VERSION "HNNBNNNYNNNNNNNNNNNNNNNNNNNNNNNNNNNNNNNNNN/4/%%%/4/'%**4NNN///"

NS_ :

BS_:

BU_: AWC BAP_Tester BMC_MLBevo BMS_MV BMS_NV DCDC_800V_PAG DCDC_HV DCDC_HV_02 DCDC_IHEV FCU_MLBevo_FCEV Gateway Gateway_PAG Ladegeraet_2 Ladegeraet_Konzern LE1 LE2 LE2_3_MLBevo_LB LE_MLBevo LE_MLBevo_LB Sub_Gateway TME

BO_ 3221225472 VECTOR__INDEPENDENT_SIG_MSG: 0 Vector__XXX
 SG_ DGN_Verlernzaehler : 0|8@1+ (1,0) [0|254] "" Vector__XXX
 SG_ KBI_Kilometerstand : 0|20@1+ (1,0) [0|1048573] "Unit_KiloMeter" Vector__XXX
 SG_ UH_Jahr : 0|7@1+ (1,2000) [2000|2127] "Unit_Year" Vector__XXX
 SG_ UH_Monat : 0|4@1+ (1,0) [1|12] "Unit_Month" Vector__XXX
 SG_ UH_Tag : 0|5@1+ (1,0) [1|31] "Unit_Day" Vector__XXX
 SG_ UH_Stunde : 0|5@1+ (1,0) [0|23] "Unit_Hours" Vector__XXX
 SG_ UH_Minute : 0|6@1+ (1,0) [0|59] "Unit_Minut" Vector__XXX
 SG_ UH_Sekunde : 0|6@1+ (1,0) [0|59] "Unit_Secon" Vector__XXX
 SG_ Kombi_02_alt : 0|1@1+ (1,0) [0|1] "" Vector__XXX
 SG_ Uhrzeit_01_alt : 0|1@1+ (1,0) [0|1] "" Vector__XXX
 SG_ EMG_CALID_CVN_MUX : 0|2@1+ (1,0) [0|3] "Unit_None" Vector__XXX
 SG_ EMG_CVN_VLD : 0|1@1+ (1,0) [0|1] "" Vector__XXX
 SG_ EMG_CALID_Index_01 : 0|8@1+ (1,0) [0|255] "" Vector__XXX
 SG_ EMG_CALID_Index_05 : 0|8@1+ (1,0) [0|255] "" Vector__XXX
 SG_ EMG_CALID_Index_09 : 0|8@1+ (1,0) [0|255] "" Vector__XXX
 SG_ EMG_CALID_Index_13 : 0|8@1+ (1,0) [0|255] "" Vector__XXX
 SG_ EMG_CALID_Index_02 : 0|8@1+ (1,0) [0|255] "" Vector__XXX
 SG_ EMG_CALID_Index_06 : 0|8@1+ (1,0) [0|255] "" Vector__XXX
 SG_ EMG_CALID_Index_10 : 0|8@1+ (1,0) [0|255] "" Vector__XXX
 SG_ EMG_CALID_Index_14 : 0|8@1+ (1,0) [0|255] "" Vector__XXX
 SG_ EMG_CALID_Index_03 : 0|8@1+ (1,0) [0|255] "" Vector__XXX
 SG_ EMG_CALID_Index_07 : 0|8@1+ (1,0) [0|255] "" Vector__XXX
 SG_ EMG_CALID_Index_11 : 0|8@1+ (1,0) [0|255] "" Vector__XXX
 SG_ EMG_CALID_Index_15 : 0|8@1+ (1,0) [0|255] "" Vector__XXX
 SG_ EMG_CALID_Index_04 : 0|8@1+ (1,0) [0|255] "" Vector__XXX
 SG_ EMG_CALID_Index_08 : 0|8@1+ (1,0) [0|255] "" Vector__XXX
 SG_ EMG_CALID_Index_12 : 0|8@1+ (1,0) [0|255] "" Vector__XXX
 SG_ EMG_CALID_Index_16 : 0|8@1+ (1,0) [0|255] "" Vector__XXX
 SG_ EMG_CVN_Byte_1 : 0|8@1+ (1,0) [0|255] "" Vector__XXX
 SG_ EMG_CVN_Byte_2 : 0|8@1+ (1,0) [0|255] "" Vector__XXX
 SG_ EMG_CVN_Byte_3 : 0|8@1+ (1,0) [0|255] "" Vector__XXX
 SG_ EMG_CVN_Byte_4 : 0|8@1+ (1,0) [0|255] "" Vector__XXX
 SG_ EMG_Komponentenfehler_01 : 0|2@1+ (1,0) [0|3] "" Vector__XXX
 SG_ EMG_Komponentenfehler_02 : 0|2@1+ (1,0) [0|3] "" Vector__XXX
 SG_ EMG_Komponentenfehler_03 : 0|2@1+ (1,0) [0|3] "" Vector__XXX
 SG_ EMG_Komponentenfehler_04 : 0|2@1+ (1,0) [0|3] "" Vector__XXX
 SG_ EMG_Komponentenfehler_05 : 0|2@1+ (1,0) [0|3] "" Vector__XXX
 SG_ EMG_Komponentenfehler_06 : 0|2@1+ (1,0) [0|3] "" Vector__XXX
 SG_ EMG_Komponentenfehler_07 : 0|2@1+ (1,0) [0|3] "" Vector__XXX
 SG_ EMG_Komponentenfehler_08 : 0|2@1+ (1,0) [0|3] "" Vector__XXX
 SG_ EMG_Komponentenfehler_09 : 0|2@1+ (1,0) [0|3] "" Vector__XXX
 SG_ EMG_Komponentenfehler_VLD : 0|1@1+ (1,0) [0|1] "" Vector__XXX
 SG_ ESP_21_CRC : 0|8@1+ (1,0) [0|255] "" Vector__XXX
 SG_ ESP_21_BZ : 0|4@1+ (1,0) [0|15] "" Vector__XXX
 SG_ BR_Eingriffsmoment : 0|10@1+ (1,-509) [-509|509] "" Vector__XXX
 SG_ ESP_Diagnose : 0|1@1+ (1,0) [0|1] "" Vector__XXX
 SG_ ESC_v_Signal_Qualifier_High_Low : 0|3@1+ (1,0) [0|7] "" Vector__XXX
 SG_ ESP_Vorsteuerung : 0|1@1+ (1,0) [0|1] "" Vector__XXX
 SG_ OBD_Schlechtweg : 0|1@1+ (1,0) [0|1] "" Vector__XXX
 SG_ OBD_QBit_Schlechtweg : 0|1@1+ (1,0) [0|1] "" Vector__XXX
 SG_ ESP_v_Signal : 0|16@1+ (0.01,0) [0|655.32] "Unit_KiloMeterPerHour" Vector__XXX
 SG_ ASR_Tastung_passiv : 0|1@1+ (1,0) [0|1] "" Vector__XXX
 SG_ ESP_Tastung_passiv : 0|1@1+ (1,0) [0|1] "" Vector__XXX
 SG_ ESP_Systemstatus : 0|1@1+ (1,0) [0|1] "" Vector__XXX
 SG_ ASR_Schalteingriff : 0|2@1+ (1,0) [0|3] "" Vector__XXX
 SG_ ESP_QBit_v_Signal : 0|1@1+ (1,0) [0|1] "" Vector__XXX
 SG_ ABS_Bremsung : 0|1@1+ (1,0) [0|1] "" Vector__XXX
 SG_ ASR_Anf : 0|1@1+ (1,0) [0|1] "" Vector__XXX
 SG_ MSR_Anf : 0|1@1+ (1,0) [0|1] "" Vector__XXX
 SG_ EBV_Eingriff : 0|1@1+ (1,0) [0|1] "" Vector__XXX
 SG_ EDS_Eingriff : 0|1@1+ (1,0) [0|1] "" Vector__XXX
 SG_ ESP_Eingriff : 0|1@1+ (1,0) [0|1] "" Vector__XXX
 SG_ ESP_ASP : 0|1@1+ (1,0) [0|1] "" Vector__XXX
 SG_ ESC_Neutralschaltung : 0|1@1+ (1,0) [0|1] "" Vector__XXX
 SG_ SI_Sammel_SG_Fehler : 0|6@1+ (1,0) [0|60] "" Vector__XXX
 SG_ SI_Diagnose_Aktiv : 0|1@1+ (1,0) [0|1] "" Vector__XXX
 SG_ SI_QRS_Mode : 0|1@1+ (1,0) [0|1] "" Vector__XXX
 SG_ SI_T_Mode : 0|1@1+ (1,0) [0|1] "" Vector__XXX
 SG_ SI_NWDF : 0|1@1+ (1,0) [0|1] "" Vector__XXX
 SG_ SI_NWDF_gueltig : 0|1@1+ (1,0) [0|1] "" Vector__XXX
 SG_ SI_Sammelfehler : 0|1@1+ (1,0) [0|1] "" Vector__XXX
 SG_ GW_KD_Fehler : 0|1@1+ (1,0) [0|1] "" Vector__XXX
 SG_ SI_T_Schutz : 0|1@1+ (1,0) [0|1] "" Vector__XXX
 SG_ SI_BUS_01 : 0|1@1+ (1,0) [0|1] "" Vector__XXX
 SG_ SI_BUS_02 : 0|1@1+ (1,0) [0|1] "" Vector__XXX
 SG_ SI_BUS_03 : 0|1@1+ (1,0) [0|1] "" Vector__XXX
 SG_ SI_BUS_04 : 0|1@1+ (1,0) [0|1] "" Vector__XXX
 SG_ SI_BUS_05 : 0|1@1+ (1,0) [0|1] "" Vector__XXX
 SG_ SI_BUS_06 : 0|1@1+ (1,0) [0|1] "" Vector__XXX
 SG_ SI_BUS_07 : 0|1@1+ (1,0) [0|1] "" Vector__XXX
 SG_ SI_BUS_08 : 0|1@1+ (1,0) [0|1] "" Vector__XXX
 SG_ SI_BUS_09 : 0|1@1+ (1,0) [0|1] "" Vector__XXX
 SG_ SI_BUS_10 : 0|1@1+ (1,0) [0|1] "" Vector__XXX
 SG_ SI_BUS_11 : 0|1@1+ (1,0) [0|1] "" Vector__XXX
 SG_ SI_BUS_12 : 0|1@1+ (1,0) [0|1] "" Vector__XXX
 SG_ SI_BUS_13 : 0|1@1+ (1,0) [0|1] "" Vector__XXX
 SG_ SI_BUS_14 : 0|1@1+ (1,0) [0|1] "" Vector__XXX
 SG_ SI_BUS_15 : 0|1@1+ (1,0) [0|1] "" Vector__XXX
 SG_ SI_Bus_Identifikation : 0|8@1+ (1,0) [0|255] "" Vector__XXX
 SG_ SI_CAB : 0|24@1+ (1,0) [0|16777215] "" Vector__XXX
 SG_ XCP_BMS_MV_CRO_01_Data : 0|64@1+ (1,0) [0|1] "" Vector__XXX

BO_ 64 Airbag_01: 8 Gateway
 SG_ Airbag_01_CRC : 0|8@1+ (1,0) [0|255] ""  AWC,BMC_MLBevo,BMS_NV,DCDC_800V_PAG,DCDC_HV,DCDC_HV_02,DCDC_IHEV,FCU_MLBevo_FCEV,Ladegeraet_2,Ladegeraet_Konzern,Sub_Gateway
 SG_ Airbag_01_BZ : 8|4@1+ (1,0) [0|15] ""  AWC,BMC_MLBevo,BMS_NV,DCDC_800V_PAG,DCDC_HV,DCDC_HV_02,DCDC_IHEV,FCU_MLBevo_FCEV,Ladegeraet_2,Ladegeraet_Konzern,Sub_Gateway
 SG_ AB_RGS_Anst : 12|4@1+ (1,0) [0|15] ""  FCU_MLBevo_FCEV,Sub_Gateway
 SG_ AB_Front_Crash : 16|1@1+ (1,0) [0|1] ""  FCU_MLBevo_FCEV,Sub_Gateway
 SG_ AB_Heck_Crash : 17|1@1+ (1,0) [0|1] ""  FCU_MLBevo_FCEV,Sub_Gateway
 SG_ AB_SF_Crash : 18|1@1+ (1,0) [0|1] ""  FCU_MLBevo_FCEV,Sub_Gateway
 SG_ AB_SB_Crash : 19|1@1+ (1,0) [0|1] ""  FCU_MLBevo_FCEV,Sub_Gateway
 SG_ AB_Rollover_Crash : 20|1@1+ (1,0) [0|1] ""  FCU_MLBevo_FCEV,Sub_Gateway
 SG_ AB_Crash_Int : 21|3@1+ (1,0) [0|7] ""  FCU_MLBevo_FCEV,Sub_Gateway,TME
 SG_ AB_Lampe : 24|1@1+ (1,0) [0|1] ""  FCU_MLBevo_FCEV,Sub_Gateway
 SG_ AB_Deaktiviert : 25|1@1+ (1,0) [0|1] ""  FCU_MLBevo_FCEV,Sub_Gateway
 SG_ AB_VB_deaktiviert : 26|1@1+ (1,0) [0|1] ""  FCU_MLBevo_FCEV,Sub_Gateway
 SG_ AB_Systemfehler : 27|1@1+ (1,0) [0|1] ""  FCU_MLBevo_FCEV,Sub_Gateway
 SG_ AB_Diagnose : 28|1@1+ (1,0) [0|1] ""  FCU_MLBevo_FCEV,Sub_Gateway
 SG_ AB_Stellgliedtest : 29|1@1+ (1,0) [0|1] ""  FCU_MLBevo_FCEV,Sub_Gateway,TME
 SG_ AB_Erh_Auf_VB : 30|2@1+ (1,0) [0|3] ""  FCU_MLBevo_FCEV,Sub_Gateway
 SG_ AB_Gurtwarn_VF : 32|1@1+ (1,0) [0|1] ""  FCU_MLBevo_FCEV,Sub_Gateway
 SG_ AB_Gurtwarn_VB : 33|1@1+ (1,0) [0|1] ""  FCU_MLBevo_FCEV,Sub_Gateway
 SG_ AB_Anzeige_Fussg : 34|2@1+ (1,0) [0|3] ""  FCU_MLBevo_FCEV,Sub_Gateway
 SG_ AB_Texte_AKS : 36|2@1+ (1,0) [0|3] ""  FCU_MLBevo_FCEV,Sub_Gateway
 SG_ AB_MKB_gueltig : 39|1@1+ (1,0) [0|1] ""  FCU_MLBevo_FCEV,Sub_Gateway
 SG_ AB_MKB_Anforderung : 40|1@1+ (1,0) [0|1] ""  FCU_MLBevo_FCEV,Sub_Gateway
 SG_ AB_Versorgungsspannung : 41|1@1+ (1,0) [0|1] ""  FCU_MLBevo_FCEV,Sub_Gateway
 SG_ AB_Deaktivierung_HV : 42|3@1+ (1,0) [0|7] ""  AWC,BMC_MLBevo,BMS_NV,DCDC_800V_PAG,DCDC_HV,DCDC_HV_02,DCDC_IHEV,FCU_MLBevo_FCEV,Ladegeraet_2,Ladegeraet_Konzern,Sub_Gateway,TME
 SG_ AB_EDR_Trigger : 45|2@1+ (1,0) [0|3] ""  FCU_MLBevo_FCEV,Sub_Gateway
 SG_ AB_Belegung_VF : 47|2@1+ (1,0) [0|3] ""  FCU_MLBevo_FCEV,Sub_Gateway
 SG_ SC_Masterzeit_Offset : 53|2@1+ (5.08,0) [0|15.24] "Unit_Secon"  FCU_MLBevo_FCEV,Sub_Gateway
 SG_ SC_LowSpeedCrashErkannt : 55|2@1+ (1,0) [0|3] ""  FCU_MLBevo_FCEV,Sub_Gateway
 SG_ SC_Masterzeit : 57|7@1+ (0.04,0) [0|5.04] "Unit_Secon"  FCU_MLBevo_FCEV,Sub_Gateway

BO_ 2589283757 Authentic_Time_01: 8 Gateway
 SG_ AT_VALID_TIME : 32|32@1+ (1,0) [1|4294967295] ""  Ladegeraet_Konzern

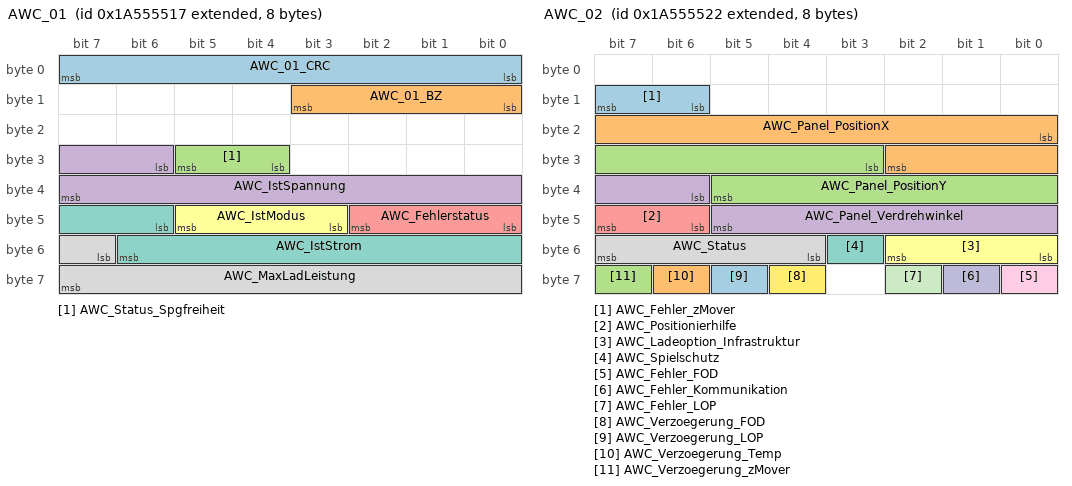
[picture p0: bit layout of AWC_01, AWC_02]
BO_ 2589283607 AWC_01: 8 AWC
 SG_ AWC_01_CRC : 0|8@1+ (1,0) [0|255] ""  Gateway,Gateway_PAG
 SG_ AWC_01_BZ : 8|4@1+ (1,0) [0|15] ""  Gateway,Gateway_PAG
 SG_ AWC_Status_Spgfreiheit : 28|2@1+ (1,0) [0|3] ""  Gateway,Gateway_PAG
 SG_ AWC_IstSpannung : 30|10@1+ (1,0) [0|1021] "Unit_Volt"  Gateway,Gateway_PAG,Ladegeraet_Konzern
 SG_ AWC_Fehlerstatus : 40|3@1+ (1,0) [0|7] ""  Gateway,Gateway_PAG
 SG_ AWC_IstModus : 43|3@1+ (1,0) [0|7] ""  Gateway,Gateway_PAG,Ladegeraet_Konzern,TME
 SG_ AWC_IstStrom : 46|9@1+ (0.1,0) [0|50.9] "Unit_Amper"  Ladegeraet_Konzern
 SG_ AWC_MaxLadLeistung : 55|9@1+ (25,0) [0|12725] "Unit_Watt"  Ladegeraet_Konzern

BO_ 2589283618 AWC_02: 8 AWC
 SG_ AWC_Fehler_zMover : 14|2@1+ (1,0) [0|3] ""  Gateway,Gateway_PAG,Ladegeraet_Konzern
 SG_ AWC_Panel_PositionX : 16|11@1+ (1,-1000) [-1000|1000] "Unit_Centimeter"  Gateway,Gateway_PAG
 SG_ AWC_Panel_PositionY : 27|11@1+ (1,-1000) [-1000|1000] "Unit_Centimeter"  Gateway,Gateway_PAG
 SG_ AWC_Panel_Verdrehwinkel : 38|8@1+ (1.5,0) [0|360] "Unit_DegreOfArc"  Gateway,Gateway_PAG
 SG_ AWC_Positionierhilfe : 46|2@1+ (1,0) [0|3] ""  Gateway,Gateway_PAG
 SG_ AWC_Ladeoption_Infrastruktur : 48|3@1+ (1,0) [0|7] ""  Gateway,Gateway_PAG,Ladegeraet_Konzern
 SG_ AWC_Spielschutz : 51|1@1+ (1,0) [0|1] ""  Gateway,Gateway_PAG,Ladegeraet_Konzern
 SG_ AWC_Status : 52|4@1+ (1,0) [0|15] ""  Gateway,Gateway_PAG,Ladegeraet_Konzern
 SG_ AWC_Fehler_FOD : 56|1@1+ (1,0) [0|1] ""  Gateway,Gateway_PAG,Ladegeraet_Konzern
 SG_ AWC_Fehler_Kommunikation : 57|1@1+ (1,0) [0|1] ""  Gateway,Gateway_PAG,Ladegeraet_Konzern
 SG_ AWC_Fehler_LOP : 58|1@1+ (1,0) [0|1] ""  Gateway,Gateway_PAG,Ladegeraet_Konzern
 SG_ AWC_Verzoegerung_FOD : 60|1@1+ (1,0) [0|1] ""  Gateway,Gateway_PAG,Ladegeraet_Konzern
 SG_ AWC_Verzoegerung_LOP : 61|1@1+ (1,0) [0|1] ""  Gateway,Gateway_PAG,Ladegeraet_Konzern
 SG_ AWC_Verzoegerung_Temp : 62|1@1+ (1,0) [0|1] ""  Gateway,Gateway_PAG,Ladegeraet_Konzern
 SG_ AWC_Verzoegerung_zMover : 63|1@1+ (1,0) [0|1] ""  Gateway,Gateway_PAG,Ladegeraet_Konzern

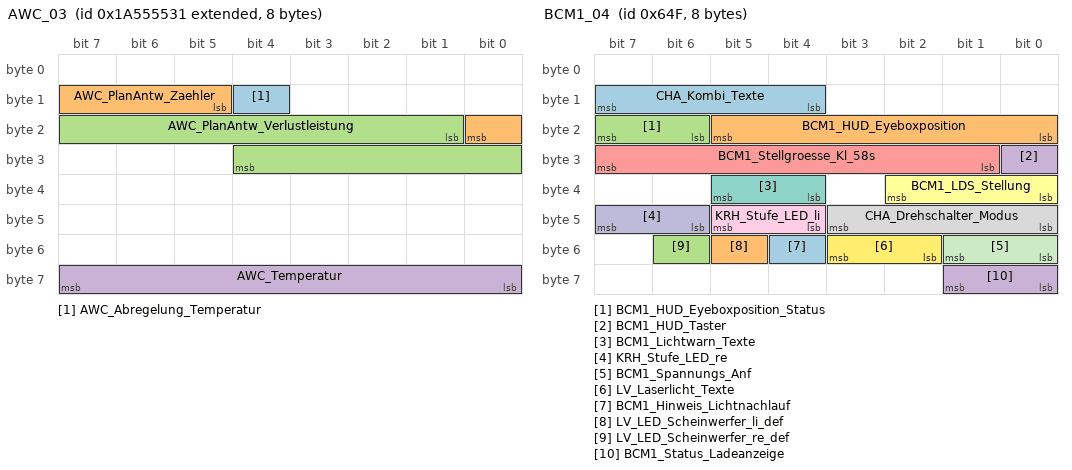
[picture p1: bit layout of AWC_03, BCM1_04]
BO_ 2589283633 AWC_03: 8 AWC
 SG_ AWC_Abregelung_Temperatur : 12|1@1+ (1,0) [0|1] ""  TME
 SG_ AWC_PlanAntw_Zaehler : 13|4@1+ (1,0) [0|13] "Unit_None"  Ladegeraet_Konzern,TME
 SG_ AWC_PlanAntw_Verlustleistung : 17|12@1+ (50,0) [0|204650] "Unit_Watt"  Ladegeraet_Konzern,TME
 SG_ AWC_Temperatur : 56|8@1+ (1,-40) [-40|213] "Unit_DegreCelsi"  TME

BO_ 2589283685 AWC_CALID_CVN: 8 AWC
 SG_ AWC_CALID_CVN_MUX M : 0|2@1+ (1,0) [0|3] "Unit_None"  BMC_MLBevo
 SG_ AWC_CVN_VLD : 7|1@1+ (1,0) [0|1] ""  BMC_MLBevo
 SG_ AWC_CALID_Index_01 m0 : 8|8@1+ (1,0) [0|255] ""  BMC_MLBevo
 SG_ AWC_CALID_Index_05 m1 : 8|8@1+ (1,0) [0|255] ""  BMC_MLBevo
 SG_ AWC_CALID_Index_09 m2 : 8|8@1+ (1,0) [0|255] ""  BMC_MLBevo
 SG_ AWC_CALID_Index_13 m3 : 8|8@1+ (1,0) [0|255] ""  BMC_MLBevo
 SG_ AWC_CALID_Index_02 m0 : 16|8@1+ (1,0) [0|255] ""  BMC_MLBevo
 SG_ AWC_CALID_Index_06 m1 : 16|8@1+ (1,0) [0|255] ""  BMC_MLBevo
 SG_ AWC_CALID_Index_10 m2 : 16|8@1+ (1,0) [0|255] ""  BMC_MLBevo
 SG_ AWC_CALID_Index_14 m3 : 16|8@1+ (1,0) [0|255] ""  BMC_MLBevo
 SG_ AWC_CALID_Index_03 m0 : 24|8@1+ (1,0) [0|255] ""  BMC_MLBevo
 SG_ AWC_CALID_Index_07 m1 : 24|8@1+ (1,0) [0|255] ""  BMC_MLBevo
 SG_ AWC_CALID_Index_11 m2 : 24|8@1+ (1,0) [0|255] ""  BMC_MLBevo
 SG_ AWC_CALID_Index_15 m3 : 24|8@1+ (1,0) [0|255] ""  BMC_MLBevo
 SG_ AWC_CALID_Index_04 m0 : 32|8@1+ (1,0) [0|255] ""  BMC_MLBevo
 SG_ AWC_CALID_Index_08 m1 : 32|8@1+ (1,0) [0|255] ""  BMC_MLBevo
 SG_ AWC_CALID_Index_12 m2 : 32|8@1+ (1,0) [0|255] ""  BMC_MLBevo
 SG_ AWC_CALID_Index_16 m3 : 32|8@1+ (1,0) [0|255] ""  BMC_MLBevo
 SG_ AWC_CVN_Byte_1 m0 : 40|8@1+ (1,0) [0|255] ""  BMC_MLBevo
 SG_ AWC_CVN_Byte_2 m1 : 40|8@1+ (1,0) [0|255] ""  BMC_MLBevo
 SG_ AWC_CVN_Byte_3 m2 : 40|8@1+ (1,0) [0|255] ""  BMC_MLBevo
 SG_ AWC_CVN_Byte_4 m3 : 40|8@1+ (1,0) [0|255] ""  BMC_MLBevo

BO_ 2589283394 AWC_Komponentenfehler: 8 AWC
 SG_ AWC_Komponentenfehler_01 : 0|2@1+ (1,0) [0|3] ""  BMC_MLBevo
 SG_ AWC_Komponentenfehler_02 : 2|2@1+ (1,0) [0|3] ""  BMC_MLBevo
 SG_ AWC_Komponentenfehler_03 : 4|2@1+ (1,0) [0|3] ""  BMC_MLBevo
 SG_ AWC_Komponentenfehler_04 : 6|2@1+ (1,0) [0|3] ""  BMC_MLBevo
 SG_ AWC_Komponentenfehler_05 : 8|2@1+ (1,0) [0|3] ""  BMC_MLBevo
 SG_ AWC_Komponentenfehler_06 : 10|2@1+ (1,0) [0|3] ""  BMC_MLBevo
 SG_ AWC_Komponentenfehler_07 : 12|2@1+ (1,0) [0|3] ""  BMC_MLBevo
 SG_ AWC_Komponentenfehler_08 : 14|2@1+ (1,0) [0|3] ""  BMC_MLBevo
 SG_ AWC_Komponentenfehler_09 : 16|2@1+ (1,0) [0|3] ""  BMC_MLBevo
 SG_ AWC_Komponentenfehler_10 : 18|2@1+ (1,0) [0|3] ""  BMC_MLBevo
 SG_ AWC_Komponentenfehler_11 : 20|2@1+ (1,0) [0|3] ""  BMC_MLBevo
 SG_ AWC_Komponentenfehler_12 : 22|2@1+ (1,0) [0|3] ""  BMC_MLBevo
 SG_ AWC_Komponentenfehler_13 : 24|2@1+ (1,0) [0|3] ""  BMC_MLBevo
 SG_ AWC_Komponentenfehler_14 : 26|2@1+ (1,0) [0|3] ""  BMC_MLBevo
 SG_ AWC_Komponentenfehler_15 : 28|2@1+ (1,0) [0|3] ""  BMC_MLBevo
 SG_ AWC_Komponentenfehler_16 : 30|2@1+ (1,0) [0|3] ""  BMC_MLBevo
 SG_ AWC_Komponentenfehler_17 : 32|2@1+ (1,0) [0|3] ""  BMC_MLBevo
 SG_ AWC_Komponentenfehler_18 : 34|2@1+ (1,0) [0|3] ""  BMC_MLBevo
 SG_ AWC_Komponentenfehler_19 : 36|2@1+ (1,0) [0|3] ""  BMC_MLBevo
 SG_ AWC_Komponentenfehler_20 : 38|2@1+ (1,0) [0|3] ""  BMC_MLBevo
 SG_ AWC_Komponentenfehler_21 : 40|2@1+ (1,0) [0|3] ""  BMC_MLBevo
 SG_ AWC_Komponentenfehler_22 : 42|2@1+ (1,0) [0|3] ""  BMC_MLBevo
 SG_ AWC_Komponentenfehler_23 : 44|2@1+ (1,0) [0|3] ""  BMC_MLBevo
 SG_ AWC_Komponentenfehler_24 : 46|2@1+ (1,0) [0|3] ""  BMC_MLBevo
 SG_ AWC_Komponentenfehler_25 : 48|2@1+ (1,0) [0|3] ""  BMC_MLBevo
 SG_ AWC_Komponentenfehler_26 : 50|2@1+ (1,0) [0|3] ""  BMC_MLBevo
 SG_ AWC_Komponentenfehler_27 : 52|2@1+ (1,0) [0|3] ""  BMC_MLBevo
 SG_ AWC_Komponentenfehler_28 : 54|2@1+ (1,0) [0|3] ""  BMC_MLBevo
 SG_ AWC_Komponentenfehler_29 : 56|2@1+ (1,0) [0|3] ""  BMC_MLBevo
 SG_ AWC_Komponentenfehler_30 : 58|2@1+ (1,0) [0|3] ""  BMC_MLBevo
 SG_ AWC_Komponentenfehler_31 : 60|2@1+ (1,0) [0|3] ""  BMC_MLBevo
 SG_ AWC_Komponentenfehler_VLD : 63|1@1+ (1,0) [0|1] ""  BMC_MLBevo

BO_ 2536720384 BAP_AWC_ASG_01: 8 Gateway
 SG_ BAP_AWC_ASG_01_Header : 0|8@1+ (1,0) [0|255] "Unit_None"  AWC

BO_ 2536720385 BAP_AWC_ASG_02: 8 Gateway
 SG_ BAP_AWC_ASG_02_Header : 0|64@1+ (1,0) [0|1.84467440737096E+019] ""  AWC

BO_ 2536720400 BAP_AWC_FSG_01: 8 AWC
 SG_ BAP_AWC_FSG_01_Header : 0|8@1+ (1,0) [0|255] "Unit_None"  Gateway,Gateway_PAG

BO_ 2536711424 BAP_BatteryControl_ASG_01: 8 Gateway
 SG_ BAP_BatteryControl_ASG_01_Header : 0|8@1+ (1,0) [0|255] ""  Ladegeraet_Konzern

BO_ 2536711425 BAP_BatteryControl_ASG_02: 8 Gateway
 SG_ BAP_BatteryControl_ASG_02_Header : 0|8@1+ (1,0) [0|255] ""  Ladegeraet_Konzern

BO_ 2536711426 BAP_BatteryControl_ASG_03: 8 Gateway
 SG_ BAP_BatteryControl_ASG_03_Header : 0|8@1+ (1,0) [0|255] ""  Ladegeraet_Konzern

BO_ 2536711427 BAP_BatteryControl_ASG_04: 8 Gateway
 SG_ BAP_BatteryControl_ASG_04_Header : 0|8@1+ (1,0) [0|255] ""  Ladegeraet_Konzern

BO_ 2536711428 BAP_BatteryControl_ASG_05: 8 AWC
 SG_ BAP_BatteryControl_ASG_05_Header : 0|8@1+ (1,0) [0|255] "Unit_None"  Ladegeraet_Konzern

BO_ 2536711429 BAP_BatteryControl_ASG_06: 8 Gateway
 SG_ BAP_BatteryControl_ASG_06_Header : 0|8@1+ (1,0) [0|255] ""  Ladegeraet_Konzern

BO_ 2536711440 BAP_BatteryControl_FSG_01: 8 Ladegeraet_Konzern
 SG_ BAP_BatteryControl_FSG_01_Header : 0|8@1+ (1,0) [0|255] ""  AWC,Gateway,Gateway_PAG

BO_ 2536767264 BAP_Debug_Cmd: 8 BAP_Tester
 SG_ BAP_Debug_Cmd : 0|16@1+ (1,0) [0|65535] ""  AWC,Gateway,Gateway_PAG,Ladegeraet_Konzern

BO_ 2536767280 BAP_Debug_Data: 8 AWC
 SG_ BAP_Debug_Data : 0|64@1+ (1,0) [0|1.84467440737096E+019] ""  BAP_Tester

BO_ 2536706306 BAP_Uhrzeit_ASG_03: 8 Ladegeraet_Konzern
 SG_ BAP_Uhrzeit_ASG_03_Header : 0|8@1+ (1,0) [0|255] ""  Gateway,Gateway_PAG

BO_ 2536706310 BAP_Uhrzeit_ASG_07: 8 AWC
 SG_ BAP_Uhrzeit_ASG_07_Header : 0|64@1+ (1,0) [0|1.84467440737096E+019] ""  Gateway,Gateway_PAG

BO_ 2536706320 BAP_Uhrzeit_FSG_01: 8 Gateway
 SG_ BAP_Uhrzeit_FSG_01_Header : 0|8@1+ (1,0) [0|255] ""  AWC,Ladegeraet_Konzern

BO_ 1615 BCM1_04: 8 Gateway
 SG_ CHA_Kombi_Texte : 12|4@1+ (1,0) [0|15] "" Vector__XXX
 SG_ BCM1_HUD_Eyeboxposition : 16|6@1+ (1,0) [0|63] "" Vector__XXX
 SG_ BCM1_HUD_Eyeboxposition_Status : 22|2@1+ (1,0) [0|3] "" Vector__XXX
 SG_ BCM1_HUD_Taster : 24|1@1+ (1,0) [0|1] "" Vector__XXX
 SG_ BCM1_Stellgroesse_Kl_58s : 25|7@1+ (1,0) [0|100] "" Vector__XXX
 SG_ BCM1_LDS_Stellung : 32|3@1+ (1,0) [0|7] "" Vector__XXX
 SG_ BCM1_Lichtwarn_Texte : 36|2@1+ (1,0) [0|3] "" Vector__XXX
 SG_ CHA_Drehschalter_Modus : 40|4@1+ (1,0) [0|15] "" Vector__XXX
 SG_ KRH_Stufe_LED_li : 44|2@1+ (1,0) [0|3] "" Vector__XXX
 SG_ KRH_Stufe_LED_re : 46|2@1+ (1,0) [0|3] "" Vector__XXX
 SG_ BCM1_Spannungs_Anf : 48|2@1+ (1,0) [0|3] "" Vector__XXX
 SG_ LV_Laserlicht_Texte : 50|2@1+ (1,0) [0|3] "" Vector__XXX
 SG_ BCM1_Hinweis_Lichtnachlauf : 52|1@1+ (1,0) [0|1] "" Vector__XXX
 SG_ LV_LED_Scheinwerfer_li_def : 53|1@1+ (1,0) [0|1] "" Vector__XXX
 SG_ LV_LED_Scheinwerfer_re_def : 54|1@1+ (1,0) [0|1] "" Vector__XXX
 SG_ BCM1_Status_Ladeanzeige : 56|2@1+ (1,0) [0|3] ""  Ladegeraet_Konzern

BO_ 1626 BCM_01: 8 Gateway
 SG_ BCM_Bremsbelag_Sensor : 12|1@1+ (1,0) [0|1] "" Vector__XXX
 SG_ BCM_Bremsfluessigkeit_Sensor : 13|1@1+ (1,0) [0|1] "" Vector__XXX
 SG_ BCM1_Licht_Warn : 14|1@1+ (1,0) [0|1] "" Vector__XXX
 SG_ BCM_Waschwasser_Sensor : 15|1@1+ (1,0) [0|1] "" Vector__XXX
 SG_ BCM_Kuehlmittel_Sensor : 16|1@1+ (1,0) [0|1] ""  TME
 SG_ BCM1_Kl_15_HW_erkannt : 17|1@1+ (1,0) [0|1] "" Vector__XXX
 SG_ BCM1_Kl_15_Sig_HW_erkannt : 18|1@1+ (1,0) [0|1] "" Vector__XXX
 SG_ BCM_Kuehlmittel_Sensor_02 : 19|1@1+ (1,0) [0|1] ""  TME
 SG_ BCM1_Hinweis_Lichtnachlauf : 20|1@1+ (1,0) [0|1] "" Vector__XXX
 SG_ BCM_Offroad_Taste : 21|1@1+ (1,0) [0|1] "" Vector__XXX
 SG_ BCM_Hybrid_StSt_Taste_Fehler : 23|1@1+ (1,0) [0|1] "" Vector__XXX
 SG_ BCM_Hybrid_StartStopp_Taste : 24|1@1+ (1,0) [0|1] "" Vector__XXX
 SG_ BCM1_Warnblink_Taster : 25|1@1+ (1,0) [0|1] "" Vector__XXX
 SG_ BCM1_Valet_Parking_Taster : 26|1@1+ (1,0) [0|1] "" Vector__XXX
 SG_ BCM1_LDS_Stellung : 27|3@1+ (1,0) [0|7] "" Vector__XXX
 SG_ BCM1_Rueckfahrlicht_Schalter : 30|1@1+ (1,0) [0|1] "" Vector__XXX
 SG_ BCM1_MH_Schalter : 31|1@1+ (1,0) [0|1] "" Vector__XXX
 SG_ BCM1_MH_WIV_Schalter : 32|1@1+ (1,0) [0|1] "" Vector__XXX
 SG_ BCM_Eco_Charisma_Taste : 33|1@1+ (1,0) [0|1] "" Vector__XXX
 SG_ BCM1_NV_Taster : 34|1@1+ (1,0) [0|1] "" Vector__XXX
 SG_ BCM1_AFS_Lampe : 35|1@1+ (1,0) [0|1] "" Vector__XXX
 SG_ BCM1_Reisemodus_Texte : 36|2@1+ (1,0) [0|3] "" Vector__XXX
 SG_ BCM1_Lichtwarn_Texte : 38|2@1+ (1,0) [0|3] "" Vector__XXX
 SG_ Gong_TFL_Umschaltung : 40|1@1+ (1,0) [0|1] "" Vector__XXX
 SG_ UGDO_Function_01 : 41|3@1+ (1,0) [0|7] "" Vector__XXX
 SG_ APS_Tongeber_defekt : 44|1@1+ (1,0) [0|1] "" Vector__XXX
 SG_ BCM1_EasyEntry_Status : 45|1@1+ (1,0) [0|1] "" Vector__XXX
 SG_ BCM1_Lenksaeule_aktiv : 46|1@1+ (1,0) [0|1] "" Vector__XXX
 SG_ BCM1_St_SW_Diebstahl_links : 47|1@1+ (1,0) [0|1] "" Vector__XXX
 SG_ BCM1_St_SW_Diebstahl_rechts : 48|1@1+ (1,0) [0|1] "" Vector__XXX
 SG_ ISP_Dimmung_ASP_02 : 49|6@1+ (0.0226,0) [0|1.4012] "Unit_Volt" Vector__XXX
 SG_ BCM1_Schluesselsuche_Anf : 55|1@1+ (1,0) [0|1] "" Vector__XXX
 SG_ BCM1_Fahrlicht_Hinweis : 62|1@1+ (1,0) [0|1] "" Vector__XXX
 SG_ BCM_HDF_betaetigt : 63|1@1+ (1,0) [0|1] "" Vector__XXX

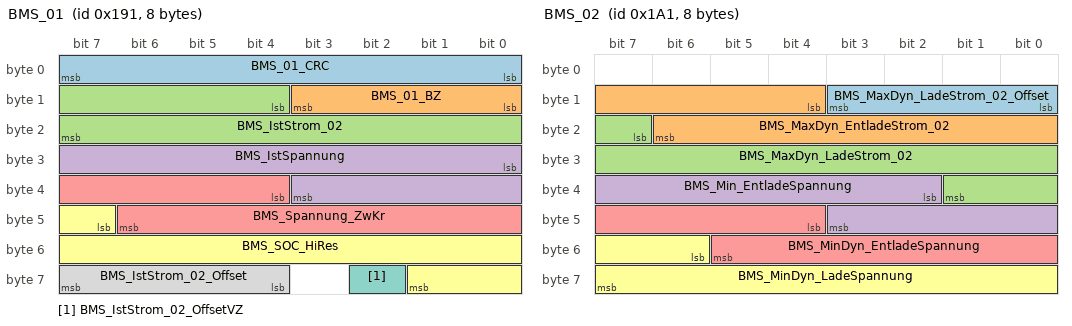
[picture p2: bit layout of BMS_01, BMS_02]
BO_ 401 BMS_01: 8 BMC_MLBevo
 SG_ BMS_01_CRC : 0|8@1+ (1,0) [0|255] ""  Gateway,Gateway_PAG,Sub_Gateway
 SG_ BMS_01_BZ : 8|4@1+ (1,0) [0|15] ""  Gateway,Gateway_PAG,Sub_Gateway
 SG_ BMS_IstStrom_02 : 12|12@1+ (1,-2047) [-2047|2046] "Unit_Amper"  Gateway,Gateway_PAG,Ladegeraet_Konzern,LE1,LE2,LE2_3_MLBevo_LB,Sub_Gateway,TME
 SG_ BMS_IstSpannung : 24|12@1+ (0.25,0) [0|1023.25] "Unit_Volt"  AWC,Gateway,Gateway_PAG,Ladegeraet_2,Ladegeraet_Konzern,LE1,LE2,LE2_3_MLBevo_LB,Sub_Gateway,TME
 SG_ BMS_Spannung_ZwKr : 36|11@1+ (0.5,0) [0|1022.5] "Unit_Volt"  Gateway,Gateway_PAG,LE1,LE2,LE2_3_MLBevo_LB,Sub_Gateway,TME
 SG_ BMS_SOC_HiRes : 47|11@1+ (0.05,0) [0|100] "Unit_PerCent"  Gateway,Gateway_PAG,Ladegeraet_Konzern,Sub_Gateway,TME
 SG_ BMS_IstStrom_02_OffsetVZ : 58|1@1+ (1,0) [0|1] ""  Gateway,Gateway_PAG,Ladegeraet_Konzern,Sub_Gateway
 SG_ BMS_IstStrom_02_Offset : 60|4@1+ (0.0625,0) [0|0.9375] "Unit_Amper"  Gateway,Gateway_PAG,Ladegeraet_Konzern,Sub_Gateway

BO_ 417 BMS_02: 8 BMC_MLBevo
 SG_ BMS_MaxDyn_LadeStrom_02_Offset : 8|4@1+ (0.0625,0) [0|0.9375] "Unit_Amper"  FCU_MLBevo_FCEV,Gateway,Gateway_PAG,Ladegeraet_Konzern
 SG_ BMS_MaxDyn_EntladeStrom_02 : 12|11@1+ (1,0) [0|2045] "Unit_Amper"  FCU_MLBevo_FCEV,Gateway,Gateway_PAG,LE2_3_MLBevo_LB
 SG_ BMS_MaxDyn_LadeStrom_02 : 23|11@1+ (1,0) [0|2045] "Unit_Amper"  FCU_MLBevo_FCEV,Gateway,Gateway_PAG,Ladegeraet_Konzern,LE2_3_MLBevo_LB
 SG_ BMS_Min_EntladeSpannung : 34|10@1+ (1,0) [0|1021] "Unit_Volt"  FCU_MLBevo_FCEV,Gateway,Gateway_PAG,Ladegeraet_Konzern,LE2_3_MLBevo_LB
 SG_ BMS_MinDyn_EntladeSpannung : 44|10@1+ (1,0) [0|1022] "Unit_Volt"  FCU_MLBevo_FCEV,Gateway,Gateway_PAG,LE2_3_MLBevo_LB
 SG_ BMS_MinDyn_LadeSpannung : 54|10@1+ (1,0) [0|1022] "Unit_Volt"  FCU_MLBevo_FCEV,Gateway,Gateway_PAG,LE2_3_MLBevo_LB

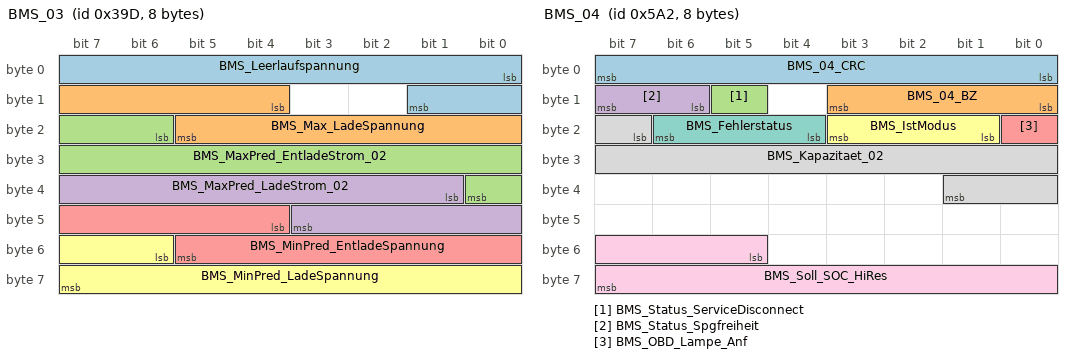
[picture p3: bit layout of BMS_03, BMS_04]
BO_ 925 BMS_03: 8 BMC_MLBevo
 SG_ BMS_Leerlaufspannung : 0|10@1+ (1,0) [0|1022] "Unit_Volt"  FCU_MLBevo_FCEV,Gateway,Gateway_PAG
 SG_ BMS_Max_LadeSpannung : 12|10@1+ (1,0) [0|1021] "Unit_Volt"  AWC,FCU_MLBevo_FCEV,Gateway,Gateway_PAG,Ladegeraet_2,Ladegeraet_Konzern,LE2_3_MLBevo_LB
 SG_ BMS_MaxPred_EntladeStrom_02 : 22|11@1+ (1,0) [0|2045] "Unit_Amper"  FCU_MLBevo_FCEV,Gateway,Gateway_PAG,LE2_3_MLBevo_LB
 SG_ BMS_MaxPred_LadeStrom_02 : 33|11@1+ (1,0) [0|2045] "Unit_Amper"  FCU_MLBevo_FCEV,Gateway,Gateway_PAG,Ladegeraet_Konzern,LE2_3_MLBevo_LB
 SG_ BMS_MinPred_EntladeSpannung : 44|10@1+ (1,0) [0|1022] "Unit_Volt"  FCU_MLBevo_FCEV,Gateway,Gateway_PAG,Ladegeraet_Konzern,LE2_3_MLBevo_LB
 SG_ BMS_MinPred_LadeSpannung : 54|10@1+ (1,0) [0|1022] "Unit_Volt"  FCU_MLBevo_FCEV,Gateway,Gateway_PAG,LE2_3_MLBevo_LB

BO_ 1442 BMS_04: 8 BMC_MLBevo
 SG_ BMS_04_CRC : 0|8@1+ (1,0) [0|255] ""  Gateway,Gateway_PAG,Sub_Gateway
 SG_ BMS_04_BZ : 8|4@1+ (1,0) [0|15] ""  Gateway,Gateway_PAG,Sub_Gateway
 SG_ BMS_Status_ServiceDisconnect : 13|1@1+ (1,0) [0|1] ""  DCDC_800V_PAG,DCDC_HV,Gateway,Gateway_PAG,Sub_Gateway
 SG_ BMS_Status_Spgfreiheit : 14|2@1+ (1,0) [0|3] ""  Gateway,Gateway_PAG,Sub_Gateway
 SG_ BMS_OBD_Lampe_Anf : 16|1@1+ (1,0) [0|1] ""  Gateway,Gateway_PAG,Sub_Gateway
 SG_ BMS_IstModus : 17|3@1+ (1,0) [0|7] ""  AWC,Gateway,Gateway_PAG,Ladegeraet_Konzern,LE1,LE2,LE2_3_MLBevo_LB,Sub_Gateway,TME
 SG_ BMS_Fehlerstatus : 20|3@1+ (1,0) [0|7] ""  AWC,DCDC_800V_PAG,DCDC_HV,Gateway,Gateway_PAG,Ladegeraet_Konzern,Sub_Gateway
 SG_ BMS_Kapazitaet_02 : 23|11@1+ (0.2,0) [0|409.2] "Unit_AmperHour"  Gateway,Gateway_PAG,Ladegeraet_Konzern,Sub_Gateway
 SG_ BMS_Soll_SOC_HiRes : 53|11@1+ (0.05,0) [0|100] "Unit_PerCent"  Gateway,Gateway_PAG,Sub_Gateway

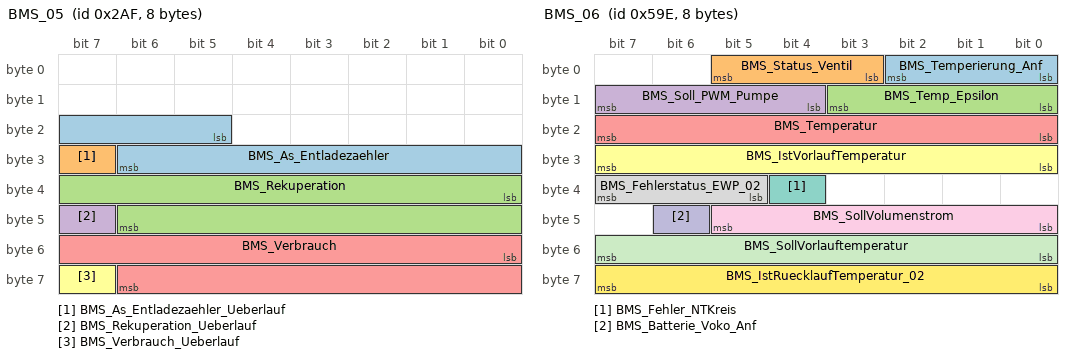
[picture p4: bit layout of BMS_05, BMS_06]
BO_ 687 BMS_05: 8 BMC_MLBevo
 SG_ BMS_As_Entladezaehler : 21|10@1+ (1,0) [0|1023] "Unit_AmperSecon"  Gateway,Gateway_PAG
 SG_ BMS_As_Entladezaehler_Ueberlauf : 31|1@1+ (1,0) [0|1] ""  Gateway,Gateway_PAG
 SG_ BMS_Rekuperation : 32|15@1+ (10,0) [0|327670] "Unit_WattSecond"  Gateway,Gateway_PAG
 SG_ BMS_Rekuperation_Ueberlauf : 47|1@1+ (1,0) [0|1] ""  Gateway,Gateway_PAG
 SG_ BMS_Verbrauch : 48|15@1+ (10,0) [0|327670] "Unit_WattSecond"  Gateway,Gateway_PAG
 SG_ BMS_Verbrauch_Ueberlauf : 63|1@1+ (1,0) [0|1] ""  Gateway,Gateway_PAG

BO_ 1438 BMS_06: 8 BMC_MLBevo
 SG_ BMS_Temperierung_Anf : 0|3@1+ (1,0) [0|7] ""  Gateway,Gateway_PAG,TME
 SG_ BMS_Status_Ventil : 3|3@1+ (1,0) [0|7] ""  Gateway,Gateway_PAG
 SG_ BMS_Temp_Epsilon : 8|4@1+ (1,-15) [-15|0] "Unit_DegreCelsi"  Gateway,Gateway_PAG,TME
 SG_ BMS_Soll_PWM_Pumpe : 12|4@1+ (10,0) [0|100] "Unit_PerCent"  Gateway,Gateway_PAG,TME
 SG_ BMS_Temperatur : 16|8@1+ (0.5,-40) [-40|86.5] "Unit_DegreCelsi"  Gateway,Gateway_PAG,Ladegeraet_Konzern,TME
 SG_ BMS_IstVorlaufTemperatur : 24|8@1+ (0.5,-40) [-40|86.5] "Unit_DegreCelsi"  Gateway,Gateway_PAG,TME
 SG_ BMS_Fehler_NTKreis : 36|1@1+ (1,0) [0|1] ""  Gateway,Gateway_PAG
 SG_ BMS_Fehlerstatus_EWP_02 : 37|3@1+ (1,0) [0|7] ""  Gateway,Gateway_PAG,TME
 SG_ BMS_SollVolumenstrom : 40|6@1+ (1,0) [0|61] "Unit_LiterPerMinut"  Gateway,Gateway_PAG,TME
 SG_ BMS_Batterie_Voko_Anf : 46|1@1+ (1,0) [0|1] ""  Gateway,Gateway_PAG,Ladegeraet_Konzern,TME
 SG_ BMS_SollVorlauftemperatur : 48|8@1+ (0.5,-40) [-40|86.5] "Unit_DegreCelsi"  Gateway,Gateway_PAG,TME
 SG_ BMS_IstRuecklaufTemperatur_02 : 56|8@1+ (0.5,-40) [-40|86.5] "Unit_DegreCelsi"  Gateway,Gateway_PAG,TME

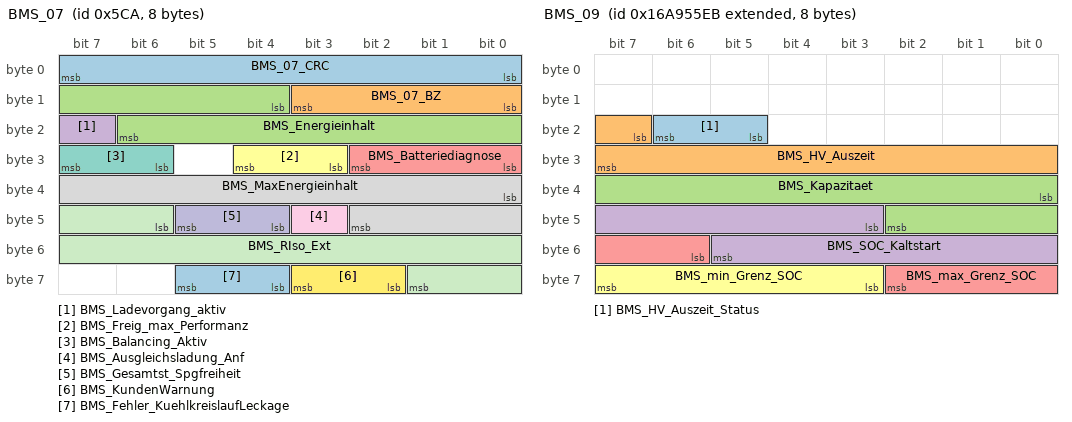
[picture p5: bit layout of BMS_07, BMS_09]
BO_ 1482 BMS_07: 8 BMC_MLBevo
 SG_ BMS_07_CRC : 0|8@1+ (1,0) [0|255] ""  Gateway,Gateway_PAG,Sub_Gateway
 SG_ BMS_07_BZ : 8|4@1+ (1,0) [0|15] ""  Gateway,Gateway_PAG,Sub_Gateway
 SG_ BMS_Energieinhalt : 12|11@1+ (50,0) [0|102250] "Unit_WattHour"  Gateway,Gateway_PAG,Ladegeraet_Konzern,Sub_Gateway,TME
 SG_ BMS_Ladevorgang_aktiv : 23|1@1+ (1,0) [0|1] ""  Gateway,Gateway_PAG,Sub_Gateway
 SG_ BMS_Batteriediagnose : 24|3@1+ (1,0) [0|7] ""  Gateway,Gateway_PAG,Sub_Gateway
 SG_ BMS_Freig_max_Performanz : 27|2@1+ (1,0) [0|3] ""  Gateway,Gateway_PAG,Sub_Gateway
 SG_ BMS_Balancing_Aktiv : 30|2@1+ (1,0) [0|3] ""  Gateway,Gateway_PAG,Sub_Gateway
 SG_ BMS_MaxEnergieinhalt : 32|11@1+ (50,0) [0|102250] "Unit_WattHour"  Gateway,Gateway_PAG,Ladegeraet_Konzern,Sub_Gateway,TME
 SG_ BMS_Ausgleichsladung_Anf : 43|1@1+ (1,0) [0|1] ""  Gateway,Gateway_PAG,Sub_Gateway
 SG_ BMS_Gesamtst_Spgfreiheit : 44|2@1+ (1,0) [0|3] ""  Gateway,Gateway_PAG,Sub_Gateway
 SG_ BMS_RIso_Ext : 46|12@1+ (5,0) [0|20465] "Unit_KiloOhm"  Gateway,Gateway_PAG,Sub_Gateway
 SG_ BMS_KundenWarnung : 58|2@1+ (1,0) [0|3] ""  Gateway,Gateway_PAG,Sub_Gateway
 SG_ BMS_Fehler_KuehlkreislaufLeckage : 60|2@1+ (1,0) [0|3] ""  Gateway,Gateway_PAG,Sub_Gateway,TME

BO_ 2527679979 BMS_09: 8 BMC_MLBevo
 SG_ BMS_HV_Auszeit_Status : 21|2@1+ (1,0) [0|3] ""  DCDC_800V_PAG,DCDC_HV,Gateway,Gateway_PAG,Ladegeraet_2,Ladegeraet_Konzern,LE2_3_MLBevo_LB,TME
 SG_ BMS_HV_Auszeit : 23|9@1+ (4,0) [0|2036] "Unit_Minut"  DCDC_800V_PAG,DCDC_HV,Gateway,Gateway_PAG,Ladegeraet_2,Ladegeraet_Konzern,LE2_3_MLBevo_LB,TME
 SG_ BMS_Kapazitaet : 32|11@1+ (0.1,0) [0|204.6] "Unit_AmperHour"  Gateway,Gateway_PAG,Ladegeraet_Konzern
 SG_ BMS_SOC_Kaltstart : 43|11@1+ (0.05,0) [0|100] "Unit_PerCent"  Gateway,Gateway_PAG
 SG_ BMS_max_Grenz_SOC : 54|5@1+ (1,70) [70|100] "Unit_PerCent"  Gateway,Gateway_PAG,Ladegeraet_Konzern
 SG_ BMS_min_Grenz_SOC : 59|5@1+ (1,0) [0|30] "Unit_PerCent"  Gateway,Gateway_PAG,Ladegeraet_Konzern

BO_TX_BU_ 64 : Gateway,Gateway_PAG;
BO_TX_BU_ 2589283757 : Gateway,Gateway_PAG;
BO_TX_BU_ 2536720384 : Gateway,Gateway_PAG;
BO_TX_BU_ 2536720385 : Gateway,Gateway_PAG;
BO_TX_BU_ 2536711424 : Gateway,Gateway_PAG;
BO_TX_BU_ 2536711425 : Gateway,Gateway_PAG;
BO_TX_BU_ 2536711426 : Gateway,Gateway_PAG;
BO_TX_BU_ 2536711427 : Gateway,Gateway_PAG;
BO_TX_BU_ 2536711429 : Gateway,Gateway_PAG;
BO_TX_BU_ 2536767280 : AWC,Gateway,Gateway_PAG,Ladegeraet_Konzern;
BO_TX_BU_ 2536706320 : Gateway,Gateway_PAG;
BO_TX_BU_ 1615 : Gateway,Gateway_PAG;
BO_TX_BU_ 1626 : Gateway,Gateway_PAG;

CM_ "MLBevo_HCAN_V8.18.01F Generated by BusNet_NG_Produktiv 9.13.1";
CM_ BU_ AWC "Automatic Wireless Charging";
CM_ BU_ BMC_MLBevo "Hybrid Batteriemanagement (Battery Energy Control Module) MLBevo Batterie Managment System";
CM_ BU_ BMS_NV "Speicher fuer Mild-Hybrid";
CM_ BU_ DCDC_800V_PAG "DCDC 800V im BEV PAG";
CM_ BU_ DCDC_HV "Standalone DCDC im BEV";
CM_ BU_ DCDC_HV_02 "HV-Booster
 DC/DC Wandler - Zielspannung HV (400V auf 800V)";
CM_ BU_ DCDC_IHEV "KD: Spannungswandler - DC/DC Converter Control Module
Standalone DCDC-Wandler im MLBevo iHEV ";
CM_ BU_ FCU_MLBevo_FCEV "Brennstoffzellenantrieb -Fuel Cell Control Module
DFL-Kürzel: FCU";
CM_ BU_ Gateway "MLBevo Diagnoseinterface für Datenbus

connected Gateway Version 2.0, Zulieferer Conti Markdorf
- e & e4

connected Gateway Version 3.1, Zulieferer ESR/Lear
- e, e2, e5, e6";
CM_ BU_ Gateway_PAG "Gateway-Variante für PAG - Absprungbasis Gateway 3.x";
CM_ BU_ Ladegeraet_2 "OBC2 - OnBoardCharger2";
CM_ BU_ Ladegeraet_Konzern "OnBoardCharger (Ladegeraet) MLBEvo
Ladegeraet_Konzern";
CM_ BU_ LE1 "Leistungselektronik1 BEV";
CM_ BU_ LE2 "Leistungselektronik2 BEV";
CM_ BU_ LE_MLBevo "Elektroantrieb (Drive Motor Control Module): Leistungselektronik Hybrid im PHEV
***EA**SNI:124**EA*** Dieser EA-Tag darf nicht verändert werden!
";
CM_ BU_ LE_MLBevo_LB "Elektroantrieb (Drive Motor Control Module): Leistungselektronik Hybrid im PHEV
***EA**SNI:124**EA*** Dieser EA-Tag darf nicht verändert werden!";
CM_ BU_ Sub_Gateway "C7 PHEV China
MLBevo PHEV China";
CM_ BU_ TME "Thermomanagment Elektrofahrzeuge
zur Koordination Klima & Batterie MLBevo";
CM_ BO_ 3221225472 "This is a message for not used signals, created by Vector CANdb++ DBC OLE DB Provider.";
CM_ SG_ 3221225472 DGN_Verlernzaehler "wrap around 254 --> 0";
CM_ SG_ 3221225472 KBI_Kilometerstand "Fehler wird ausgegeben, falls Kilometerstand nicht restaurierbar
";
CM_ SG_ 3221225472 UH_Monat "0x0D, 0xF =  Werte ungültig
0x0E = Relatives Datum (nur VW)";
CM_ SG_ 3221225472 UH_Tag "0x0: reserviert bei VW";
CM_ SG_ 3221225472 UH_Stunde "0x18 - 0x1F = Werte ungültig";
CM_ SG_ 3221225472 UH_Minute "0x3C- 0x3f = Werte ungültig";
CM_ SG_ 3221225472 UH_Sekunde "0x3C- 0x3f = Werte ungültig";
CM_ SG_ 3221225472 Uhrzeit_01_alt "
";
CM_ SG_ 3221225472 EMG_CALID_CVN_MUX "Alle CALID-Indizes bilden zusammen die CALID";
CM_ SG_ 3221225472 EMG_CVN_VLD "Valid-Bit der Calibration-Verification-Number (CVN bzw. Checksumme)";
CM_ SG_ 3221225472 EMG_CALID_Index_01 "Software-Calibration-Identification (CALID) im ASCII-Zeichenformat; 
für Ausgabe an das Generic Scan-Tool für OBD in NAR

0x30 entspricht ASCII '0'";
CM_ SG_ 3221225472 EMG_CALID_Index_05 "Software-Calibration-Identification (CALID) im ASCII-Zeichenformat; 
für Ausgabe an das Generic Scan-Tool für OBD in NAR

0x30 entspricht ASCII '0'";
CM_ SG_ 3221225472 EMG_CALID_Index_09 "Software-Calibration-Identification (CALID) im ASCII-Zeichenformat; 
für Ausgabe an das Generic Scan-Tool für OBD in NAR

0x30 entspricht ASCII '0'";
CM_ SG_ 3221225472 EMG_CALID_Index_13 "Software-Calibration-Identification (CALID) im ASCII-Zeichenformat; 
für Ausgabe an das Generic Scan-Tool für OBD in NAR

0x30 entspricht ASCII '0'";
CM_ SG_ 3221225472 EMG_CALID_Index_02 "Software-Calibration-Identification (CALID) im ASCII-Zeichenformat; 
für Ausgabe an das Generic Scan-Tool für OBD in NAR

0x30 entspricht ASCII '0'";
CM_ SG_ 3221225472 EMG_CALID_Index_06 "Software-Calibration-Identification (CALID) im ASCII-Zeichenformat; 
für Ausgabe an das Generic Scan-Tool für OBD in NAR

0x30 entspricht ASCII '0'";
CM_ SG_ 3221225472 EMG_CALID_Index_10 "Software-Calibration-Identification (CALID) im ASCII-Zeichenformat; 
für Ausgabe an das Generic Scan-Tool für OBD in NAR

0x30 entspricht ASCII '0'";
CM_ SG_ 3221225472 EMG_CALID_Index_14 "Software-Calibration-Identification (CALID) im ASCII-Zeichenformat; 
für Ausgabe an das Generic Scan-Tool für OBD in NAR

0x30 entspricht ASCII '0'";
CM_ SG_ 3221225472 EMG_CALID_Index_03 "Software-Calibration-Identification (CALID) im ASCII-Zeichenformat; 
für Ausgabe an das Generic Scan-Tool für OBD in NAR

0x30 entspricht ASCII '0'";
CM_ SG_ 3221225472 EMG_CALID_Index_07 "Software-Calibration-Identification (CALID) im ASCII-Zeichenformat; 
für Ausgabe an das Generic Scan-Tool für OBD in NAR

0x30 entspricht ASCII '0'";
CM_ SG_ 3221225472 EMG_CALID_Index_11 "Software-Calibration-Identification (CALID) im ASCII-Zeichenformat; 
für Ausgabe an das Generic Scan-Tool für OBD in NAR

0x30 entspricht ASCII '0'";
CM_ SG_ 3221225472 EMG_CALID_Index_15 "Software-Calibration-Identification (CALID) im ASCII-Zeichenformat; 
für Ausgabe an das Generic Scan-Tool für OBD in NAR

0x30 entspricht ASCII '0'";
CM_ SG_ 3221225472 EMG_CALID_Index_04 "Software-Calibration-Identification (CALID) im ASCII-Zeichenformat; 
für Ausgabe an das Generic Scan-Tool für OBD in NAR

0x30 entspricht ASCII '0'";
CM_ SG_ 3221225472 EMG_CALID_Index_08 "Software-Calibration-Identification (CALID) im ASCII-Zeichenformat; 
für Ausgabe an das Generic Scan-Tool für OBD in NAR

0x30 entspricht ASCII '0'";
CM_ SG_ 3221225472 EMG_CALID_Index_12 "Software-Calibration-Identification (CALID) im ASCII-Zeichenformat; 
für Ausgabe an das Generic Scan-Tool für OBD in NAR

0x30 entspricht ASCII '0'";
CM_ SG_ 3221225472 EMG_CALID_Index_16 "Software-Calibration-Identification (CALID) im ASCII-Zeichenformat; 
für Ausgabe an das Generic Scan-Tool für OBD in NAR

0x30 entspricht ASCII '0'";
CM_ SG_ 3221225472 EMG_CVN_Byte_1 "Calibration Verification Number (CVN bzw. Checksumme) des SW- und Datenstandes; 
für Ausgabe an das Generic Scan-Tool für OBD in NAR";
CM_ SG_ 3221225472 EMG_CVN_Byte_2 "Calibration Verification Number (CVN bzw. Checksumme) des SW- und Datenstandes; 
für Ausgabe an das Generic Scan-Tool für OBD in NAR";
CM_ SG_ 3221225472 EMG_CVN_Byte_3 "Calibration Verification Number (CVN bzw. Checksumme) des SW- und Datenstandes; 
für Ausgabe an das Generic Scan-Tool für OBD in NAR";
CM_ SG_ 3221225472 EMG_CVN_Byte_4 "Calibration Verification Number (CVN bzw. Checksumme) des SW- und Datenstandes; 
für Ausgabe an das Generic Scan-Tool für OBD in NAR";
CM_ SG_ 3221225472 EMG_Komponentenfehler_01 "Übertragung OBD relevanter Fehlerpfade vom Secondary zum Primary Steuergerät. 
Zuordnung der generischen Komponentenfehler muss zwischen Sender und Empfänger abgestimmt werden.";
CM_ SG_ 3221225472 EMG_Komponentenfehler_02 "Übertragung OBD relevanter Fehlerpfade vom Secondary zum Primary Steuergerät. 
Zuordnung der generischen Komponentenfehler muss zwischen Sender und Empfänger abgestimmt werden.";
CM_ SG_ 3221225472 EMG_Komponentenfehler_03 "Übertragung OBD relevanter Fehlerpfade vom Secondary zum Primary Steuergerät. 
Zuordnung der generischen Komponentenfehler muss zwischen Sender und Empfänger abgestimmt werden.";
CM_ SG_ 3221225472 EMG_Komponentenfehler_04 "Übertragung OBD relevanter Fehlerpfade vom Secondary zum Primary Steuergerät. 
Zuordnung der generischen Komponentenfehler muss zwischen Sender und Empfänger abgestimmt werden.";
CM_ SG_ 3221225472 EMG_Komponentenfehler_05 "Übertragung OBD relevanter Fehlerpfade vom Secondary zum Primary Steuergerät. 
Zuordnung der generischen Komponentenfehler muss zwischen Sender und Empfänger abgestimmt werden.";
CM_ SG_ 3221225472 EMG_Komponentenfehler_06 "Übertragung OBD relevanter Fehlerpfade vom Secondary zum Primary Steuergerät. 
Zuordnung der generischen Komponentenfehler muss zwischen Sender und Empfänger abgestimmt werden.";
CM_ SG_ 3221225472 EMG_Komponentenfehler_07 "Übertragung OBD relevanter Fehlerpfade vom Secondary zum Primary Steuergerät. 
Zuordnung der generischen Komponentenfehler muss zwischen Sender und Empfänger abgestimmt werden.";
CM_ SG_ 3221225472 EMG_Komponentenfehler_08 "Übertragung OBD relevanter Fehlerpfade vom Secondary zum Primary Steuergerät. 
Zuordnung der generischen Komponentenfehler muss zwischen Sender und Empfänger abgestimmt werden.";
CM_ SG_ 3221225472 EMG_Komponentenfehler_09 "Übertragung OBD relevanter Fehlerpfade vom Secondary zum Primary Steuergerät. 
Zuordnung der generischen Komponentenfehler muss zwischen Sender und Empfänger abgestimmt werden.";
CM_ SG_ 3221225472 EMG_Komponentenfehler_VLD "Valid-Bit der OBD-Komponentenfehler. Das Bit wird beim Fehlerspeicher löschen zurückgenommen und erst wieder gesetzt, wenn der Fehlerspeicher vollständig gelöscht wurde. Der Primary-OBD-ECU soll damit mitgeteilt werden, ob sie den Inhalten der Komponenten";
CM_ SG_ 3221225472 ESP_21_CRC "Für MLB:
'Berechnung siehe Lastenheft 'Kommunikationsabsicherung für FlexRay und CAN''

Ab MQB und MLBevo:
'Berechnung siehe Lastenheft 'End-to-End Kommunikationsabsicherung''

Endwerte siehe Begleitdokument 'S-PDU Kennungsfolgen'";
CM_ SG_ 3221225472 BR_Eingriffsmoment "Einheitenloser Wert! Faktor in MO_Faktor_Momente_02 in Motor_Code_01 beachten!
Schnelle reduzierende (ASR) oder erhöhende (MSR) Momentanforderung an den Motor.";
CM_ SG_ 3221225472 ESP_Diagnose "MLB: Nach Diagnoseende wird ein SW-Reset ausgelöst welcher einen Kommunikatiosausfall für max. 150ms verursacht. Dies ist bei SG mit verschärfter Timeoutüberwachung (nicht nach Konzern-LH) zu beachten.

MQB: Weiterführende Informationen im Lastenheft sp";
CM_ SG_ 3221225472 ESC_v_Signal_Qualifier_High_Low "Das Qualifizerungssignal ESC_v_Signal_Qualifier_High_Low gibt eine Information über die Güte der vom Bremsregelsystem ausgegebenen Geschwindigkeitsinformation 'mittlere Geschwindigkeit', wobei Vertrauensbereiche für das ausgegebene Geschwindigkeitssignal ";
CM_ SG_ 3221225472 ESP_Vorsteuerung "zur Unterscheidung zwischen ESP-Vorsteuermaßnahmen und ESP-Regeleingriffen";
CM_ SG_ 3221225472 OBD_Schlechtweg "Für Ausblendung der Zündaussetzererkennung im Motorsteuergerät (Otto). Bit wird gesetzt, wenn Rad-Drehbeschleunigung im ESP > Grenzwert ist. Vorteil gegenüber Radgeschwindigkeiten, dass ESP alle 2 ms dynamisch die Rad-Drehbeschleunigung errechnet und dem ";
CM_ SG_ 3221225472 ESP_v_Signal "Geschwindigkeitssignal vom ABS/ASR oder ESP. Mittelwert der angetriebenen Räder.
Bei MSR oder ABS Eingriffen wird die ABS-Referenzgeschwindigkeit für >= 200ms eingespiegelt (Zeit wird mit Aktiv-Flanke der Funktionsbits getriggert)

MQB: Bei Frontantrie";
CM_ SG_ 3221225472 ASR_Tastung_passiv "ASR deaktiviert oder Schwellen geändert (projektabhängig)
Weiterführende Informationen im Lastenheft spezifiziert und in der entsprechenden Fachabteilung zu erfragen.
";
CM_ SG_ 3221225472 ESP_Tastung_passiv "ESP deaktiviert oder Schwellen geändert (projektabhängig)
Weiterführende Informationen im Lastenheft spezifiziert und in der entsprechenden Fachabteilung zu erfragen.";
CM_ SG_ 3221225472 ESP_Systemstatus "Fehler steht für Stillegung ESP mit Fehlereintrag.

MLB: Flag wird bei Unterspannung im Stand bis einmalig 6km/h (AU48x) oder 10 km/h (AU641, AU57x) überschritten nicht gesetzt (Ausblendung Startvorgang)
Im AU64x, AU57x gilt ESP D4 Funktionsanforderung";
CM_ SG_ 3221225472 ASR_Schalteingriff "Wunsch an das Getriebe während einer ASR Regelung

MLB: Es wird nur 0x0 und 0x1 genutzt

";
CM_ SG_ 3221225472 ESP_QBit_v_Signal "Geschwindigkeit wird vom ABS/ASR oder ESP aus Ersatzwerten errechnet, wenn Bit gesetzt ist. Güte des Signals ist verändert.";
CM_ SG_ 3221225472 ABS_Bremsung "Antiblockiersystem, Bit zeigt auch Druckabbau an (z.B. ESP hat zuviel Druck aufgebaut oder ungebremste Regelung auf Bahnübergang)
Weiterführende Informationen im Lastenheft spezifiziert und in der entsprechenden Fachabteilung zu erfragen.";
CM_ SG_ 3221225472 ASR_Anf "MLB: Die Momentenanforderung 'ASR_MSR_Moment_schnell' und 'ASR_Moment_langsam' sind auszuführen
MQB: Die Momentenanforderung 'BR_Eingriffsmoment' ist auszuführen";
CM_ SG_ 3221225472 MSR_Anf "MLB: Die Momentenanforderung 'ASR_MSR_Moment_schnell' ist auszuführen.
MQB: Die Momentenanforderung 'BR_Eingriffsmoment' ist auszuführen";
CM_ SG_ 3221225472 EBV_Eingriff "Elektronische Bremskraftverteilung, aktueller Eingriff (Druckhalten, Druckabbau)

Im MLB: kein ABS / ESP-Eingriff ???";
CM_ SG_ 3221225472 EDS_Eingriff "Elektronische Differentialsperre";
CM_ SG_ 3221225472 ESP_Eingriff "Eingriff des Fahrdynamikreglers";
CM_ SG_ 3221225472 ESP_ASP "MLB: Anhaenger-Stabilisierungs-Programm
MQB: Gespannstabilisierung";
CM_ SG_ 3221225472 ESC_Neutralschaltung "Aufforderung seitens ABS an das Getriebe die Momentenübertragung zu unterbrechen";
CM_ SG_ 3221225472 SI_Sammel_SG_Fehler "Anzahl der gesetzten KD-Fehler direkt angeschlossener Steuergeräte der DK3 und DK4 gemäß 80127.
Hinweis: Ein Subbusmaster stellt nur die gesammelte Information der an ihn angeschlossenen Steuergeräte der DK3 und DK4 zur Verfügung.

Für ServiceKey Auswe";
CM_ SG_ 3221225472 SI_Diagnose_Aktiv "Gibt an ob Diagnose-Botschaften empfangen werden und somit eine Diagnose aktiv ist.
MQB: Gibt an ob Diagnose-Bus Botschaften empfangen werden und somit eine Diagnose aktiv ist.";
CM_ SG_ 3221225472 SI_T_Mode "0x0: Transportmodus nicht aktiv
0x1: Transportmodus aktiv";
CM_ SG_ 3221225472 SI_NWDF "Netzwerk-Diagnose Freigebe zur zentralen Aktivierung der Netzwerkdiagnose";
CM_ SG_ 3221225472 SI_NWDF_gueltig "Gültigkeitsbit zu SI_NWDF gemäß Lastenheft: Zentrale Aktivierung Netzwerkdiagnose";
CM_ SG_ 3221225472 SI_Sammelfehler "Sammelfehlermeldung zur Anzeige im Kombi - siehe Spez. Sammelfehlermeldung
Hinweis: Einzelne Steuergeräte können zur Anpassung an den Produktionsprozess im Gateway auskodiert werden!";
CM_ SG_ 3221225472 GW_KD_Fehler "Kundendienstfehlerbit Gateway zur Anzeige eines im Gateway abgelegten Fehlerspeichereintrages.";
CM_ SG_ 3221225472 SI_T_Schutz "Transportschutz-Signal, das bei Transportmodus und Motorlauf aktiv bleibt
0x0: Transportschutz nicht aktiv
0x1: Transportschutz aktiv";
CM_ SG_ 3221225472 SI_BUS_01 "MQB/MQB_A0/PQ26: ACAN
MQB2020: ACAN(FD)
MLBevo: HCAN
MEB: ACAN(FD)";
CM_ SG_ 3221225472 SI_BUS_02 "MQB/MQB A0 Standard+, High: FCAN
MQB2020: FCAN(FD)
MLBevo: Frei
MEB: FCAN(FD)";
CM_ SG_ 3221225472 SI_BUS_03 "MQB/MQB A0/PQ26: KCAN
MQB2020: KCAN
MLBevo: KCAN
MEB: KCAN";
CM_ SG_ 3221225472 SI_BUS_04 "MQB/MQB A0 Standard+, High: ICAN
MQB2020: ICAN
MLBevo: ICAN
MEB: ABCAN(FD)";
CM_ SG_ 3221225472 SI_BUS_05 "MQB/MQB A0/PQ26: DiagCAN
MQB2020: DiagCAN(FD)
MLBevo: DiagCAN
MEB: DiagCAN(FD)";
CM_ SG_ 3221225472 SI_BUS_06 "MQB/MQB A0/PQ26: ECAN
MQB2020: FASCAN(FD)
MLBevo: ECAN
MEB: FASCAN(FD)";
CM_ SG_ 3221225472 SI_BUS_07 "MQB: LIN1 (Energie)
MQB2020: LIN1 (Energie)
MLBevo: LIN1 (Energie)
MEB: LIN 1";
CM_ SG_ 3221225472 SI_BUS_08 "MQB: LIN2 (MFL)
MQB2020: LIN2 (MFL)
MLBevo: LIN2 (MFL)
MEB: LIN2";
CM_ SG_ 3221225472 SI_BUS_09 "MQB: LIN3 (unbelegt)
MQB2020: LIN3 (Uhr/FES)
MLBevo: LIN3 (Energie2)
MEB: LIN3";
CM_ SG_ 3221225472 SI_BUS_10 "MLBevo: Flexray

MQB2020: MCAN";
CM_ SG_ 3221225472 SI_BUS_11 "MLBevo: Ethernet
MEB: LIN4";
CM_ SG_ 3221225472 SI_BUS_12 "MQB: unbelegt
MLBevo: K2CAN
MEB: MFLCAN";
CM_ SG_ 3221225472 SI_BUS_13 "MQB: unbelegt
MLBevo: DCAN
MEB: CCAN";
CM_ SG_ 3221225472 SI_BUS_14 "MQB/MQB A0: unbelegt
MQB2020: HCAN
MLBevo: CCAN
MEB: EVCAN(FD)";
CM_ SG_ 3221225472 SI_BUS_15 "MQB: frei
MQB2020: frei
MLBevo: frei
MEB: AFSCAN";
CM_ SG_ 3221225472 SI_Bus_Identifikation "Das Signal identifiziert den Bus eindeutig. Das Signal ist konstant auf jedem Bus.
Der Signalwert entspricht dem Wert 'Busnummer' aus der VW80127 Gateway_component_list_databus_identification (0x2A2D) 'Bus-Identifier'.";
CM_ SG_ 3221225472 SI_CAB "CAB = Clusteraktivbits 
(Verwendung nur für Empfänger die nicht den AutoSar-SSW Stack implementiert haben)";
CM_ SG_ 64 Airbag_01_CRC "Für MLB:
'Berechnung siehe Lastenheft 'Kommunikationsabsicherung für FlexRay und CAN''

Ab MQB und MLBevo:
'Berechnung siehe Lastenheft 'End-to-End Kommunikationsabsicherung''

Endwerte siehe Begleitdokument 'S-PDU Kennungsfolgen'";
CM_ SG_ 64 AB_RGS_Anst "PreCrash-Ansteuerung reversibler Gurtstraffer (Aktivierung und Kraftniveau)

10xx = deaktiviert";
CM_ SG_ 64 AB_Front_Crash "Bit wird bei Überschreitung der Gurtstraffer-, US- und RdW-Schwelle gesetzt";
CM_ SG_ 64 AB_Heck_Crash "Wird für alle neu anlaufenden Projekte umgesetzt: AB8.4, Audi8/VW8";
CM_ SG_ 64 AB_SF_Crash "Z.Zt. nur in Verbindung mit Crash-Intensität >= 100b (Kraftstoffpumpenabschaltung) verwendet.";
CM_ SG_ 64 AB_SB_Crash "Z.Zt. nur in Verbindung mit Crash-Intensität >= 100b (Kraftstoffpumpenabschaltung) verwendet.
";
CM_ SG_ 64 AB_Rollover_Crash "Wird im B6/B7 Cabrio und New Beetle Cabrio bedient. ";
CM_ SG_ 64 AB_Crash_Int "Crash_Intensität_1 = fahrzeugabhängige Reaktionen im Crash
Crash_Intensität_2 = fahrzeugabhängige Reaktionen im Crash
Crash_Intensität_3 = fahrzeugabhängige Reaktionen im Crash

Die jeweiligen fahrzeugabhängigen Reaktionen im Crash sind in einem separ";
CM_ SG_ 64 AB_Lampe "Sicherheitswarnlampe im Kombi wird vom Airbag-SG angesteuert; Zustand der Lampe wird auf dem CAN-Bus ausgegeben (auch Blinkinformation).";
CM_ SG_ 64 AB_Deaktiviert "Airbag oder Gurtstraffer wurden per Anpassung deaktiviert: Aktualisierung erst nach Selbsttest";
CM_ SG_ 64 AB_VB_deaktiviert "Als Option vorgehalten, Beifahrerairbag wurden per Schlüsselschalter oder Insassenerkennung deaktiviert";
CM_ SG_ 64 AB_Systemfehler "Systemfehler Ggf. wird Warnlampe dauernd eingeschaltet.";
CM_ SG_ 64 AB_Diagnose "Airbag in Diagnose";
CM_ SG_ 64 AB_Stellgliedtest "Information, ob Airbag im Stellgliedtest ist, um eine Notrufauflösung beim Stellgliedtest zu verhindern";
CM_ SG_ 64 AB_Erh_Auf_VB "Der Fahrer soll bei einem Statuswechsel des Beifahrerairbags (ausgelöst durch die Beifahrerinsassenerkennung oder den Schlüsselschloßschalter) aufmerksam gemacht werden durch eine Anzeige im Kombi. Nur Audi: gültig für: AB2 (4-Türer AU352), B7, C6, D3";
CM_ SG_ 64 AB_Gurtwarn_VF "Fahrer hat Gurt nicht gesteckt, Anzeige im Kombi";
CM_ SG_ 64 AB_Gurtwarn_VB "Beifahrer hat Gurt nicht gesteckt, Anzeige im Kombi";
CM_ SG_ 64 AB_Anzeige_Fussg "Anzeige für ausgelöste Fussgängerschutz-Aktuatorik";
CM_ SG_ 64 AB_Texte_AKS "Textanzeige für pyrotechnische Auslösung der aktiven Kopfstütze (AKS)";
CM_ SG_ 64 AB_MKB_gueltig "Multi-Kollisions-Bremsung im Airbag freigeschaltet";
CM_ SG_ 64 AB_MKB_Anforderung "Anforderung Multi-Kollisions-Bremsung";
CM_ SG_ 64 AB_Versorgungsspannung "Übertragung der Plausibilitätsinformation Kl.15-Last vs. Kl.15-CAN.
Bedienung im Fall Kl.15-Last 'EIN' und Kl.15-CAN 'AUS' mit Ausgabe Warnung/Akustik im Kombi.";
CM_ SG_ 64 AB_Deaktivierung_HV "Deaktivierung des HV-Systems und der HV-Teilnehmer im Crash (u.a. Hybrid- und Elektrofahrzeuge)";
CM_ SG_ 64 AB_EDR_Trigger "Triggerbedingung zur dezentralen Aufzeichnung unfallrelevanter Daten im Event Data Recorder";
CM_ SG_ 64 AB_Belegung_VF "Belegungserkennung vorne Fahrer.";
CM_ SG_ 64 SC_Masterzeit_Offset "Erweiterung des Signals SC_Masterzeit um zwei höherwertige Bits, so dass ein Zeitbereich von ~20s (statt 5s) abgedeckt werden kann. Der aus SC_Masterzeit_Offset und SC_Masterzeit zu bildende Zeitstempel wird für die Synchronisation von Ereignissen der Fun";
CM_ SG_ 64 SC_LowSpeedCrashErkannt "Crash erkannt bei niedriger Geschwindigkeit";
CM_ SG_ 64 SC_Masterzeit "Masterzeit für alle Objektlisten";
CM_ SG_ 2589283757 AT_VALID_TIME "Valide (plausible) Zeit vom Zeitmaster der authentischen Zeit im cGW.

Der Zeitmaster der authentischen Zeit im cGW führt eine Plausibilisierung der GPS-Zeit über die Kommunikation mit dem Backend durch. Diese plausibilisierte Zeit wird in diesem Signal";
CM_ SG_ 2589283607 AWC_01_CRC "Für MLB:
'Berechnung siehe Lastenheft 'Kommunikationsabsicherung für FlexRay und CAN''

Ab MQB und MLBevo:
'Berechnung siehe Lastenheft 'End-to-End Kommunikationsabsicherung''

Endwerte siehe Begleitdokument 'S-PDU Kennungsfolgen'";
CM_ SG_ 2589283607 AWC_01_BZ "Fortlaufender Botschaftszaehler";
CM_ SG_ 2589283607 AWC_Status_Spgfreiheit "Information über Spannungsfreiheit der HV-Komponenten für Diagnose und Kundendienst.";
CM_ SG_ 2589283607 AWC_IstSpannung "Ausgangsspannung AWC Lader";
CM_ SG_ 2589283607 AWC_Fehlerstatus "aktueller Fehlerstatus des Ladegerätes
0: Komponente IO (keine HVK relevanter Fehler)
1: Eingeschränkte_Komponentenfunktion AWC Laden nicht möglich
2: reserve
3: Eingeschr_Komponentenfunktion aufgrund HV-Interlock-Fehler (nur wenn LHVIL)
4- 5: reserv";
CM_ SG_ 2589283607 AWC_IstModus "momentaner AWC -Lademodus, d.h. aktueller Zustand der Energieübertragung (inaktiv, aktiv, verzögert oder deaktiviert)";
CM_ SG_ 2589283607 AWC_IstStrom "Ausgangsstrom AWC";
CM_ SG_ 2589283607 AWC_MaxLadLeistung "Maximale Leistung AWC-Ladegerät bezogen auf die maximale Leistung AWC-Infrastruktur (Kabel, Ladestation) und Berücksichtigung des AWC-Ladegerät-Wirkungsgrades";
CM_ SG_ 2589283618 AWC_Fehler_zMover "z-Mover System defekt";
CM_ SG_ 2589283618 AWC_Panel_PositionX "Signal beschreibt den Abstand in x-Richtung (Fzg- Koordinatensystem) der Ladeplatten (optimale Ladeposition)";
CM_ SG_ 2589283618 AWC_Panel_PositionY "Signal beschreibt den Abstand in y-Richtung (Fzg- Koordinatensystem) der Ladeplatten (optimale Ladeposition)";
CM_ SG_ 2589283618 AWC_Panel_Verdrehwinkel "Signal beschreibt die Verdrehung der Bodenplatte zum Fahrzeug";
CM_ SG_ 2589283618 AWC_Positionierhilfe "Status AWC Positionierhilfe und Aktivierungssignal zur Aufschaltung der OPS-Anzeige (AWC Parkhilfe)";
CM_ SG_ 2589283618 AWC_Ladeoption_Infrastruktur "Rückmeldung an das Lademanagement welche Ladeoption an der Infrastrukturseite ausgewählt wurde";
CM_ SG_ 2589283618 AWC_Spielschutz "Spielschutz im AWC verhindert, dass z-Mover wiederholt angehoben und abgesenkt werden kann.
Signal gibt an ob Spielschutz aktiv ist.";
CM_ SG_ 2589283618 AWC_Status "momentaner Betriebszustand AWC inkl. z-Mover";
CM_ SG_ 2589283618 AWC_Fehler_FOD "FOD System defekt
(Foreign Object Detection = Metallerkennung)";
CM_ SG_ 2589283618 AWC_Fehler_Kommunikation "AWC Kommunikation zw. Infrastrukturspule und Fzg-Spule defekt";
CM_ SG_ 2589283618 AWC_Fehler_LOP "LOP System defekt
(Living Object Protection = Personenschutz)";
CM_ SG_ 2589283618 AWC_Verzoegerung_FOD "Verzögerung des Ladevorgangs aufgrund des FOD (Foreign Object Detection = Metallerkennung)";
CM_ SG_ 2589283618 AWC_Verzoegerung_LOP "Verzögerung des Ladevorgangs aufgrund des LOP (Living Object Protection = Personenschutz)";
CM_ SG_ 2589283618 AWC_Verzoegerung_Temp "Verzögerung des Ladevorgangs aufgrund der Umgebungstemperatur außerhalb Ladespec.";
CM_ SG_ 2589283618 AWC_Verzoegerung_zMover "Verzögerung des Ladevorgangs aufgrund des z-Movers";
CM_ SG_ 2589283633 AWC_Abregelung_Temperatur "Abregelung aufgrund Übertemperatur AWC";
CM_ SG_ 2589283633 AWC_PlanAntw_Zaehler "Antwort auf die Ladeplan-Anfrage für die Ladeplanung: Zähler";
CM_ SG_ 2589283633 AWC_PlanAntw_Verlustleistung "Antwort auf die Ladeplan-Anfrage für die Ladeplanung: Verlustleistung";
CM_ SG_ 2589283633 AWC_Temperatur "Aktuelle Temperatur des AWC";
CM_ SG_ 2589283685 AWC_CALID_CVN_MUX "Alle CALID-Indizes bilden zusammen die CALID";
CM_ SG_ 2589283685 AWC_CVN_VLD "Valid-Bit der Calibration-Verification-Number (CVN bzw. Checksumme)";
CM_ SG_ 2589283685 AWC_CALID_Index_01 "Software-Calibration-Identification (CALID) im ASCII-Zeichenformat; 
für Ausgabe an das Generic Scan-Tool für OBD in NAR

0x30 entspricht ASCII '0'";
CM_ SG_ 2589283685 AWC_CALID_Index_05 "Software-Calibration-Identification (CALID) im ASCII-Zeichenformat; 
für Ausgabe an das Generic Scan-Tool für OBD in NAR

0x30 entspricht ASCII '0'";
CM_ SG_ 2589283685 AWC_CALID_Index_09 "Software-Calibration-Identification (CALID) im ASCII-Zeichenformat; 
für Ausgabe an das Generic Scan-Tool für OBD in NAR

0x30 entspricht ASCII '0'";
CM_ SG_ 2589283685 AWC_CALID_Index_13 "Software-Calibration-Identification (CALID) im ASCII-Zeichenformat; 
für Ausgabe an das Generic Scan-Tool für OBD in NAR

0x30 entspricht ASCII '0'";
CM_ SG_ 2589283685 AWC_CALID_Index_02 "Software-Calibration-Identification (CALID) im ASCII-Zeichenformat; 
für Ausgabe an das Generic Scan-Tool für OBD in NAR

0x30 entspricht ASCII '0'";
CM_ SG_ 2589283685 AWC_CALID_Index_06 "Software-Calibration-Identification (CALID) im ASCII-Zeichenformat; 
für Ausgabe an das Generic Scan-Tool für OBD in NAR

0x30 entspricht ASCII '0'";
CM_ SG_ 2589283685 AWC_CALID_Index_10 "Software-Calibration-Identification (CALID) im ASCII-Zeichenformat; 
für Ausgabe an das Generic Scan-Tool für OBD in NAR

0x30 entspricht ASCII '0'";
CM_ SG_ 2589283685 AWC_CALID_Index_14 "Software-Calibration-Identification (CALID) im ASCII-Zeichenformat; 
für Ausgabe an das Generic Scan-Tool für OBD in NAR

0x30 entspricht ASCII '0'";
CM_ SG_ 2589283685 AWC_CALID_Index_03 "Software-Calibration-Identification (CALID) im ASCII-Zeichenformat; 
für Ausgabe an das Generic Scan-Tool für OBD in NAR

0x30 entspricht ASCII '0'";
CM_ SG_ 2589283685 AWC_CALID_Index_07 "Software-Calibration-Identification (CALID) im ASCII-Zeichenformat; 
für Ausgabe an das Generic Scan-Tool für OBD in NAR

0x30 entspricht ASCII '0'";
CM_ SG_ 2589283685 AWC_CALID_Index_11 "Software-Calibration-Identification (CALID) im ASCII-Zeichenformat; 
für Ausgabe an das Generic Scan-Tool für OBD in NAR

0x30 entspricht ASCII '0'";
CM_ SG_ 2589283685 AWC_CALID_Index_15 "Software-Calibration-Identification (CALID) im ASCII-Zeichenformat; 
für Ausgabe an das Generic Scan-Tool für OBD in NAR

0x30 entspricht ASCII '0'";
CM_ SG_ 2589283685 AWC_CALID_Index_04 "Software-Calibration-Identification (CALID) im ASCII-Zeichenformat; 
für Ausgabe an das Generic Scan-Tool für OBD in NAR

0x30 entspricht ASCII '0'";
CM_ SG_ 2589283685 AWC_CALID_Index_08 "Software-Calibration-Identification (CALID) im ASCII-Zeichenformat; 
für Ausgabe an das Generic Scan-Tool für OBD in NAR

0x30 entspricht ASCII '0'";
CM_ SG_ 2589283685 AWC_CALID_Index_12 "Software-Calibration-Identification (CALID) im ASCII-Zeichenformat; 
für Ausgabe an das Generic Scan-Tool für OBD in NAR

0x30 entspricht ASCII '0'";
CM_ SG_ 2589283685 AWC_CALID_Index_16 "Software-Calibration-Identification (CALID) im ASCII-Zeichenformat; 
für Ausgabe an das Generic Scan-Tool für OBD in NAR

0x30 entspricht ASCII '0'";
CM_ SG_ 2589283685 AWC_CVN_Byte_1 "Calibration Verification Number (CVN bzw. Checksumme) des SW- und Datenstandes; 
für Ausgabe an das Generic Scan-Tool für OBD in NAR";
CM_ SG_ 2589283685 AWC_CVN_Byte_2 "Calibration Verification Number (CVN bzw. Checksumme) des SW- und Datenstandes; 
für Ausgabe an das Generic Scan-Tool für OBD in NAR";
CM_ SG_ 2589283685 AWC_CVN_Byte_3 "Calibration Verification Number (CVN bzw. Checksumme) des SW- und Datenstandes; 
für Ausgabe an das Generic Scan-Tool für OBD in NAR";
CM_ SG_ 2589283685 AWC_CVN_Byte_4 "Calibration Verification Number (CVN bzw. Checksumme) des SW- und Datenstandes; 
für Ausgabe an das Generic Scan-Tool für OBD in NAR";
CM_ SG_ 2589283394 AWC_Komponentenfehler_01 "Übertragung OBD relevanter Fehlerpfade vom Secondary zum Primary Steuergerät. 
Zuordnung der generischen Komponentenfehler muss zwischen Sender und Empfänger abgestimmt werden.";
CM_ SG_ 2589283394 AWC_Komponentenfehler_02 "Übertragung OBD relevanter Fehlerpfade vom Secondary zum Primary Steuergerät. 
Zuordnung der generischen Komponentenfehler muss zwischen Sender und Empfänger abgestimmt werden.";
CM_ SG_ 2589283394 AWC_Komponentenfehler_03 "Übertragung OBD relevanter Fehlerpfade vom Secondary zum Primary Steuergerät. 
Zuordnung der generischen Komponentenfehler muss zwischen Sender und Empfänger abgestimmt werden.";
CM_ SG_ 2589283394 AWC_Komponentenfehler_04 "Übertragung OBD relevanter Fehlerpfade vom Secondary zum Primary Steuergerät. 
Zuordnung der generischen Komponentenfehler muss zwischen Sender und Empfänger abgestimmt werden.";
CM_ SG_ 2589283394 AWC_Komponentenfehler_05 "Übertragung OBD relevanter Fehlerpfade vom Secondary zum Primary Steuergerät. 
Zuordnung der generischen Komponentenfehler muss zwischen Sender und Empfänger abgestimmt werden.";
CM_ SG_ 2589283394 AWC_Komponentenfehler_06 "Übertragung OBD relevanter Fehlerpfade vom Secondary zum Primary Steuergerät. 
Zuordnung der generischen Komponentenfehler muss zwischen Sender und Empfänger abgestimmt werden.";
CM_ SG_ 2589283394 AWC_Komponentenfehler_07 "Übertragung OBD relevanter Fehlerpfade vom Secondary zum Primary Steuergerät. 
Zuordnung der generischen Komponentenfehler muss zwischen Sender und Empfänger abgestimmt werden.";
CM_ SG_ 2589283394 AWC_Komponentenfehler_08 "Übertragung OBD relevanter Fehlerpfade vom Secondary zum Primary Steuergerät. 
Zuordnung der generischen Komponentenfehler muss zwischen Sender und Empfänger abgestimmt werden.";
CM_ SG_ 2589283394 AWC_Komponentenfehler_09 "Übertragung OBD relevanter Fehlerpfade vom Secondary zum Primary Steuergerät. 
Zuordnung der generischen Komponentenfehler muss zwischen Sender und Empfänger abgestimmt werden.";
CM_ SG_ 2589283394 AWC_Komponentenfehler_10 "Übertragung OBD relevanter Fehlerpfade vom Secondary zum Primary Steuergerät. 
Zuordnung der generischen Komponentenfehler muss zwischen Sender und Empfänger abgestimmt werden.";
CM_ SG_ 2589283394 AWC_Komponentenfehler_11 "Übertragung OBD relevanter Fehlerpfade vom Secondary zum Primary Steuergerät. 
Zuordnung der generischen Komponentenfehler muss zwischen Sender und Empfänger abgestimmt werden.";
CM_ SG_ 2589283394 AWC_Komponentenfehler_12 "Übertragung OBD relevanter Fehlerpfade vom Secondary zum Primary Steuergerät. 
Zuordnung der generischen Komponentenfehler muss zwischen Sender und Empfänger abgestimmt werden.";
CM_ SG_ 2589283394 AWC_Komponentenfehler_13 "Übertragung OBD relevanter Fehlerpfade vom Secondary zum Primary Steuergerät. 
Zuordnung der generischen Komponentenfehler muss zwischen Sender und Empfänger abgestimmt werden.";
CM_ SG_ 2589283394 AWC_Komponentenfehler_14 "Übertragung OBD relevanter Fehlerpfade vom Secondary zum Primary Steuergerät. 
Zuordnung der generischen Komponentenfehler muss zwischen Sender und Empfänger abgestimmt werden.";
CM_ SG_ 2589283394 AWC_Komponentenfehler_15 "Übertragung OBD relevanter Fehlerpfade vom Secondary zum Primary Steuergerät. 
Zuordnung der generischen Komponentenfehler muss zwischen Sender und Empfänger abgestimmt werden.";
CM_ SG_ 2589283394 AWC_Komponentenfehler_16 "Übertragung OBD relevanter Fehlerpfade vom Secondary zum Primary Steuergerät. 
Zuordnung der generischen Komponentenfehler muss zwischen Sender und Empfänger abgestimmt werden.";
CM_ SG_ 2589283394 AWC_Komponentenfehler_17 "Übertragung OBD relevanter Fehlerpfade vom Secondary zum Primary Steuergerät. 
Zuordnung der generischen Komponentenfehler muss zwischen Sender und Empfänger abgestimmt werden.";
CM_ SG_ 2589283394 AWC_Komponentenfehler_18 "Übertragung OBD relevanter Fehlerpfade vom Secondary zum Primary Steuergerät. 
Zuordnung der generischen Komponentenfehler muss zwischen Sender und Empfänger abgestimmt werden.";
CM_ SG_ 2589283394 AWC_Komponentenfehler_19 "Übertragung OBD relevanter Fehlerpfade vom Secondary zum Primary Steuergerät. 
Zuordnung der generischen Komponentenfehler muss zwischen Sender und Empfänger abgestimmt werden.";
CM_ SG_ 2589283394 AWC_Komponentenfehler_20 "Übertragung OBD relevanter Fehlerpfade vom Secondary zum Primary Steuergerät. 
Zuordnung der generischen Komponentenfehler muss zwischen Sender und Empfänger abgestimmt werden.";
CM_ SG_ 2589283394 AWC_Komponentenfehler_21 "Übertragung OBD relevanter Fehlerpfade vom Secondary zum Primary Steuergerät. 
Zuordnung der generischen Komponentenfehler muss zwischen Sender und Empfänger abgestimmt werden.";
CM_ SG_ 2589283394 AWC_Komponentenfehler_22 "Übertragung OBD relevanter Fehlerpfade vom Secondary zum Primary Steuergerät. 
Zuordnung der generischen Komponentenfehler muss zwischen Sender und Empfänger abgestimmt werden.";
CM_ SG_ 2589283394 AWC_Komponentenfehler_23 "Übertragung OBD relevanter Fehlerpfade vom Secondary zum Primary Steuergerät. 
Zuordnung der generischen Komponentenfehler muss zwischen Sender und Empfänger abgestimmt werden.";
CM_ SG_ 2589283394 AWC_Komponentenfehler_24 "Übertragung OBD relevanter Fehlerpfade vom Secondary zum Primary Steuergerät. 
Zuordnung der generischen Komponentenfehler muss zwischen Sender und Empfänger abgestimmt werden.";
CM_ SG_ 2589283394 AWC_Komponentenfehler_25 "Übertragung OBD relevanter Fehlerpfade vom Secondary zum Primary Steuergerät. 
Zuordnung der generischen Komponentenfehler muss zwischen Sender und Empfänger abgestimmt werden.";
CM_ SG_ 2589283394 AWC_Komponentenfehler_26 "Übertragung OBD relevanter Fehlerpfade vom Secondary zum Primary Steuergerät. 
Zuordnung der generischen Komponentenfehler muss zwischen Sender und Empfänger abgestimmt werden.";
CM_ SG_ 2589283394 AWC_Komponentenfehler_27 "Übertragung OBD relevanter Fehlerpfade vom Secondary zum Primary Steuergerät. 
Zuordnung der generischen Komponentenfehler muss zwischen Sender und Empfänger abgestimmt werden.";
CM_ SG_ 2589283394 AWC_Komponentenfehler_28 "Übertragung OBD relevanter Fehlerpfade vom Secondary zum Primary Steuergerät. 
Zuordnung der generischen Komponentenfehler muss zwischen Sender und Empfänger abgestimmt werden.";
CM_ SG_ 2589283394 AWC_Komponentenfehler_29 "Übertragung OBD relevanter Fehlerpfade vom Secondary zum Primary Steuergerät. 
Zuordnung der generischen Komponentenfehler muss zwischen Sender und Empfänger abgestimmt werden.";
CM_ SG_ 2589283394 AWC_Komponentenfehler_30 "Übertragung OBD relevanter Fehlerpfade vom Secondary zum Primary Steuergerät. 
Zuordnung der generischen Komponentenfehler muss zwischen Sender und Empfänger abgestimmt werden.";
CM_ SG_ 2589283394 AWC_Komponentenfehler_31 "Übertragung OBD relevanter Fehlerpfade vom Secondary zum Primary Steuergerät. 
Zuordnung der generischen Komponentenfehler muss zwischen Sender und Empfänger abgestimmt werden.";
CM_ SG_ 2589283394 AWC_Komponentenfehler_VLD "Valid-Bit der OBD-Komponentenfehler. Das Bit wird beim Fehlerspeicher löschen zurückgenommen und erst wieder gesetzt, wenn der Fehlerspeicher vollständig gelöscht wurde. Der Primary-OBD-ECU soll damit mitgeteilt werden, ob sie den Inhalten der Komponenten";
CM_ SG_ 2536720384 BAP_AWC_ASG_01_Header "AWC Anzeigesteuergerät (ASG BAP Strecke)";
CM_ SG_ 2536720385 BAP_AWC_ASG_02_Header "AWC Anzeigesteuergerät (ASG BAP Strecke)";
CM_ SG_ 2536720400 BAP_AWC_FSG_01_Header "AWC Funktionssteuergeraet";
CM_ SG_ 2536711428 BAP_BatteryControl_ASG_05_Header "BatteryControl Anzeigesteuergeraet";
CM_ SG_ 2536711429 BAP_BatteryControl_ASG_06_Header "BatteryControl Anzeigesteuergerät Head-Up Display";
CM_ SG_ 2536706310 BAP_Uhrzeit_ASG_07_Header "Uhrzeit Anzeigesteuergeraet AWC";
CM_ SG_ 1615 CHA_Kombi_Texte "Anzeige des aktuellen Charisma-Fahrprofiles im Kombi.
Die Texte werden HUT-Spezifisch in einem Schnittstellen-LAH definiert.";
CM_ SG_ 1615 BCM1_HUD_Eyeboxposition "Position des Eyebox Drehgebers";
CM_ SG_ 1615 BCM1_HUD_Eyeboxposition_Status "Status Eyebox Drehgeber";
CM_ SG_ 1615 BCM1_HUD_Taster "Status HUD Taster";
CM_ SG_ 1615 BCM1_Stellgroesse_Kl_58s "Rohwert Dimmpoti";
CM_ SG_ 1615 BCM1_LDS_Stellung "Das Signal wird vom AFS / LWR Steuergerät empfangen und dient der Verifizierung der Lichtdrehschalterstellung. Intelligente Lichtfunktionen wie dyn. KL und gleitende Leuchtweite (GLW) nur bei LDS = 'AUTO'.";
CM_ SG_ 1615 BCM1_Lichtwarn_Texte "Anforderung von Lichtwarnungen vom BCM1 zum Kombi
MLB: nur Werte 0..2";
CM_ SG_ 1615 CHA_Drehschalter_Modus "Charisma Drehschalter Modus";
CM_ SG_ 1615 KRH_Stufe_LED_li "Statusmeldung Kopfraumheizung links";
CM_ SG_ 1615 KRH_Stufe_LED_re "Statusmeldung Kopfraumheizung rechts";
CM_ SG_ 1615 BCM1_Spannungs_Anf "Forderung des BCM1-SG's zur Spannungsanhebung.";
CM_ SG_ 1615 LV_Laserlicht_Texte "Anforderung Kombi-Texte bezüglich Laser-Fernlicht";
CM_ SG_ 1615 BCM1_Hinweis_Lichtnachlauf "Signal dient der Anzeige eines aktiven Lichtnachlaufes beim automatischen Abschalten der Klemme S und Klemme 15. Der Lichtnachlauf wird gestartet, wenn die Klemme 15 bei aktivem Fahrlicht deaktiviert wird.";
CM_ SG_ 1615 LV_LED_Scheinwerfer_li_def "Fehlerstatus LED-Scheinwerfer links
";
CM_ SG_ 1615 LV_LED_Scheinwerfer_re_def "Fehlerstatus LED-Scheinwerfer rechts";
CM_ SG_ 1615 BCM1_Status_Ladeanzeige "Leuchtenstatus zur Anzeige von ChargeCheck
Sendeart = Cyclic, Zykluszeit = 100ms anlog des Signals im MQB (Licht_hinten_01/BCM_Status_Ladeanzeige) auf dem ACAN";
CM_ SG_ 1626 BCM_Bremsbelag_Sensor "Sensorsignal der Stromschleife  für Bremsbelagverschleiß aktuell, entstört, unbewertet";
CM_ SG_ 1626 BCM_Bremsfluessigkeit_Sensor "Kontaktsignal des Sensorschalters für die Bremsflüssigkeitsreserve aktuell, entstört, unbewertet";
CM_ SG_ 1626 BCM1_Licht_Warn "Lichtwarnung";
CM_ SG_ 1626 BCM_Waschwasser_Sensor "Signal der Sensorelektroden für die Waschwasserreserve aktuell, entstört, bewertet (OK/Mangel)";
CM_ SG_ 1626 BCM_Kuehlmittel_Sensor "Signal der Sensorelektroden für die Kühlmittelreserve aktuell, entstört, bewertet (OK/Mangel)";
CM_ SG_ 1626 BCM1_Kl_15_HW_erkannt "Erkennung Klemme 15 (Hardware) vom BCM1
";
CM_ SG_ 1626 BCM1_Kl_15_Sig_HW_erkannt "Erkennung Klemme 15 Signal (Hardware) vom BCM1";
CM_ SG_ 1626 BCM_Kuehlmittel_Sensor_02 "Signal der zweiten Sensorelektroden für die Kühlmittelreserve aktuell, entstört, bewertet (OK/Mangel)";
CM_ SG_ 1626 BCM1_Hinweis_Lichtnachlauf "Signal dient der Anzeige eines aktiven Lichtnachlaufes beim automatischen Abschalten der Klemme S und Klemme 15. Der Lichtnachlauf wird gestartet, wenn die Klemme 15 bei aktivem Fahrlicht deaktiviert wird.";
CM_ SG_ 1626 BCM_Offroad_Taste "Betätigung der Offroad-Taste";
CM_ SG_ 1626 BCM_Hybrid_StSt_Taste_Fehler "Fehlerflag, wenn Tasterdiagnose im BCM für den StSt-Taster anschlägt.";
CM_ SG_ 1626 BCM_Hybrid_StartStopp_Taste "Betaetigung Taster 'Hybrid' oder alternativ Taster 'Start/Stopp Deaktivierung', je nach Verbau";
CM_ SG_ 1626 BCM1_Warnblink_Taster "Warnblinktaster";
CM_ SG_ 1626 BCM1_Valet_Parking_Taster "Valet Parking Taster ";
CM_ SG_ 1626 BCM1_LDS_Stellung "Das Signal wird vom AFS / LWR Steuergerät empfangen und dient der Verifizierung der Lichtdrehschalterstellung. Intelligente Lichtfunktionen wie dyn. KL und gleitende Leuchtweite (GLW) nur bei LDS = 'AUTO'.";
CM_ SG_ 1626 BCM1_Rueckfahrlicht_Schalter "Rückfahrlichtschalter
ab MQB/ MLBevo: Die Ganginformation wird unentprellt übertragen, im AT-Getriebe wird evtl. kurzzeitig der R-Gang angezeigt. Eine Entprellung muß im Empfänger erfolgen (typisch 400ms).";
CM_ SG_ 1626 BCM1_MH_Schalter "Motorhaubenkontakt";
CM_ SG_ 1626 BCM1_MH_WIV_Schalter "Bewerteter Motorhaubenkontakt fuer WIV";
CM_ SG_ 1626 BCM_Eco_Charisma_Taste "Betätigung Taster ECO alias BlueKey oder Charisma";
CM_ SG_ 1626 BCM1_NV_Taster "BCM1_NV_Taster gibt an, ob der NightVision-Taster im Lichtdrehschalter-Modul aktuell betaetigt wird.";
CM_ SG_ 1626 BCM1_AFS_Lampe "Ansteuerung der AFS-Fehlermeldung im Kombi";
CM_ SG_ 1626 BCM1_Reisemodus_Texte "Ansteuerung der Reisemodus-Texte im Kombi";
CM_ SG_ 1626 BCM1_Lichtwarn_Texte "Anforderung von Lichtwarnungen vom BCM1 zum Kombi
MLB: nur Werte 0..2";
CM_ SG_ 1626 Gong_TFL_Umschaltung "Aktivierung / Deaktivierung des TFL per Affengriff wird mit einem Gong im Kombi quittiert.";
CM_ SG_ 1626 UGDO_Function_01 "UGDO_Sender = LIN-Slave BCM1
bei Kl.15 AUS wird für 4s noch der letzte Wert gesendet, danach wird der Wert 7 (= Fehler gesendet)";
CM_ SG_ 1626 APS_Tongeber_defekt "Status APS-Tongeber zur HMI-Ansteuerng der RCTA-Funktion";
CM_ SG_ 1626 BCM1_EasyEntry_Status "Status EasyEntry für Lenksäule (wird auch von IVB verwendet)";
CM_ SG_ 1626 BCM1_Lenksaeule_aktiv "Lenksaeulenverstellung aktiv";
CM_ SG_ 1626 BCM1_St_SW_Diebstahl_links "Signal zur Anzeige, dass der linke Scheinwerfer gestohlen wurde";
CM_ SG_ 1626 BCM1_St_SW_Diebstahl_rechts "Signal zur Anzeige, dass der rechte Scheinwerfer gestohlen wurde";
CM_ SG_ 1626 ISP_Dimmung_ASP_02 "Dimmwertvorgabe für Aussenspiegel
Es wird 1:1 die Spannung am Innenspiegel nach außen übertragen.";
CM_ SG_ 1626 BCM1_Schluesselsuche_Anf "Anforderung von BCM1 an BCM2:
Schlüsselpolling aktivieren

Nötig bei z.B. aktiviertem Annäherungslicht";
CM_ SG_ 1626 BCM1_Fahrlicht_Hinweis "Signal zum Kombi um den Hinweis 'Bitte Fahrlicht einschalten' anzufordern";
CM_ SG_ 1626 BCM_HDF_betaetigt "Betätigung Taster für Heckdeckelfernentriegelung in Mittelkonsole";
CM_ SG_ 401 BMS_01_CRC "Für MLB:
'Berechnung siehe Lastenheft 'Kommunikationsabsicherung für FlexRay und CAN''

Ab MQB und MLBevo:
'Berechnung siehe Lastenheft 'End-to-End Kommunikationsabsicherung''

Endwerte siehe Begleitdokument 'S-PDU Kennungsfolgen'";
CM_ SG_ 401 BMS_IstStrom_02 "Momentanwert: Batteriestrom
Stromrichtung: ein Ladestrom wird mit positiven, ein Entladestrom mit negativen Werten angegeben";
CM_ SG_ 401 BMS_IstSpannung "actual voltage of the battery / Momentanwert: Batteriespannung";
CM_ SG_ 401 BMS_Spannung_ZwKr "Momentanwert: 
Spannung an den Batterie-HV-Anschlüssen";
CM_ SG_ 401 BMS_SOC_HiRes "State of Charge / aktueller Ladezustand der Batterie (höhere Auflösung)";
CM_ SG_ 401 BMS_IstStrom_02_OffsetVZ "Vorzeichen des Offsets, bzw. der Nachkommastelle";
CM_ SG_ 401 BMS_IstStrom_02_Offset "Nachkommastelle des BMS_IstStrom_02";
CM_ SG_ 417 BMS_MaxDyn_LadeStrom_02_Offset "Nachkommastelle BMS_MaxDyn_LadeStrom_02";
CM_ SG_ 417 BMS_MaxDyn_EntladeStrom_02 "max current (discharge)
maximal zulässiger Entladestrom (zwingend einzuhaltender Grenzwert); Wert ist für eine Dauer von 1s garantiert
";
CM_ SG_ 417 BMS_MaxDyn_LadeStrom_02 "max current (charge)
maximal zulässiger Ladestrom (zwingend einzuhaltender Grenzwert); Wert ist für eine Dauer von 1s garantiert
(Im Balancing-Mode wird über diesen Wert der Ladestrom-Sollwert angegeben)";
CM_ SG_ 417 BMS_Min_EntladeSpannung "min. voltage / minimal erlaubte Batteriespannung (zwingend einzuhaltender Grenzwert)";
CM_ SG_ 417 BMS_MinDyn_EntladeSpannung "min. voltage during discharge with current MaxDyn_EntladeStrom resp. iDisChMax / rechnerischer Wert: minimales, für eine Dauer von ~1s garantiertes Spannungsniveau, das unter Belastung mit MaxDyn_EntladeStrom bzw. iDisChMax nicht unterschritten werden wür";
CM_ SG_ 417 BMS_MinDyn_LadeSpannung "min. voltage during charge with current MaxDyn_LadeStrom resp. iChMax / rechnerischer Wert: minimales, für eine Dauer von ~1s garantiertes Spannungsniveau, das unter Belastung mit MaxDyn_LadeStrom bzw. iChMax nicht unterschritten werden würde
";
CM_ SG_ 925 BMS_Leerlaufspannung "Leerlaufspannung der Gesamtbatterie, Open Circuit Voltage of the battery system";
CM_ SG_ 925 BMS_Max_LadeSpannung "max. voltage / maximal erlaubte Batteriespannung (zwingend einzuhaltender Grenzwert)";
CM_ SG_ 925 BMS_MaxPred_EntladeStrom_02 "dynamic el. limit, max. current (discharge) for the specified time (e.g. 10s): and the voltage limit (only for prediction)
rechnerischer Wert: quasistationärer, für eine Dauer von z.B. 10s garantierter maximaler Entladestrom";
CM_ SG_ 925 BMS_MaxPred_LadeStrom_02 "dynamic el. limit, max. current (charge) for the specified time (e.g. 10s), and the voltage limit (only for prediction) 
rechnerischer Wert: quasistationärer, für eine Dauer von z.B. 10s garantierter maximaler Ladestrom
EV / PlugIn:
externes Laden (BMS";
CM_ SG_ 925 BMS_MinPred_EntladeSpannung "static el. limit, min. battery voltage (~10s) during current MaxPred_EntladeStrom resp iDisChPredMax / rechnerischer Wert: minimales, für eine Dauer von 10s garantiertes Spannungsniveau, das unter Belastung mit MaxPred_EntladeStrom bzw. iDisChPredMax nich";
CM_ SG_ 925 BMS_MinPred_LadeSpannung "static el. limit, min. battery voltage (~10s) during current MaxPred_LadeStrom resp. iChPredMax / rechnerischer Wert: minimales, für eine Dauer von ~10s garantiertes Spannungsniveau, das unter Belastung mit MaxPred_LadeStrom bzw. iChPredMax nicht untersch";
CM_ SG_ 1442 BMS_04_CRC "Für MLB:
'Berechnung siehe Lastenheft 'Kommunikationsabsicherung für FlexRay und CAN''

Ab MQB und MLBevo:
'Berechnung siehe Lastenheft 'End-to-End Kommunikationsabsicherung''

Endwerte siehe Begleitdokument 'S-PDU Kennungsfolgen'";
CM_ SG_ 1442 BMS_Status_ServiceDisconnect "Status des Service Disconnect, ob dieser gesteckt oder gezogen ist.
Abhängigkeiten zu anderen Signalen: BMS_Fehler_Sicherung und BMS_Fehler_Pilot";
CM_ SG_ 1442 BMS_Status_Spgfreiheit "0=Init (ohne Funktion)
1=BMS Zwischenkreis spannungsfrei (U_Zwkr < 20V)
2=BMS Zwischenkreis nicht spannungsfrei (U_Zwkr >/= 25V, Hysterese)
3=Fehler (z.B. Fehler in der Sensorik)";
CM_ SG_ 1442 BMS_OBD_Lampe_Anf "Anforderung MIL (MalfunctionIndicationLamp) von BMS (Motorsteuergerät reicht diese Info an Kombi weiter).";
CM_ SG_ 1442 BMS_IstModus "Aktueller Betriebsmodus der Batterie
0: Standby; Schuetze geoeffnet; Kommunikation aktiv
1: Hauptschuetze geschlossen / HV-Netz aktiviert / normaler Fahrbetrieb
2: projektabhaengig belegt (z.B. Balancing, erweitertes DC-Schnelladen)
3: externes Laden ";
CM_ SG_ 1442 BMS_Fehlerstatus "aktueller Fehlerstatus der Batterie";
CM_ SG_ 1442 BMS_Kapazitaet_02 "Nutzbare Kapazität der Batterie,
oder alterungsabhängige absolute Gesamtkapazität der Batterie.

Projektabhängig kann die Kapazität auf das nutzbare SOC-Fenster (zwischen oberer und unterer SOC-Grenze) bezogen sein, wobei sich dieses SOC-Fenster alteru";
CM_ SG_ 1442 BMS_Soll_SOC_HiRes "Der Sollwert für den HV-Batterie-SOC bei einer SOC-steuernden Betriebsstrategie";
CM_ SG_ 687 BMS_As_Entladezaehler "Signal zur Berechnung des Lastprofils durch die RWB";
CM_ SG_ 687 BMS_As_Entladezaehler_Ueberlauf "Wird beim ersten Überlauf von BMS_As_Entladezahler auf 1 gesetzt. Reset über KL15-Wechsel";
CM_ SG_ 687 BMS_Rekuperation "Zähler: Anzeigesignal: Energiezufuhr in die HV-Batterie (Reku). Darf nicht durch Laden der Batterie bedatet werden";
CM_ SG_ 687 BMS_Rekuperation_Ueberlauf "Rekuperationleistungssignal BMS_Rekuperation mindest 1x übergelaufen";
CM_ SG_ 687 BMS_Verbrauch "Zähler: Energieentnahme aus der HV-Batterie";
CM_ SG_ 687 BMS_Verbrauch_Ueberlauf "Verbrauchssignal mindest 1x übergelaufen";
CM_ SG_ 1438 BMS_Temperierung_Anf "Temperierungsbedarf der HV-Batterie";
CM_ SG_ 1438 BMS_Status_Ventil "Status des 3-2-Wege-Ventils (betätigt/unbetätigt/Fehler)";
CM_ SG_ 1438 BMS_Temp_Epsilon "Das Signal beschreibt die Differenz zwischen Batterie Soll-Temperatur und Batterie Ist-Temperatur.";
CM_ SG_ 1438 BMS_Soll_PWM_Pumpe "Ansteuerungs-Sollwert der Batterie-Kühlmittelpumpe. 
Speziell im MQB PHEV: Istwert der Pumpenansteuerung (Batterie steuert Pumpe selbständig an).";
CM_ SG_ 1438 BMS_Temperatur "battery temperature / Momentanwert: Temperatur der Traktionsbatterie";
CM_ SG_ 1438 BMS_IstVorlaufTemperatur "Aktuelle Vorlauftemperatur der Batterie";
CM_ SG_ 1438 BMS_Fehler_NTKreis "Fehler im NTKreis, HV-Batterie wird nicht klimatisiert
(Fehler, Fehlerfrei) ";
CM_ SG_ 1438 BMS_Fehlerstatus_EWP_02 "Fehlerstatus der elektrischen Wasserpumpe der HV-Batterie";
CM_ SG_ 1438 BMS_SollVolumenstrom "Soll Volumenstrom für Kühlkreislauf Batterie";
CM_ SG_ 1438 BMS_Batterie_Voko_Anf "Anforderung des BMC die Bauteilvorkonditionierung der HV-Batterie durchzuführen.";
CM_ SG_ 1438 BMS_SollVorlauftemperatur "Soll_Vorlauftemperatur_Kühlmedium in °C";
CM_ SG_ 1438 BMS_IstRuecklaufTemperatur_02 "Aktuelle Ruecklauftemperatur der Batterie";
CM_ SG_ 1482 BMS_07_CRC "Für MLB:
'Berechnung siehe Lastenheft 'Kommunikationsabsicherung für FlexRay und CAN''

Ab MQB und MLBevo:
'Berechnung siehe Lastenheft 'End-to-End Kommunikationsabsicherung''

Endwerte siehe Begleitdokument 'S-PDU Kennungsfolgen'";
CM_ SG_ 1482 BMS_Energieinhalt "aktuell nutzbarer Energieinhalt der HV-Batterie
(bezogen auf ein definiertes mittleres Belastungsprofil)";
CM_ SG_ 1482 BMS_Ladevorgang_aktiv "Signalisiert aktiven Ladevorgang, Ladegerät und DC/DC aktiv.
Signal bleibt nach Kl.15 ein aktiv, bis ESP_Stillstandsflag gelöscht.

Abhängigkeit zu BMS_Energieinhalt";
CM_ SG_ 1482 BMS_Batteriediagnose "Anzeige von Textwarnungen";
CM_ SG_ 1482 BMS_Freig_max_Performanz "Freigabe der Komponente, dass eine maximale Leistung zur Verfügung gestellt werden kann.";
CM_ SG_ 1482 BMS_Balancing_Aktiv "Signal zeigt an, ob mindestens eine Zelle der HV Batterie balanciert wird";
CM_ SG_ 1482 BMS_MaxEnergieinhalt "maximaler nutzbarer Energieinhalt der HV-Batterie (bezogen auf Last KBI_RWDS_Lastprofil bei SOC=100%)
Abhängig von KBI_RWDS_Lastprofil";
CM_ SG_ 1482 BMS_Ausgleichsladung_Anf "BMS wünscht eine Ausgleichsladung
Flag derzeit ungenutzt, da BalancingModus im Detail noch nicht geklärt.";
CM_ SG_ 1482 BMS_Gesamtst_Spgfreiheit "0 = Funktion nicht aktiviert
1 = HV-System spannungsfrei (U_Zwkr von BMS, LE und Ladegerät < 20V, DCLadestecker nicht gesteckt und Service Disconnect entriegelt)
2 = HV-System nicht spannungsfrei (U_Zwkr von BMS, LE und Ladegerät >= 20V, Ladestecker ges";
CM_ SG_ 1482 BMS_RIso_Ext "Minimum des Isolationswiderstands zwischen Batteriegehäuse und HV+ bzw. Batteriegehäuse und HV- bei geschlossenen Schützen (externe Iso Messung)";
CM_ SG_ 1482 BMS_KundenWarnung "Kunden Warnung aufgrund eines Batteriefehlers";
CM_ SG_ 1482 BMS_Fehler_KuehlkreislaufLeckage "Bei einer Leckage im Kühlkreislauf wird dieser Fehler gesetzt.";
CM_ SG_ 2527679979 BMS_HV_Auszeit_Status "Status HV-Auszeit.";
CM_ SG_ 2527679979 BMS_HV_Auszeit "Zeit seit letzter Hochvoltaktivität.";
CM_ SG_ 2527679979 BMS_Kapazitaet "Gesamtenergiekapazitaet der HV-Batterie unter Berücksichtigung der Alterung";
CM_ SG_ 2527679979 BMS_SOC_Kaltstart "Abhängig von der notwendigen Kaltstartleistung berechneter SOC Wert.";
CM_ SG_ 2527679979 BMS_max_Grenz_SOC "oberer Grenz SOC - Betriebsstrategie";
CM_ SG_ 2527679979 BMS_min_Grenz_SOC "unterer Grenz SOC - Betriebsstrategie";
BA_DEF_  "DBName" STRING ;
BA_DEF_  "GenNWMApBusSleep" STRING ;
BA_DEF_  "GenNWMApCanNormal" STRING ;
BA_DEF_  "GenNWMApCanOff" STRING ;
BA_DEF_  "GenNWMApCanOn" STRING ;
BA_DEF_  "GenNWMApCanSleep" STRING ;
BA_DEF_  "GenNWMApCanWakeUp" STRING ;
BA_DEF_  "GenNWMGotoMode_Awake" STRING ;
BA_DEF_  "GenNWMGotoMode_BusSleep" STRING ;
BA_DEF_  "GenNWMSleepTime" INT 0 1000000;
BA_DEF_  "GenNWMTalkNM" STRING ;
BA_DEF_  "Manufacturer" STRING ;
BA_DEF_  "NmhBaseAddress" HEX 0 536870911;
BA_DEF_  "NmhMessageCount" INT 0 1024;
BA_DEF_  "NmType" STRING ;
BA_DEF_  "VAGTP20_SetupMessageCount" INT 0 255;
BA_DEF_  "VAGTP20_SetupStartAddress" HEX 0 2047;
BA_DEF_  "VersionDay" INT 1 31;
BA_DEF_  "VersionMonth" INT 1 12;
BA_DEF_  "VersionWeek" INT 1 52;
BA_DEF_  "VersionYear" INT 0 99;
BA_DEF_  "VersionNumber" INT 0 65535;
BA_DEF_  "BusType" STRING ;
BA_DEF_  "Baudrate" INT 1 1000000;
BA_DEF_  "SamplePointMin" INT 1 100;
BA_DEF_  "SamplePointMax" INT 1 100;
BA_DEF_  "SyncJumpWidthMin" INT 1 4;
BA_DEF_  "SyncJumpWidthMax" INT 1 4;
BA_DEF_  "NBTMin" INT 1 30;
BA_DEF_  "NBTMax" INT 1 30;
BA_DEF_  "NmhTimeoutTimer" INT 0 65535;
BA_DEF_  "NmhWaitBusSleepTimer" INT 0 65535;
BA_DEF_  "NmhPrepareBusSleepTimer" INT 0 65535;
BA_DEF_  "NmhLongTimer" INT 0 65535;
BA_DEF_  "NmhNStart" INT 0 255;
BA_DEF_ BU_  "GenNodAutoGenDsp" ENUM  "No","Yes";
BA_DEF_ BU_  "GenNodAutoGenSnd" ENUM  "No","Yes";
BA_DEF_ BU_  "GenNodSleepTime" INT 0 1000000;
BA_DEF_ BU_  "ILUsed" ENUM  "No","Yes";
BA_DEF_ BU_  "ECUVariantDefault" ENUM  "No","Yes";
BA_DEF_ BU_  "ECUVariantGroup" STRING ;
BA_DEF_ BU_  "NodeLayerModules" STRING ;
BA_DEF_ BU_  "NmhNode" ENUM  "No","Yes";
BA_DEF_ BU_  "NmNode" ENUM  "No","Yes";
BA_DEF_ BO_  "DiagRequest" ENUM  "No","Yes";
BA_DEF_ BO_  "DiagResponse" ENUM  "No","Yes";
BA_DEF_ BO_  "DiagState" ENUM  "No","Yes";
BA_DEF_ BO_  "GenMsgChkConstant" HEX 0 4095;
BA_DEF_ BO_  "GenMsgCycleTime" INT 0 65535;
BA_DEF_ BO_  "GenMsgCycleTimeFast" INT 0 65535;
BA_DEF_ BO_  "GenMsgDelayTime" INT 0 100000;
BA_DEF_ BO_  "GenMsgILSupport" ENUM  "No","Yes";
BA_DEF_ BO_  "GenMsgNrOfRepetition" INT 0 100;
BA_DEF_ BO_  "GenMsgPDUConstants" STRING ;
BA_DEF_ BO_  "GenMsgSendType" ENUM  "Cyclic","not_used","not_used","not_used","not_used","not_used","not_used","IfActive","NoMsgSendType";
BA_DEF_ BO_  "GenMsgStartDelayTime" INT 0 100000;
BA_DEF_ BO_  "NmMessage" ENUM  "No","Yes";
BA_DEF_ BO_  "NmhMessage" ENUM  "No","Yes";
BA_DEF_ BO_  "MsgType" ENUM  "Application","NM ","NMH","TP2.0","ISO-TP ","BAP","EID","KS","XCP_PRE_CONFIGURED","XCP_RUNTIME_CONFIGURED";
BA_DEF_ BO_  "VAGTP20_API" HEX 0 255;
BA_DEF_ BO_  "VAGTP20_DynConnection" ENUM  "No","Yes";
BA_DEF_ BO_  "VAGTP20_DynSetup" ENUM  "No","Yes";
BA_DEF_ BO_  "VAGTP20_StatConnection" ENUM  "No","Yes";
BA_DEF_ SG_  "GenSigActiveRepetitions" INT -2147483648 2147483647;
BA_DEF_ SG_  "GenSigInactiveValue" INT -2147483648 2147483647;
BA_DEF_ SG_  "GenSigSendType" ENUM  "Cyclic","OnWrite","OnWriteWithRepetition","OnChange","OnChangeWithRepetition","IfActive","IfActiveWithRepetition","NoSigSendType","OnChangeAndIfActive","OnChangeAndIfActiveWithRepetition";
BA_DEF_ SG_  "GenSigStartValue" INT -2147483648 2147483647;
BA_DEF_ SG_  "NWM-WakeupAllowed" ENUM  "No","Yes";
BA_DEF_ SG_  "GenSigFuncType" ENUM  "NoFunction","MsgCounter","CRC-8","XOR","XOR-2","DatedBit","SW-Kl15","CHK","Constant","Protocol","CRC-8-SAE_J1850","CRC-32","DataLength","DataID","MsgCounter16","SOK-Signatur","Cluster";
BA_DEF_ SG_  "GenSigSwitchedByIgnition" ENUM  "No","Yes";
BA_DEF_ SG_  "Fehlerwert" HEX 0 2147483647;
BA_DEF_ SG_  "GenSigMissingSourceValue" HEX 0 2147483647;
BA_DEF_REL_ BU_SG_REL_  "GenSigTimeoutTime" INT 0 65535;
BA_DEF_DEF_  "DBName" "";
BA_DEF_DEF_  "GenNWMApBusSleep" "";
BA_DEF_DEF_  "GenNWMApCanNormal" "";
BA_DEF_DEF_  "GenNWMApCanOff" "";
BA_DEF_DEF_  "GenNWMApCanOn" "";
BA_DEF_DEF_  "GenNWMApCanSleep" "";
BA_DEF_DEF_  "GenNWMApCanWakeUp" "";
BA_DEF_DEF_  "GenNWMGotoMode_Awake" "";
BA_DEF_DEF_  "GenNWMGotoMode_BusSleep" "";
BA_DEF_DEF_  "GenNWMSleepTime" 0;
BA_DEF_DEF_  "GenNWMTalkNM" "";
BA_DEF_DEF_  "Manufacturer" "";
BA_DEF_DEF_  "NmhBaseAddress" 0;
BA_DEF_DEF_  "NmhMessageCount" 1;
BA_DEF_DEF_  "NmType" "None";
BA_DEF_DEF_  "VAGTP20_SetupMessageCount" 0;
BA_DEF_DEF_  "VAGTP20_SetupStartAddress" 0;
BA_DEF_DEF_  "VersionDay" 18;
BA_DEF_DEF_  "VersionMonth" 7;
BA_DEF_DEF_  "VersionWeek" 29;
BA_DEF_DEF_  "VersionYear" 19;
BA_DEF_DEF_  "VersionNumber" 0;
BA_DEF_DEF_  "BusType" "";
BA_DEF_DEF_  "Baudrate" 1;
BA_DEF_DEF_  "SamplePointMin" 1;
BA_DEF_DEF_  "SamplePointMax" 1;
BA_DEF_DEF_  "SyncJumpWidthMin" 1;
BA_DEF_DEF_  "SyncJumpWidthMax" 1;
BA_DEF_DEF_  "NBTMin" 10;
BA_DEF_DEF_  "NBTMax" 20;
BA_DEF_DEF_  "NmhTimeoutTimer" 0;
BA_DEF_DEF_  "NmhWaitBusSleepTimer" 0;
BA_DEF_DEF_  "NmhPrepareBusSleepTimer" 0;
BA_DEF_DEF_  "NmhLongTimer" 0;
BA_DEF_DEF_  "NmhNStart" 0;
BA_DEF_DEF_  "GenNodAutoGenDsp" "Yes";
BA_DEF_DEF_  "GenNodAutoGenSnd" "Yes";
BA_DEF_DEF_  "GenNodSleepTime" 0;
BA_DEF_DEF_  "ILUsed" "Yes";
BA_DEF_DEF_  "ECUVariantDefault" "Yes";
BA_DEF_DEF_  "ECUVariantGroup" "";
BA_DEF_DEF_  "NodeLayerModules" "";
BA_DEF_DEF_  "NmhNode" "Yes";
BA_DEF_DEF_  "NmNode" "No";
BA_DEF_DEF_REL_ "GenSigTimeoutTime" 0;
BA_DEF_DEF_  "DiagRequest" "No";
BA_DEF_DEF_  "DiagResponse" "No";
BA_DEF_DEF_  "DiagState" "No";
BA_DEF_DEF_  "GenMsgChkConstant" 0;
BA_DEF_DEF_  "GenMsgCycleTime" 0;
BA_DEF_DEF_  "GenMsgCycleTimeFast" 0;
BA_DEF_DEF_  "GenMsgDelayTime" 0;
BA_DEF_DEF_  "GenMsgILSupport" "No";
BA_DEF_DEF_  "GenMsgNrOfRepetition" 0;
BA_DEF_DEF_  "GenMsgPDUConstants" "";
BA_DEF_DEF_  "GenMsgSendType" "NoMsgSendType";
BA_DEF_DEF_  "GenMsgStartDelayTime" 0;
BA_DEF_DEF_  "NmMessage" "No";
BA_DEF_DEF_  "NmhMessage" "No";
BA_DEF_DEF_  "MsgType" "Application";
BA_DEF_DEF_  "VAGTP20_API" 0;
BA_DEF_DEF_  "VAGTP20_DynConnection" "No";
BA_DEF_DEF_  "VAGTP20_DynSetup" "No";
BA_DEF_DEF_  "VAGTP20_StatConnection" "No";
BA_DEF_DEF_  "GenSigActiveRepetitions" 0;
BA_DEF_DEF_  "GenSigInactiveValue" 0;
BA_DEF_DEF_  "GenSigSendType" "NoSigSendType";
BA_DEF_DEF_  "GenSigStartValue" 0;
BA_DEF_DEF_  "NWM-WakeupAllowed" "No";
BA_DEF_DEF_  "GenSigFuncType" "NoFunction";
BA_DEF_DEF_  "GenSigSwitchedByIgnition" "Yes";
BA_DEF_DEF_  "Fehlerwert" 0;
BA_DEF_DEF_  "GenSigMissingSourceValue" 0;
BA_ "NmhNStart" 20;
BA_ "NmhLongTimer" 200;
BA_ "NmhPrepareBusSleepTimer" 500;
BA_ "NmhWaitBusSleepTimer" 750;
BA_ "NmhTimeoutTimer" 1000;
BA_ "SyncJumpWidthMax" 4;
BA_ "SyncJumpWidthMin" 2;
BA_ "SamplePointMax" 84;
BA_ "SamplePointMin" 80;
BA_ "Baudrate" 500000;
BA_ "BusType" "CAN";
BA_ "VersionNumber" 1801;
BA_ "VAGTP20_SetupStartAddress" 512;
BA_ "VAGTP20_SetupMessageCount" 128;
BA_ "NmType" "NM-High";
BA_ "NmhMessageCount" 256;
BA_ "NmhBaseAddress" 452984832;
BA_ "Manufacturer" "VAG";
BA_ "GenNWMTalkNM" "Nmh_ReqNetOn()";
BA_ "GenNWMSleepTime" 4000;
BA_ "GenNWMGotoMode_BusSleep" "Nmh_ReqNetOff()";
BA_ "GenNWMGotoMode_Awake" "Nmh_ReqNetOn()";
BA_ "GenNWMApCanWakeUp" "apCanWakeUp()";
BA_ "GenNWMApCanSleep" "apCanSleep()";
BA_ "GenNWMApCanOn" "NMIndnetOn()";
BA_ "GenNWMApCanOff" "NMIndnetOff()";
BA_ "GenNWMApCanNormal" "apCanNormal()";
BA_ "GenNWMApBusSleep" "NMIndNetSDN()";
BA_ "DBName" "MLBevo_HCAN";
BA_ "NodeLayerModules" BU_ AWC "NMHigh.DLL";
BA_ "ECUVariantGroup" BU_ AWC "AWC";
BA_ "GenNodSleepTime" BU_ AWC 4000;
BA_ "NmhNode" BU_ BAP_Tester 0;
BA_ "ECUVariantGroup" BU_ BAP_Tester "BAP";
BA_ "GenNodSleepTime" BU_ BAP_Tester 4000;
BA_ "NodeLayerModules" BU_ BMC_MLBevo "NMHigh.DLL";
BA_ "ECUVariantGroup" BU_ BMC_MLBevo "BMS_HV";
BA_ "GenNodSleepTime" BU_ BMC_MLBevo 4000;
BA_ "NodeLayerModules" BU_ BMS_MV "NMHigh.DLL";
BA_ "ECUVariantGroup" BU_ BMS_MV "BMS_MV";
BA_ "GenNodSleepTime" BU_ BMS_MV 4000;
BA_ "NodeLayerModules" BU_ BMS_NV "NMHigh.DLL";
BA_ "ECUVariantGroup" BU_ BMS_NV "BMS_NV";
BA_ "GenNodSleepTime" BU_ BMS_NV 4000;
BA_ "NodeLayerModules" BU_ DCDC_800V_PAG "NMHigh.DLL";
BA_ "ECUVariantGroup" BU_ DCDC_800V_PAG "DCDC";
BA_ "ECUVariantDefault" BU_ DCDC_800V_PAG 0;
BA_ "GenNodSleepTime" BU_ DCDC_800V_PAG 4000;
BA_ "NodeLayerModules" BU_ DCDC_HV "NMHigh.DLL";
BA_ "ECUVariantGroup" BU_ DCDC_HV "DCDC";
BA_ "ECUVariantDefault" BU_ DCDC_HV 0;
BA_ "GenNodSleepTime" BU_ DCDC_HV 4000;
BA_ "NodeLayerModules" BU_ DCDC_HV_02 "NMHigh.DLL";
BA_ "ECUVariantGroup" BU_ DCDC_HV_02 "DCDC2";
BA_ "GenNodSleepTime" BU_ DCDC_HV_02 4000;
BA_ "NodeLayerModules" BU_ DCDC_IHEV "NMHigh.DLL";
BA_ "ECUVariantGroup" BU_ DCDC_IHEV "DCDC_IHEV";
BA_ "GenNodSleepTime" BU_ DCDC_IHEV 4000;
BA_ "NodeLayerModules" BU_ FCU_MLBevo_FCEV "NMHigh.DLL";
BA_ "ECUVariantGroup" BU_ FCU_MLBevo_FCEV "FCU";
BA_ "GenNodSleepTime" BU_ FCU_MLBevo_FCEV 4000;
BA_ "NodeLayerModules" BU_ Gateway "NMHigh.DLL";
BA_ "ECUVariantGroup" BU_ Gateway "Gateway";
BA_ "GenNodSleepTime" BU_ Gateway 4000;
BA_ "NodeLayerModules" BU_ Gateway_PAG "NMHigh.DLL";
BA_ "ECUVariantGroup" BU_ Gateway_PAG "Gateway";
BA_ "ECUVariantDefault" BU_ Gateway_PAG 0;
BA_ "GenNodSleepTime" BU_ Gateway_PAG 4000;
BA_ "NodeLayerModules" BU_ Ladegeraet_2 "NMHigh.DLL";
BA_ "ECUVariantGroup" BU_ Ladegeraet_2 "OBC2";
BA_ "GenNodSleepTime" BU_ Ladegeraet_2 4000;
BA_ "NodeLayerModules" BU_ Ladegeraet_Konzern "NMHigh.DLL";
BA_ "ECUVariantGroup" BU_ Ladegeraet_Konzern "OBC";
BA_ "GenNodSleepTime" BU_ Ladegeraet_Konzern 4000;
BA_ "NodeLayerModules" BU_ LE1 "NMHigh.DLL";
BA_ "ECUVariantGroup" BU_ LE1 "LE";
BA_ "ECUVariantDefault" BU_ LE1 0;
BA_ "GenNodSleepTime" BU_ LE1 4000;
BA_ "NodeLayerModules" BU_ LE2 "NMHigh.DLL";
BA_ "ECUVariantGroup" BU_ LE2 "LE2";
BA_ "GenNodSleepTime" BU_ LE2 4000;
BA_ "NodeLayerModules" BU_ LE2_3_MLBevo_LB "NMHigh.DLL";
BA_ "ECUVariantGroup" BU_ LE2_3_MLBevo_LB "LE2";
BA_ "ECUVariantDefault" BU_ LE2_3_MLBevo_LB 0;
BA_ "GenNodSleepTime" BU_ LE2_3_MLBevo_LB 4000;
BA_ "NodeLayerModules" BU_ LE_MLBevo "NMHigh.DLL";
BA_ "ECUVariantGroup" BU_ LE_MLBevo "LE";
BA_ "GenNodSleepTime" BU_ LE_MLBevo 4000;
BA_ "NmhNode" BU_ LE_MLBevo_LB 0;
BA_ "ECUVariantGroup" BU_ LE_MLBevo_LB "LE";
BA_ "ECUVariantDefault" BU_ LE_MLBevo_LB 0;
BA_ "GenNodSleepTime" BU_ LE_MLBevo_LB 4000;
BA_ "NodeLayerModules" BU_ Sub_Gateway "NMHigh.DLL";
BA_ "ECUVariantGroup" BU_ Sub_Gateway "Sub_Gateway";
BA_ "GenNodSleepTime" BU_ Sub_Gateway 4000;
BA_ "NodeLayerModules" BU_ TME "NMHigh.DLL";
BA_ "ECUVariantGroup" BU_ TME "TME";
BA_ "GenNodSleepTime" BU_ TME 4000;
BA_ "GenMsgSendType" BO_ 64 0;
BA_ "GenMsgPDUConstants" BO_ 64 "0x40,0x40,0x40,0x40,0x40,0x40,0x40,0x40,0x40,0x40,0x40,0x40,0x40,0x40,0x40,0x40";
BA_ "GenMsgNrOfRepetition" BO_ 64 5;
BA_ "GenMsgILSupport" BO_ 64 1;
BA_ "GenMsgDelayTime" BO_ 64 10;
BA_ "GenMsgCycleTimeFast" BO_ 64 10;
BA_ "GenMsgCycleTime" BO_ 64 40;
BA_ "GenMsgChkConstant" BO_ 64 64;
BA_ "GenMsgStartDelayTime" BO_ 2589283757 100;
BA_ "GenMsgSendType" BO_ 2589283757 0;
BA_ "GenMsgILSupport" BO_ 2589283757 1;
BA_ "GenMsgCycleTime" BO_ 2589283757 1000;
BA_ "GenMsgSendType" BO_ 2589283607 0;
BA_ "GenMsgPDUConstants" BO_ 2589283607 "0xfb,0xee,0x5d,0x2d,0xfa,0x85,0x27,0xd4,0xc9,0xc4,0xa5,0x45,0x5f,0x76,0xa3,0x89";
BA_ "GenMsgILSupport" BO_ 2589283607 1;
BA_ "GenMsgDelayTime" BO_ 2589283607 100;
BA_ "GenMsgCycleTime" BO_ 2589283607 200;
BA_ "GenMsgSendType" BO_ 2589283618 0;
BA_ "GenMsgILSupport" BO_ 2589283618 1;
BA_ "GenMsgDelayTime" BO_ 2589283618 100;
BA_ "GenMsgCycleTime" BO_ 2589283618 200;
BA_ "GenMsgSendType" BO_ 2589283633 0;
BA_ "GenMsgILSupport" BO_ 2589283633 1;
BA_ "GenMsgDelayTime" BO_ 2589283633 100;
BA_ "GenMsgCycleTime" BO_ 2589283633 1000;
BA_ "GenMsgSendType" BO_ 2589283685 0;
BA_ "GenMsgILSupport" BO_ 2589283685 1;
BA_ "GenMsgCycleTime" BO_ 2589283685 1000;
BA_ "GenMsgSendType" BO_ 2589283394 0;
BA_ "GenMsgILSupport" BO_ 2589283394 1;
BA_ "GenMsgCycleTime" BO_ 2589283394 500;
BA_ "MsgType" BO_ 2536720384 5;
BA_ "MsgType" BO_ 2536720385 5;
BA_ "MsgType" BO_ 2536720400 5;
BA_ "MsgType" BO_ 2536711424 5;
BA_ "MsgType" BO_ 2536711425 5;
BA_ "MsgType" BO_ 2536711426 5;
BA_ "MsgType" BO_ 2536711427 5;
BA_ "MsgType" BO_ 2536711428 5;
BA_ "MsgType" BO_ 2536711429 5;
BA_ "MsgType" BO_ 2536711440 5;
BA_ "MsgType" BO_ 2536767264 5;
BA_ "MsgType" BO_ 2536767280 5;
BA_ "MsgType" BO_ 2536706306 5;
BA_ "MsgType" BO_ 2536706310 5;
BA_ "MsgType" BO_ 2536706320 5;
BA_ "GenMsgSendType" BO_ 1615 0;
BA_ "GenMsgILSupport" BO_ 1615 1;
BA_ "GenMsgDelayTime" BO_ 1615 40;
BA_ "GenMsgCycleTime" BO_ 1615 1000;
BA_ "GenMsgSendType" BO_ 1626 0;
BA_ "GenMsgNrOfRepetition" BO_ 1626 10;
BA_ "GenMsgILSupport" BO_ 1626 1;
BA_ "GenMsgDelayTime" BO_ 1626 50;
BA_ "GenMsgCycleTimeFast" BO_ 1626 100;
BA_ "GenMsgCycleTime" BO_ 1626 1000;
BA_ "GenMsgSendType" BO_ 401 0;
BA_ "GenMsgPDUConstants" BO_ 401 "0x7d,0x0e,0xaf,0x0b,0x24,0x58,0x88,0x9e,0x89,0x3a,0x81,0x61,0x4e,0xe3,0x04,0x1f";
BA_ "GenMsgILSupport" BO_ 401 1;
BA_ "GenMsgCycleTime" BO_ 401 10;
BA_ "GenMsgSendType" BO_ 417 0;
BA_ "GenMsgILSupport" BO_ 417 1;
BA_ "GenMsgCycleTime" BO_ 417 100;
BA_ "GenMsgSendType" BO_ 925 0;
BA_ "GenMsgILSupport" BO_ 925 1;
BA_ "GenMsgCycleTime" BO_ 925 100;
BA_ "GenMsgSendType" BO_ 1442 0;
BA_ "GenMsgPDUConstants" BO_ 1442 "0xeb,0x4c,0x44,0xaf,0x21,0x8d,0x01,0x58,0xfa,0x93,0xdb,0x89,0x15,0x10,0x4a,0x61";
BA_ "GenMsgILSupport" BO_ 1442 1;
BA_ "GenMsgDelayTime" BO_ 1442 20;
BA_ "GenMsgCycleTime" BO_ 1442 500;
BA_ "GenMsgSendType" BO_ 687 0;
BA_ "GenMsgILSupport" BO_ 687 1;
BA_ "GenMsgCycleTime" BO_ 687 50;
BA_ "GenMsgSendType" BO_ 1438 0;
BA_ "GenMsgILSupport" BO_ 1438 1;
BA_ "GenMsgCycleTime" BO_ 1438 500;
BA_ "GenMsgSendType" BO_ 1482 0;
BA_ "GenMsgPDUConstants" BO_ 1482 "0x43,0x43,0x43,0x43,0x43,0x43,0x43,0x43,0x43,0x43,0x43,0x43,0x43,0x43,0x43,0x43";
BA_ "GenMsgILSupport" BO_ 1482 1;
BA_ "GenMsgDelayTime" BO_ 1482 50;
BA_ "GenMsgCycleTime" BO_ 1482 500;
BA_ "GenMsgChkConstant" BO_ 1482 67;
BA_ "GenMsgSendType" BO_ 2527679979 0;
BA_ "GenMsgILSupport" BO_ 2527679979 1;
BA_ "GenMsgCycleTime" BO_ 2527679979 1000;
BA_ "GenSigSwitchedByIgnition" SG_ 3221225472 DGN_Verlernzaehler 0;
BA_ "GenSigSendType" SG_ 3221225472 DGN_Verlernzaehler 0;
BA_ "Fehlerwert" SG_ 3221225472 KBI_Kilometerstand 1048575;
BA_ "GenSigSwitchedByIgnition" SG_ 3221225472 KBI_Kilometerstand 0;
BA_ "GenSigStartValue" SG_ 3221225472 KBI_Kilometerstand 1048574;
BA_ "GenSigSendType" SG_ 3221225472 KBI_Kilometerstand 0;
BA_ "GenSigSwitchedByIgnition" SG_ 3221225472 UH_Jahr 0;
BA_ "GenSigSendType" SG_ 3221225472 UH_Jahr 0;
BA_ "Fehlerwert" SG_ 3221225472 UH_Monat 15;
BA_ "GenSigSwitchedByIgnition" SG_ 3221225472 UH_Monat 0;
BA_ "GenSigSendType" SG_ 3221225472 UH_Monat 0;
BA_ "GenSigSwitchedByIgnition" SG_ 3221225472 UH_Tag 0;
BA_ "GenSigSendType" SG_ 3221225472 UH_Tag 0;
BA_ "GenSigSwitchedByIgnition" SG_ 3221225472 UH_Stunde 0;
BA_ "GenSigSendType" SG_ 3221225472 UH_Stunde 0;
BA_ "GenSigSwitchedByIgnition" SG_ 3221225472 UH_Minute 0;
BA_ "GenSigSendType" SG_ 3221225472 UH_Minute 0;
BA_ "GenSigSwitchedByIgnition" SG_ 3221225472 UH_Sekunde 0;
BA_ "GenSigSendType" SG_ 3221225472 UH_Sekunde 0;
BA_ "GenSigSwitchedByIgnition" SG_ 3221225472 Kombi_02_alt 0;
BA_ "GenSigFuncType" SG_ 3221225472 Kombi_02_alt 5;
BA_ "GenSigStartValue" SG_ 3221225472 Kombi_02_alt 1;
BA_ "GenSigSendType" SG_ 3221225472 Kombi_02_alt 0;
BA_ "GenSigSwitchedByIgnition" SG_ 3221225472 Uhrzeit_01_alt 0;
BA_ "GenSigFuncType" SG_ 3221225472 Uhrzeit_01_alt 5;
BA_ "GenSigStartValue" SG_ 3221225472 Uhrzeit_01_alt 1;
BA_ "GenSigSendType" SG_ 3221225472 Uhrzeit_01_alt 0;
BA_ "GenSigSwitchedByIgnition" SG_ 3221225472 EMG_CALID_CVN_MUX 0;
BA_ "GenSigSendType" SG_ 3221225472 EMG_CALID_CVN_MUX 0;
BA_ "GenSigSwitchedByIgnition" SG_ 3221225472 EMG_CVN_VLD 0;
BA_ "GenSigSendType" SG_ 3221225472 EMG_CVN_VLD 0;
BA_ "GenSigSwitchedByIgnition" SG_ 3221225472 EMG_CALID_Index_01 0;
BA_ "GenSigStartValue" SG_ 3221225472 EMG_CALID_Index_01 48;
BA_ "GenSigSwitchedByIgnition" SG_ 3221225472 EMG_CALID_Index_05 0;
BA_ "GenSigStartValue" SG_ 3221225472 EMG_CALID_Index_05 48;
BA_ "GenSigSwitchedByIgnition" SG_ 3221225472 EMG_CALID_Index_09 0;
BA_ "GenSigStartValue" SG_ 3221225472 EMG_CALID_Index_09 48;
BA_ "GenSigSwitchedByIgnition" SG_ 3221225472 EMG_CALID_Index_13 0;
BA_ "GenSigStartValue" SG_ 3221225472 EMG_CALID_Index_13 48;
BA_ "GenSigSwitchedByIgnition" SG_ 3221225472 EMG_CALID_Index_02 0;
BA_ "GenSigStartValue" SG_ 3221225472 EMG_CALID_Index_02 48;
BA_ "GenSigSwitchedByIgnition" SG_ 3221225472 EMG_CALID_Index_06 0;
BA_ "GenSigStartValue" SG_ 3221225472 EMG_CALID_Index_06 48;
BA_ "GenSigSwitchedByIgnition" SG_ 3221225472 EMG_CALID_Index_10 0;
BA_ "GenSigStartValue" SG_ 3221225472 EMG_CALID_Index_10 48;
BA_ "GenSigSwitchedByIgnition" SG_ 3221225472 EMG_CALID_Index_14 0;
BA_ "GenSigStartValue" SG_ 3221225472 EMG_CALID_Index_14 48;
BA_ "GenSigSwitchedByIgnition" SG_ 3221225472 EMG_CALID_Index_03 0;
BA_ "GenSigStartValue" SG_ 3221225472 EMG_CALID_Index_03 48;
BA_ "GenSigSwitchedByIgnition" SG_ 3221225472 EMG_CALID_Index_07 0;
BA_ "GenSigStartValue" SG_ 3221225472 EMG_CALID_Index_07 48;
BA_ "GenSigSwitchedByIgnition" SG_ 3221225472 EMG_CALID_Index_11 0;
BA_ "GenSigStartValue" SG_ 3221225472 EMG_CALID_Index_11 48;
BA_ "GenSigSwitchedByIgnition" SG_ 3221225472 EMG_CALID_Index_15 0;
BA_ "GenSigStartValue" SG_ 3221225472 EMG_CALID_Index_15 48;
BA_ "GenSigSwitchedByIgnition" SG_ 3221225472 EMG_CALID_Index_04 0;
BA_ "GenSigStartValue" SG_ 3221225472 EMG_CALID_Index_04 48;
BA_ "GenSigSwitchedByIgnition" SG_ 3221225472 EMG_CALID_Index_08 0;
BA_ "GenSigStartValue" SG_ 3221225472 EMG_CALID_Index_08 48;
BA_ "GenSigSwitchedByIgnition" SG_ 3221225472 EMG_CALID_Index_12 0;
BA_ "GenSigStartValue" SG_ 3221225472 EMG_CALID_Index_12 48;
BA_ "GenSigSwitchedByIgnition" SG_ 3221225472 EMG_CALID_Index_16 0;
BA_ "GenSigStartValue" SG_ 3221225472 EMG_CALID_Index_16 48;
BA_ "GenSigSwitchedByIgnition" SG_ 3221225472 EMG_CVN_Byte_1 0;
BA_ "GenSigSwitchedByIgnition" SG_ 3221225472 EMG_CVN_Byte_2 0;
BA_ "GenSigSwitchedByIgnition" SG_ 3221225472 EMG_CVN_Byte_3 0;
BA_ "GenSigSwitchedByIgnition" SG_ 3221225472 EMG_CVN_Byte_4 0;
BA_ "GenSigSwitchedByIgnition" SG_ 3221225472 EMG_Komponentenfehler_01 0;
BA_ "GenSigStartValue" SG_ 3221225472 EMG_Komponentenfehler_01 2;
BA_ "GenSigSendType" SG_ 3221225472 EMG_Komponentenfehler_01 0;
BA_ "GenSigSwitchedByIgnition" SG_ 3221225472 EMG_Komponentenfehler_02 0;
BA_ "GenSigStartValue" SG_ 3221225472 EMG_Komponentenfehler_02 2;
BA_ "GenSigSendType" SG_ 3221225472 EMG_Komponentenfehler_02 0;
BA_ "GenSigSwitchedByIgnition" SG_ 3221225472 EMG_Komponentenfehler_03 0;
BA_ "GenSigStartValue" SG_ 3221225472 EMG_Komponentenfehler_03 2;
BA_ "GenSigSendType" SG_ 3221225472 EMG_Komponentenfehler_03 0;
BA_ "GenSigSwitchedByIgnition" SG_ 3221225472 EMG_Komponentenfehler_04 0;
BA_ "GenSigStartValue" SG_ 3221225472 EMG_Komponentenfehler_04 2;
BA_ "GenSigSendType" SG_ 3221225472 EMG_Komponentenfehler_04 0;
BA_ "GenSigSwitchedByIgnition" SG_ 3221225472 EMG_Komponentenfehler_05 0;
BA_ "GenSigStartValue" SG_ 3221225472 EMG_Komponentenfehler_05 2;
BA_ "GenSigSendType" SG_ 3221225472 EMG_Komponentenfehler_05 0;
BA_ "GenSigSwitchedByIgnition" SG_ 3221225472 EMG_Komponentenfehler_06 0;
BA_ "GenSigStartValue" SG_ 3221225472 EMG_Komponentenfehler_06 2;
BA_ "GenSigSendType" SG_ 3221225472 EMG_Komponentenfehler_06 0;
BA_ "GenSigSwitchedByIgnition" SG_ 3221225472 EMG_Komponentenfehler_07 0;
BA_ "GenSigStartValue" SG_ 3221225472 EMG_Komponentenfehler_07 2;
BA_ "GenSigSendType" SG_ 3221225472 EMG_Komponentenfehler_07 0;
BA_ "GenSigSwitchedByIgnition" SG_ 3221225472 EMG_Komponentenfehler_08 0;
BA_ "GenSigStartValue" SG_ 3221225472 EMG_Komponentenfehler_08 2;
BA_ "GenSigSendType" SG_ 3221225472 EMG_Komponentenfehler_08 0;
BA_ "GenSigSwitchedByIgnition" SG_ 3221225472 EMG_Komponentenfehler_09 0;
BA_ "GenSigStartValue" SG_ 3221225472 EMG_Komponentenfehler_09 2;
BA_ "GenSigSendType" SG_ 3221225472 EMG_Komponentenfehler_09 0;
BA_ "GenSigSwitchedByIgnition" SG_ 3221225472 EMG_Komponentenfehler_VLD 0;
BA_ "GenSigSendType" SG_ 3221225472 EMG_Komponentenfehler_VLD 0;
BA_ "GenSigSwitchedByIgnition" SG_ 3221225472 ESP_21_CRC 0;
BA_ "GenSigFuncType" SG_ 3221225472 ESP_21_CRC 2;
BA_ "GenSigSendType" SG_ 3221225472 ESP_21_CRC 0;
BA_ "GenSigSwitchedByIgnition" SG_ 3221225472 ESP_21_BZ 0;
BA_ "GenSigFuncType" SG_ 3221225472 ESP_21_BZ 1;
BA_ "GenSigSendType" SG_ 3221225472 ESP_21_BZ 0;
BA_ "Fehlerwert" SG_ 3221225472 BR_Eingriffsmoment 1023;
BA_ "GenSigSwitchedByIgnition" SG_ 3221225472 BR_Eingriffsmoment 0;
BA_ "GenSigStartValue" SG_ 3221225472 BR_Eingriffsmoment 1022;
BA_ "GenSigSendType" SG_ 3221225472 BR_Eingriffsmoment 0;
BA_ "GenSigSwitchedByIgnition" SG_ 3221225472 ESP_Diagnose 0;
BA_ "GenSigSendType" SG_ 3221225472 ESP_Diagnose 0;
BA_ "Fehlerwert" SG_ 3221225472 ESC_v_Signal_Qualifier_High_Low 7;
BA_ "GenSigSwitchedByIgnition" SG_ 3221225472 ESC_v_Signal_Qualifier_High_Low 0;
BA_ "GenSigStartValue" SG_ 3221225472 ESC_v_Signal_Qualifier_High_Low 6;
BA_ "GenSigSendType" SG_ 3221225472 ESC_v_Signal_Qualifier_High_Low 0;
BA_ "GenSigSwitchedByIgnition" SG_ 3221225472 ESP_Vorsteuerung 0;
BA_ "GenSigSendType" SG_ 3221225472 ESP_Vorsteuerung 0;
BA_ "GenSigSwitchedByIgnition" SG_ 3221225472 OBD_Schlechtweg 0;
BA_ "GenSigSendType" SG_ 3221225472 OBD_Schlechtweg 0;
BA_ "GenSigSwitchedByIgnition" SG_ 3221225472 OBD_QBit_Schlechtweg 0;
BA_ "GenSigStartValue" SG_ 3221225472 OBD_QBit_Schlechtweg 1;
BA_ "GenSigSendType" SG_ 3221225472 OBD_QBit_Schlechtweg 0;
BA_ "GenSigMissingSourceValue" SG_ 3221225472 ESP_v_Signal 65534;
BA_ "Fehlerwert" SG_ 3221225472 ESP_v_Signal 65535;
BA_ "GenSigSwitchedByIgnition" SG_ 3221225472 ESP_v_Signal 0;
BA_ "GenSigStartValue" SG_ 3221225472 ESP_v_Signal 65534;
BA_ "GenSigSendType" SG_ 3221225472 ESP_v_Signal 0;
BA_ "GenSigSwitchedByIgnition" SG_ 3221225472 ASR_Tastung_passiv 0;
BA_ "GenSigSendType" SG_ 3221225472 ASR_Tastung_passiv 0;
BA_ "GenSigSwitchedByIgnition" SG_ 3221225472 ESP_Tastung_passiv 0;
BA_ "GenSigSendType" SG_ 3221225472 ESP_Tastung_passiv 0;
BA_ "GenSigSwitchedByIgnition" SG_ 3221225472 ESP_Systemstatus 0;
BA_ "GenSigSendType" SG_ 3221225472 ESP_Systemstatus 0;
BA_ "GenSigSwitchedByIgnition" SG_ 3221225472 ASR_Schalteingriff 0;
BA_ "GenSigSendType" SG_ 3221225472 ASR_Schalteingriff 0;
BA_ "GenSigSwitchedByIgnition" SG_ 3221225472 ESP_QBit_v_Signal 0;
BA_ "GenSigStartValue" SG_ 3221225472 ESP_QBit_v_Signal 1;
BA_ "GenSigSendType" SG_ 3221225472 ESP_QBit_v_Signal 0;
BA_ "GenSigSwitchedByIgnition" SG_ 3221225472 ABS_Bremsung 0;
BA_ "GenSigSendType" SG_ 3221225472 ABS_Bremsung 0;
BA_ "GenSigSwitchedByIgnition" SG_ 3221225472 ASR_Anf 0;
BA_ "GenSigSendType" SG_ 3221225472 ASR_Anf 0;
BA_ "GenSigSwitchedByIgnition" SG_ 3221225472 MSR_Anf 0;
BA_ "GenSigSendType" SG_ 3221225472 MSR_Anf 0;
BA_ "GenSigSwitchedByIgnition" SG_ 3221225472 EBV_Eingriff 0;
BA_ "GenSigSendType" SG_ 3221225472 EBV_Eingriff 0;
BA_ "GenSigSwitchedByIgnition" SG_ 3221225472 EDS_Eingriff 0;
BA_ "GenSigSendType" SG_ 3221225472 EDS_Eingriff 0;
BA_ "GenSigSwitchedByIgnition" SG_ 3221225472 ESP_Eingriff 0;
BA_ "GenSigSendType" SG_ 3221225472 ESP_Eingriff 0;
BA_ "GenSigSwitchedByIgnition" SG_ 3221225472 ESP_ASP 0;
BA_ "GenSigSendType" SG_ 3221225472 ESP_ASP 0;
BA_ "GenSigSwitchedByIgnition" SG_ 3221225472 ESC_Neutralschaltung 0;
BA_ "GenSigSendType" SG_ 3221225472 ESC_Neutralschaltung 0;
BA_ "GenSigSwitchedByIgnition" SG_ 3221225472 SI_Sammel_SG_Fehler 0;
BA_ "GenSigStartValue" SG_ 3221225472 SI_Sammel_SG_Fehler 63;
BA_ "GenSigSendType" SG_ 3221225472 SI_Sammel_SG_Fehler 0;
BA_ "GenSigSwitchedByIgnition" SG_ 3221225472 SI_Diagnose_Aktiv 0;
BA_ "GenSigSendType" SG_ 3221225472 SI_Diagnose_Aktiv 3;
BA_ "GenSigSwitchedByIgnition" SG_ 3221225472 SI_QRS_Mode 0;
BA_ "GenSigSendType" SG_ 3221225472 SI_QRS_Mode 3;
BA_ "GenSigSwitchedByIgnition" SG_ 3221225472 SI_T_Mode 0;
BA_ "GenSigSendType" SG_ 3221225472 SI_T_Mode 3;
BA_ "GenSigSwitchedByIgnition" SG_ 3221225472 SI_NWDF 0;
BA_ "GenSigSendType" SG_ 3221225472 SI_NWDF 3;
BA_ "GenSigSwitchedByIgnition" SG_ 3221225472 SI_NWDF_gueltig 0;
BA_ "GenSigFuncType" SG_ 3221225472 SI_NWDF_gueltig 8;
BA_ "GenSigSendType" SG_ 3221225472 SI_NWDF_gueltig 3;
BA_ "GenSigSwitchedByIgnition" SG_ 3221225472 SI_Sammelfehler 0;
BA_ "GenSigSendType" SG_ 3221225472 SI_Sammelfehler 3;
BA_ "GenSigSendType" SG_ 3221225472 GW_KD_Fehler 3;
BA_ "GenSigSwitchedByIgnition" SG_ 3221225472 SI_T_Schutz 0;
BA_ "GenSigSendType" SG_ 3221225472 SI_T_Schutz 3;
BA_ "GenSigSwitchedByIgnition" SG_ 3221225472 SI_BUS_01 0;
BA_ "GenSigStartValue" SG_ 3221225472 SI_BUS_01 1;
BA_ "GenSigSendType" SG_ 3221225472 SI_BUS_01 3;
BA_ "GenSigSwitchedByIgnition" SG_ 3221225472 SI_BUS_02 0;
BA_ "GenSigStartValue" SG_ 3221225472 SI_BUS_02 1;
BA_ "GenSigSendType" SG_ 3221225472 SI_BUS_02 3;
BA_ "GenSigSwitchedByIgnition" SG_ 3221225472 SI_BUS_03 0;
BA_ "GenSigStartValue" SG_ 3221225472 SI_BUS_03 1;
BA_ "GenSigSendType" SG_ 3221225472 SI_BUS_03 3;
BA_ "GenSigSwitchedByIgnition" SG_ 3221225472 SI_BUS_04 0;
BA_ "GenSigStartValue" SG_ 3221225472 SI_BUS_04 1;
BA_ "GenSigSendType" SG_ 3221225472 SI_BUS_04 3;
BA_ "GenSigSwitchedByIgnition" SG_ 3221225472 SI_BUS_05 0;
BA_ "GenSigStartValue" SG_ 3221225472 SI_BUS_05 1;
BA_ "GenSigSendType" SG_ 3221225472 SI_BUS_05 3;
BA_ "GenSigSwitchedByIgnition" SG_ 3221225472 SI_BUS_06 0;
BA_ "GenSigStartValue" SG_ 3221225472 SI_BUS_06 1;
BA_ "GenSigSendType" SG_ 3221225472 SI_BUS_06 3;
BA_ "GenSigSwitchedByIgnition" SG_ 3221225472 SI_BUS_07 0;
BA_ "GenSigStartValue" SG_ 3221225472 SI_BUS_07 1;
BA_ "GenSigSendType" SG_ 3221225472 SI_BUS_07 3;
BA_ "GenSigSwitchedByIgnition" SG_ 3221225472 SI_BUS_08 0;
BA_ "GenSigStartValue" SG_ 3221225472 SI_BUS_08 1;
BA_ "GenSigSendType" SG_ 3221225472 SI_BUS_08 3;
BA_ "GenSigSwitchedByIgnition" SG_ 3221225472 SI_BUS_09 0;
BA_ "GenSigStartValue" SG_ 3221225472 SI_BUS_09 1;
BA_ "GenSigSendType" SG_ 3221225472 SI_BUS_09 3;
BA_ "GenSigSwitchedByIgnition" SG_ 3221225472 SI_BUS_10 0;
BA_ "GenSigStartValue" SG_ 3221225472 SI_BUS_10 1;
BA_ "GenSigSendType" SG_ 3221225472 SI_BUS_10 3;
BA_ "GenSigSwitchedByIgnition" SG_ 3221225472 SI_BUS_11 0;
BA_ "GenSigStartValue" SG_ 3221225472 SI_BUS_11 1;
BA_ "GenSigSendType" SG_ 3221225472 SI_BUS_11 3;
BA_ "GenSigSwitchedByIgnition" SG_ 3221225472 SI_BUS_12 0;
BA_ "GenSigStartValue" SG_ 3221225472 SI_BUS_12 1;
BA_ "GenSigSendType" SG_ 3221225472 SI_BUS_12 3;
BA_ "GenSigSwitchedByIgnition" SG_ 3221225472 SI_BUS_13 0;
BA_ "GenSigStartValue" SG_ 3221225472 SI_BUS_13 1;
BA_ "GenSigSendType" SG_ 3221225472 SI_BUS_13 3;
BA_ "GenSigSwitchedByIgnition" SG_ 3221225472 SI_BUS_14 0;
BA_ "GenSigStartValue" SG_ 3221225472 SI_BUS_14 1;
BA_ "GenSigSendType" SG_ 3221225472 SI_BUS_14 3;
BA_ "GenSigSwitchedByIgnition" SG_ 3221225472 SI_BUS_15 0;
BA_ "GenSigStartValue" SG_ 3221225472 SI_BUS_15 1;
BA_ "GenSigSendType" SG_ 3221225472 SI_BUS_15 3;
BA_ "GenSigSwitchedByIgnition" SG_ 3221225472 SI_Bus_Identifikation 0;
BA_ "GenSigSendType" SG_ 3221225472 SI_Bus_Identifikation 0;
BA_ "GenSigSwitchedByIgnition" SG_ 3221225472 SI_CAB 0;
BA_ "GenSigSendType" SG_ 3221225472 SI_CAB 3;
BA_ "GenSigSwitchedByIgnition" SG_ 3221225472 XCP_BMS_MV_CRO_01_Data 0;
BA_ "GenSigFuncType" SG_ 3221225472 XCP_BMS_MV_CRO_01_Data 9;
BA_ "GenSigSwitchedByIgnition" SG_ 64 Airbag_01_CRC 0;
BA_ "GenSigFuncType" SG_ 64 Airbag_01_CRC 2;
BA_ "GenSigSendType" SG_ 64 Airbag_01_CRC 0;
BA_ "GenSigSwitchedByIgnition" SG_ 64 Airbag_01_BZ 0;
BA_ "GenSigFuncType" SG_ 64 Airbag_01_BZ 1;
BA_ "GenSigSendType" SG_ 64 Airbag_01_BZ 0;
BA_ "GenSigSwitchedByIgnition" SG_ 64 AB_RGS_Anst 0;
BA_ "GenSigStartValue" SG_ 64 AB_RGS_Anst 8;
BA_ "GenSigSendType" SG_ 64 AB_RGS_Anst 0;
BA_ "GenSigSwitchedByIgnition" SG_ 64 AB_Front_Crash 0;
BA_ "GenSigSendType" SG_ 64 AB_Front_Crash 4;
BA_ "GenSigActiveRepetitions" SG_ 64 AB_Front_Crash 5;
BA_ "GenSigSwitchedByIgnition" SG_ 64 AB_Heck_Crash 0;
BA_ "GenSigSendType" SG_ 64 AB_Heck_Crash 4;
BA_ "GenSigActiveRepetitions" SG_ 64 AB_Heck_Crash 5;
BA_ "GenSigSwitchedByIgnition" SG_ 64 AB_SF_Crash 0;
BA_ "GenSigSendType" SG_ 64 AB_SF_Crash 4;
BA_ "GenSigActiveRepetitions" SG_ 64 AB_SF_Crash 5;
BA_ "GenSigSwitchedByIgnition" SG_ 64 AB_SB_Crash 0;
BA_ "GenSigSendType" SG_ 64 AB_SB_Crash 4;
BA_ "GenSigActiveRepetitions" SG_ 64 AB_SB_Crash 5;
BA_ "GenSigSwitchedByIgnition" SG_ 64 AB_Rollover_Crash 0;
BA_ "GenSigSendType" SG_ 64 AB_Rollover_Crash 4;
BA_ "GenSigActiveRepetitions" SG_ 64 AB_Rollover_Crash 5;
BA_ "GenSigSwitchedByIgnition" SG_ 64 AB_Crash_Int 0;
BA_ "GenSigSendType" SG_ 64 AB_Crash_Int 4;
BA_ "GenSigActiveRepetitions" SG_ 64 AB_Crash_Int 5;
BA_ "GenSigSwitchedByIgnition" SG_ 64 AB_Lampe 0;
BA_ "GenSigStartValue" SG_ 64 AB_Lampe 1;
BA_ "GenSigSendType" SG_ 64 AB_Lampe 0;
BA_ "GenSigSwitchedByIgnition" SG_ 64 AB_Deaktiviert 0;
BA_ "GenSigSendType" SG_ 64 AB_Deaktiviert 0;
BA_ "GenSigSwitchedByIgnition" SG_ 64 AB_VB_deaktiviert 0;
BA_ "GenSigStartValue" SG_ 64 AB_VB_deaktiviert 1;
BA_ "GenSigSendType" SG_ 64 AB_VB_deaktiviert 0;
BA_ "GenSigSwitchedByIgnition" SG_ 64 AB_Systemfehler 0;
BA_ "GenSigSendType" SG_ 64 AB_Systemfehler 0;
BA_ "GenSigSwitchedByIgnition" SG_ 64 AB_Diagnose 0;
BA_ "GenSigSendType" SG_ 64 AB_Diagnose 0;
BA_ "GenSigSwitchedByIgnition" SG_ 64 AB_Stellgliedtest 0;
BA_ "GenSigSendType" SG_ 64 AB_Stellgliedtest 0;
BA_ "GenSigSwitchedByIgnition" SG_ 64 AB_Erh_Auf_VB 0;
BA_ "GenSigSendType" SG_ 64 AB_Erh_Auf_VB 0;
BA_ "GenSigSwitchedByIgnition" SG_ 64 AB_Gurtwarn_VF 0;
BA_ "GenSigSendType" SG_ 64 AB_Gurtwarn_VF 0;
BA_ "GenSigSwitchedByIgnition" SG_ 64 AB_Gurtwarn_VB 0;
BA_ "GenSigSendType" SG_ 64 AB_Gurtwarn_VB 0;
BA_ "GenSigSwitchedByIgnition" SG_ 64 AB_Anzeige_Fussg 0;
BA_ "GenSigSendType" SG_ 64 AB_Anzeige_Fussg 0;
BA_ "GenSigSwitchedByIgnition" SG_ 64 AB_Texte_AKS 0;
BA_ "GenSigSendType" SG_ 64 AB_Texte_AKS 0;
BA_ "GenSigSwitchedByIgnition" SG_ 64 AB_MKB_gueltig 0;
BA_ "GenSigSendType" SG_ 64 AB_MKB_gueltig 0;
BA_ "GenSigSwitchedByIgnition" SG_ 64 AB_MKB_Anforderung 0;
BA_ "GenSigSendType" SG_ 64 AB_MKB_Anforderung 4;
BA_ "GenSigActiveRepetitions" SG_ 64 AB_MKB_Anforderung 5;
BA_ "GenSigSwitchedByIgnition" SG_ 64 AB_Versorgungsspannung 0;
BA_ "GenSigSendType" SG_ 64 AB_Versorgungsspannung 0;
BA_ "Fehlerwert" SG_ 64 AB_Deaktivierung_HV 7;
BA_ "GenSigSwitchedByIgnition" SG_ 64 AB_Deaktivierung_HV 0;
BA_ "GenSigSendType" SG_ 64 AB_Deaktivierung_HV 4;
BA_ "GenSigActiveRepetitions" SG_ 64 AB_Deaktivierung_HV 5;
BA_ "GenSigSwitchedByIgnition" SG_ 64 AB_EDR_Trigger 0;
BA_ "GenSigSendType" SG_ 64 AB_EDR_Trigger 3;
BA_ "Fehlerwert" SG_ 64 AB_Belegung_VF 1;
BA_ "GenSigSwitchedByIgnition" SG_ 64 AB_Belegung_VF 0;
BA_ "GenSigSendType" SG_ 64 AB_Belegung_VF 0;
BA_ "GenSigSendType" SG_ 64 SC_Masterzeit_Offset 0;
BA_ "GenSigSwitchedByIgnition" SG_ 64 SC_LowSpeedCrashErkannt 0;
BA_ "GenSigSendType" SG_ 64 SC_LowSpeedCrashErkannt 0;
BA_ "GenSigStartValue" SG_ 64 SC_Masterzeit 127;
BA_ "GenSigSendType" SG_ 64 SC_Masterzeit 0;
BA_ "GenSigSwitchedByIgnition" SG_ 2589283757 AT_VALID_TIME 0;
BA_ "GenSigSendType" SG_ 2589283757 AT_VALID_TIME 0;
BA_ "GenSigSwitchedByIgnition" SG_ 2589283607 AWC_01_CRC 0;
BA_ "GenSigFuncType" SG_ 2589283607 AWC_01_CRC 2;
BA_ "GenSigSendType" SG_ 2589283607 AWC_01_CRC 0;
BA_ "GenSigSwitchedByIgnition" SG_ 2589283607 AWC_01_BZ 0;
BA_ "GenSigFuncType" SG_ 2589283607 AWC_01_BZ 1;
BA_ "GenSigSendType" SG_ 2589283607 AWC_01_BZ 0;
BA_ "GenSigSwitchedByIgnition" SG_ 2589283607 AWC_Status_Spgfreiheit 0;
BA_ "GenSigSendType" SG_ 2589283607 AWC_Status_Spgfreiheit 3;
BA_ "Fehlerwert" SG_ 2589283607 AWC_IstSpannung 1023;
BA_ "GenSigSwitchedByIgnition" SG_ 2589283607 AWC_IstSpannung 0;
BA_ "GenSigStartValue" SG_ 2589283607 AWC_IstSpannung 1022;
BA_ "GenSigSendType" SG_ 2589283607 AWC_IstSpannung 0;
BA_ "GenSigSwitchedByIgnition" SG_ 2589283607 AWC_Fehlerstatus 0;
BA_ "GenSigStartValue" SG_ 2589283607 AWC_Fehlerstatus 7;
BA_ "GenSigSendType" SG_ 2589283607 AWC_Fehlerstatus 3;
BA_ "GenSigSwitchedByIgnition" SG_ 2589283607 AWC_IstModus 0;
BA_ "GenSigStartValue" SG_ 2589283607 AWC_IstModus 6;
BA_ "GenSigSendType" SG_ 2589283607 AWC_IstModus 3;
BA_ "Fehlerwert" SG_ 2589283607 AWC_IstStrom 511;
BA_ "GenSigSwitchedByIgnition" SG_ 2589283607 AWC_IstStrom 0;
BA_ "GenSigStartValue" SG_ 2589283607 AWC_IstStrom 510;
BA_ "GenSigSendType" SG_ 2589283607 AWC_IstStrom 0;
BA_ "Fehlerwert" SG_ 2589283607 AWC_MaxLadLeistung 511;
BA_ "GenSigSwitchedByIgnition" SG_ 2589283607 AWC_MaxLadLeistung 0;
BA_ "GenSigStartValue" SG_ 2589283607 AWC_MaxLadLeistung 510;
BA_ "GenSigSendType" SG_ 2589283607 AWC_MaxLadLeistung 0;
BA_ "Fehlerwert" SG_ 2589283618 AWC_Fehler_zMover 1;
BA_ "GenSigSwitchedByIgnition" SG_ 2589283618 AWC_Fehler_zMover 0;
BA_ "GenSigSendType" SG_ 2589283618 AWC_Fehler_zMover 3;
BA_ "Fehlerwert" SG_ 2589283618 AWC_Panel_PositionX 2047;
BA_ "GenSigSwitchedByIgnition" SG_ 2589283618 AWC_Panel_PositionX 0;
BA_ "GenSigStartValue" SG_ 2589283618 AWC_Panel_PositionX 2046;
BA_ "GenSigSendType" SG_ 2589283618 AWC_Panel_PositionX 0;
BA_ "Fehlerwert" SG_ 2589283618 AWC_Panel_PositionY 2047;
BA_ "GenSigSwitchedByIgnition" SG_ 2589283618 AWC_Panel_PositionY 0;
BA_ "GenSigStartValue" SG_ 2589283618 AWC_Panel_PositionY 2046;
BA_ "GenSigSendType" SG_ 2589283618 AWC_Panel_PositionY 0;
BA_ "Fehlerwert" SG_ 2589283618 AWC_Panel_Verdrehwinkel 255;
BA_ "GenSigSwitchedByIgnition" SG_ 2589283618 AWC_Panel_Verdrehwinkel 0;
BA_ "GenSigStartValue" SG_ 2589283618 AWC_Panel_Verdrehwinkel 254;
BA_ "GenSigSendType" SG_ 2589283618 AWC_Panel_Verdrehwinkel 0;
BA_ "GenSigSwitchedByIgnition" SG_ 2589283618 AWC_Positionierhilfe 0;
BA_ "GenSigSendType" SG_ 2589283618 AWC_Positionierhilfe 3;
BA_ "GenSigSwitchedByIgnition" SG_ 2589283618 AWC_Ladeoption_Infrastruktur 0;
BA_ "GenSigStartValue" SG_ 2589283618 AWC_Ladeoption_Infrastruktur 7;
BA_ "GenSigSendType" SG_ 2589283618 AWC_Ladeoption_Infrastruktur 3;
BA_ "GenSigSwitchedByIgnition" SG_ 2589283618 AWC_Spielschutz 0;
BA_ "GenSigSendType" SG_ 2589283618 AWC_Spielschutz 0;
BA_ "Fehlerwert" SG_ 2589283618 AWC_Status 15;
BA_ "GenSigSwitchedByIgnition" SG_ 2589283618 AWC_Status 0;
BA_ "GenSigStartValue" SG_ 2589283618 AWC_Status 14;
BA_ "GenSigSendType" SG_ 2589283618 AWC_Status 3;
BA_ "Fehlerwert" SG_ 2589283618 AWC_Fehler_FOD 1;
BA_ "GenSigSwitchedByIgnition" SG_ 2589283618 AWC_Fehler_FOD 0;
BA_ "GenSigSendType" SG_ 2589283618 AWC_Fehler_FOD 3;
BA_ "Fehlerwert" SG_ 2589283618 AWC_Fehler_Kommunikation 1;
BA_ "GenSigSwitchedByIgnition" SG_ 2589283618 AWC_Fehler_Kommunikation 0;
BA_ "GenSigSendType" SG_ 2589283618 AWC_Fehler_Kommunikation 3;
BA_ "Fehlerwert" SG_ 2589283618 AWC_Fehler_LOP 1;
BA_ "GenSigSwitchedByIgnition" SG_ 2589283618 AWC_Fehler_LOP 0;
BA_ "GenSigSendType" SG_ 2589283618 AWC_Fehler_LOP 3;
BA_ "GenSigSwitchedByIgnition" SG_ 2589283618 AWC_Verzoegerung_FOD 0;
BA_ "GenSigSendType" SG_ 2589283618 AWC_Verzoegerung_FOD 3;
BA_ "GenSigSwitchedByIgnition" SG_ 2589283618 AWC_Verzoegerung_LOP 0;
BA_ "GenSigSendType" SG_ 2589283618 AWC_Verzoegerung_LOP 3;
BA_ "GenSigSwitchedByIgnition" SG_ 2589283618 AWC_Verzoegerung_Temp 0;
BA_ "GenSigSendType" SG_ 2589283618 AWC_Verzoegerung_Temp 3;
BA_ "GenSigSwitchedByIgnition" SG_ 2589283618 AWC_Verzoegerung_zMover 0;
BA_ "GenSigSendType" SG_ 2589283618 AWC_Verzoegerung_zMover 3;
BA_ "GenSigSwitchedByIgnition" SG_ 2589283633 AWC_Abregelung_Temperatur 0;
BA_ "GenSigSendType" SG_ 2589283633 AWC_Abregelung_Temperatur 0;
BA_ "Fehlerwert" SG_ 2589283633 AWC_PlanAntw_Zaehler 15;
BA_ "GenSigSwitchedByIgnition" SG_ 2589283633 AWC_PlanAntw_Zaehler 0;
BA_ "GenSigStartValue" SG_ 2589283633 AWC_PlanAntw_Zaehler 14;
BA_ "GenSigSendType" SG_ 2589283633 AWC_PlanAntw_Zaehler 3;
BA_ "Fehlerwert" SG_ 2589283633 AWC_PlanAntw_Verlustleistung 4095;
BA_ "GenSigSwitchedByIgnition" SG_ 2589283633 AWC_PlanAntw_Verlustleistung 0;
BA_ "GenSigStartValue" SG_ 2589283633 AWC_PlanAntw_Verlustleistung 4094;
BA_ "GenSigSendType" SG_ 2589283633 AWC_PlanAntw_Verlustleistung 0;
BA_ "Fehlerwert" SG_ 2589283633 AWC_Temperatur 255;
BA_ "GenSigSwitchedByIgnition" SG_ 2589283633 AWC_Temperatur 0;
BA_ "GenSigStartValue" SG_ 2589283633 AWC_Temperatur 254;
BA_ "GenSigSendType" SG_ 2589283633 AWC_Temperatur 0;
BA_ "GenSigSwitchedByIgnition" SG_ 2589283685 AWC_CALID_CVN_MUX 0;
BA_ "GenSigSendType" SG_ 2589283685 AWC_CALID_CVN_MUX 0;
BA_ "GenSigSwitchedByIgnition" SG_ 2589283685 AWC_CVN_VLD 0;
BA_ "GenSigSendType" SG_ 2589283685 AWC_CVN_VLD 0;
BA_ "GenSigSwitchedByIgnition" SG_ 2589283685 AWC_CALID_Index_01 0;
BA_ "GenSigStartValue" SG_ 2589283685 AWC_CALID_Index_01 48;
BA_ "GenSigSwitchedByIgnition" SG_ 2589283685 AWC_CALID_Index_05 0;
BA_ "GenSigStartValue" SG_ 2589283685 AWC_CALID_Index_05 48;
BA_ "GenSigSwitchedByIgnition" SG_ 2589283685 AWC_CALID_Index_09 0;
BA_ "GenSigStartValue" SG_ 2589283685 AWC_CALID_Index_09 48;
BA_ "GenSigSwitchedByIgnition" SG_ 2589283685 AWC_CALID_Index_13 0;
BA_ "GenSigStartValue" SG_ 2589283685 AWC_CALID_Index_13 48;
BA_ "GenSigSwitchedByIgnition" SG_ 2589283685 AWC_CALID_Index_02 0;
BA_ "GenSigStartValue" SG_ 2589283685 AWC_CALID_Index_02 48;
BA_ "GenSigSwitchedByIgnition" SG_ 2589283685 AWC_CALID_Index_06 0;
BA_ "GenSigStartValue" SG_ 2589283685 AWC_CALID_Index_06 48;
BA_ "GenSigSwitchedByIgnition" SG_ 2589283685 AWC_CALID_Index_10 0;
BA_ "GenSigStartValue" SG_ 2589283685 AWC_CALID_Index_10 48;
BA_ "GenSigSwitchedByIgnition" SG_ 2589283685 AWC_CALID_Index_14 0;
BA_ "GenSigStartValue" SG_ 2589283685 AWC_CALID_Index_14 48;
BA_ "GenSigSwitchedByIgnition" SG_ 2589283685 AWC_CALID_Index_03 0;
BA_ "GenSigStartValue" SG_ 2589283685 AWC_CALID_Index_03 48;
BA_ "GenSigSwitchedByIgnition" SG_ 2589283685 AWC_CALID_Index_07 0;
BA_ "GenSigStartValue" SG_ 2589283685 AWC_CALID_Index_07 48;
BA_ "GenSigSwitchedByIgnition" SG_ 2589283685 AWC_CALID_Index_11 0;
BA_ "GenSigStartValue" SG_ 2589283685 AWC_CALID_Index_11 48;
BA_ "GenSigSwitchedByIgnition" SG_ 2589283685 AWC_CALID_Index_15 0;
BA_ "GenSigStartValue" SG_ 2589283685 AWC_CALID_Index_15 48;
BA_ "GenSigSwitchedByIgnition" SG_ 2589283685 AWC_CALID_Index_04 0;
BA_ "GenSigStartValue" SG_ 2589283685 AWC_CALID_Index_04 48;
BA_ "GenSigSwitchedByIgnition" SG_ 2589283685 AWC_CALID_Index_08 0;
BA_ "GenSigStartValue" SG_ 2589283685 AWC_CALID_Index_08 48;
BA_ "GenSigSwitchedByIgnition" SG_ 2589283685 AWC_CALID_Index_12 0;
BA_ "GenSigStartValue" SG_ 2589283685 AWC_CALID_Index_12 48;
BA_ "GenSigSwitchedByIgnition" SG_ 2589283685 AWC_CALID_Index_16 0;
BA_ "GenSigStartValue" SG_ 2589283685 AWC_CALID_Index_16 48;
BA_ "GenSigSwitchedByIgnition" SG_ 2589283685 AWC_CVN_Byte_1 0;
BA_ "GenSigSwitchedByIgnition" SG_ 2589283685 AWC_CVN_Byte_2 0;
BA_ "GenSigSwitchedByIgnition" SG_ 2589283685 AWC_CVN_Byte_3 0;
BA_ "GenSigSwitchedByIgnition" SG_ 2589283685 AWC_CVN_Byte_4 0;
BA_ "GenSigSwitchedByIgnition" SG_ 2589283394 AWC_Komponentenfehler_01 0;
BA_ "GenSigStartValue" SG_ 2589283394 AWC_Komponentenfehler_01 2;
BA_ "GenSigSendType" SG_ 2589283394 AWC_Komponentenfehler_01 0;
BA_ "GenSigSwitchedByIgnition" SG_ 2589283394 AWC_Komponentenfehler_02 0;
BA_ "GenSigStartValue" SG_ 2589283394 AWC_Komponentenfehler_02 2;
BA_ "GenSigSendType" SG_ 2589283394 AWC_Komponentenfehler_02 0;
BA_ "GenSigSwitchedByIgnition" SG_ 2589283394 AWC_Komponentenfehler_03 0;
BA_ "GenSigStartValue" SG_ 2589283394 AWC_Komponentenfehler_03 2;
BA_ "GenSigSendType" SG_ 2589283394 AWC_Komponentenfehler_03 0;
BA_ "GenSigSwitchedByIgnition" SG_ 2589283394 AWC_Komponentenfehler_04 0;
BA_ "GenSigStartValue" SG_ 2589283394 AWC_Komponentenfehler_04 2;
BA_ "GenSigSendType" SG_ 2589283394 AWC_Komponentenfehler_04 0;
BA_ "GenSigSwitchedByIgnition" SG_ 2589283394 AWC_Komponentenfehler_05 0;
BA_ "GenSigStartValue" SG_ 2589283394 AWC_Komponentenfehler_05 2;
BA_ "GenSigSendType" SG_ 2589283394 AWC_Komponentenfehler_05 0;
BA_ "GenSigSwitchedByIgnition" SG_ 2589283394 AWC_Komponentenfehler_06 0;
BA_ "GenSigStartValue" SG_ 2589283394 AWC_Komponentenfehler_06 2;
BA_ "GenSigSendType" SG_ 2589283394 AWC_Komponentenfehler_06 0;
BA_ "GenSigSwitchedByIgnition" SG_ 2589283394 AWC_Komponentenfehler_07 0;
BA_ "GenSigStartValue" SG_ 2589283394 AWC_Komponentenfehler_07 2;
BA_ "GenSigSendType" SG_ 2589283394 AWC_Komponentenfehler_07 0;
BA_ "GenSigSwitchedByIgnition" SG_ 2589283394 AWC_Komponentenfehler_08 0;
BA_ "GenSigStartValue" SG_ 2589283394 AWC_Komponentenfehler_08 2;
BA_ "GenSigSendType" SG_ 2589283394 AWC_Komponentenfehler_08 0;
BA_ "GenSigSwitchedByIgnition" SG_ 2589283394 AWC_Komponentenfehler_09 0;
BA_ "GenSigStartValue" SG_ 2589283394 AWC_Komponentenfehler_09 2;
BA_ "GenSigSendType" SG_ 2589283394 AWC_Komponentenfehler_09 0;
BA_ "GenSigSwitchedByIgnition" SG_ 2589283394 AWC_Komponentenfehler_10 0;
BA_ "GenSigStartValue" SG_ 2589283394 AWC_Komponentenfehler_10 2;
BA_ "GenSigSendType" SG_ 2589283394 AWC_Komponentenfehler_10 0;
BA_ "GenSigSwitchedByIgnition" SG_ 2589283394 AWC_Komponentenfehler_11 0;
BA_ "GenSigStartValue" SG_ 2589283394 AWC_Komponentenfehler_11 2;
BA_ "GenSigSendType" SG_ 2589283394 AWC_Komponentenfehler_11 0;
BA_ "GenSigSwitchedByIgnition" SG_ 2589283394 AWC_Komponentenfehler_12 0;
BA_ "GenSigStartValue" SG_ 2589283394 AWC_Komponentenfehler_12 2;
BA_ "GenSigSendType" SG_ 2589283394 AWC_Komponentenfehler_12 0;
BA_ "GenSigSwitchedByIgnition" SG_ 2589283394 AWC_Komponentenfehler_13 0;
BA_ "GenSigStartValue" SG_ 2589283394 AWC_Komponentenfehler_13 2;
BA_ "GenSigSendType" SG_ 2589283394 AWC_Komponentenfehler_13 0;
BA_ "GenSigSwitchedByIgnition" SG_ 2589283394 AWC_Komponentenfehler_14 0;
BA_ "GenSigStartValue" SG_ 2589283394 AWC_Komponentenfehler_14 2;
BA_ "GenSigSendType" SG_ 2589283394 AWC_Komponentenfehler_14 0;
BA_ "GenSigSwitchedByIgnition" SG_ 2589283394 AWC_Komponentenfehler_15 0;
BA_ "GenSigStartValue" SG_ 2589283394 AWC_Komponentenfehler_15 2;
BA_ "GenSigSendType" SG_ 2589283394 AWC_Komponentenfehler_15 0;
BA_ "GenSigSwitchedByIgnition" SG_ 2589283394 AWC_Komponentenfehler_16 0;
BA_ "GenSigStartValue" SG_ 2589283394 AWC_Komponentenfehler_16 2;
BA_ "GenSigSendType" SG_ 2589283394 AWC_Komponentenfehler_16 0;
BA_ "GenSigSwitchedByIgnition" SG_ 2589283394 AWC_Komponentenfehler_17 0;
BA_ "GenSigStartValue" SG_ 2589283394 AWC_Komponentenfehler_17 2;
BA_ "GenSigSendType" SG_ 2589283394 AWC_Komponentenfehler_17 0;
BA_ "GenSigSwitchedByIgnition" SG_ 2589283394 AWC_Komponentenfehler_18 0;
BA_ "GenSigStartValue" SG_ 2589283394 AWC_Komponentenfehler_18 2;
BA_ "GenSigSendType" SG_ 2589283394 AWC_Komponentenfehler_18 0;
BA_ "GenSigSwitchedByIgnition" SG_ 2589283394 AWC_Komponentenfehler_19 0;
BA_ "GenSigStartValue" SG_ 2589283394 AWC_Komponentenfehler_19 2;
BA_ "GenSigSendType" SG_ 2589283394 AWC_Komponentenfehler_19 0;
BA_ "GenSigSwitchedByIgnition" SG_ 2589283394 AWC_Komponentenfehler_20 0;
BA_ "GenSigStartValue" SG_ 2589283394 AWC_Komponentenfehler_20 2;
BA_ "GenSigSendType" SG_ 2589283394 AWC_Komponentenfehler_20 0;
BA_ "GenSigSwitchedByIgnition" SG_ 2589283394 AWC_Komponentenfehler_21 0;
BA_ "GenSigStartValue" SG_ 2589283394 AWC_Komponentenfehler_21 2;
BA_ "GenSigSendType" SG_ 2589283394 AWC_Komponentenfehler_21 0;
BA_ "GenSigSwitchedByIgnition" SG_ 2589283394 AWC_Komponentenfehler_22 0;
BA_ "GenSigStartValue" SG_ 2589283394 AWC_Komponentenfehler_22 2;
BA_ "GenSigSendType" SG_ 2589283394 AWC_Komponentenfehler_22 0;
BA_ "GenSigSwitchedByIgnition" SG_ 2589283394 AWC_Komponentenfehler_23 0;
BA_ "GenSigStartValue" SG_ 2589283394 AWC_Komponentenfehler_23 2;
BA_ "GenSigSendType" SG_ 2589283394 AWC_Komponentenfehler_23 0;
BA_ "GenSigSwitchedByIgnition" SG_ 2589283394 AWC_Komponentenfehler_24 0;
BA_ "GenSigStartValue" SG_ 2589283394 AWC_Komponentenfehler_24 2;
BA_ "GenSigSendType" SG_ 2589283394 AWC_Komponentenfehler_24 0;
BA_ "GenSigSwitchedByIgnition" SG_ 2589283394 AWC_Komponentenfehler_25 0;
BA_ "GenSigStartValue" SG_ 2589283394 AWC_Komponentenfehler_25 2;
BA_ "GenSigSendType" SG_ 2589283394 AWC_Komponentenfehler_25 0;
BA_ "GenSigSwitchedByIgnition" SG_ 2589283394 AWC_Komponentenfehler_26 0;
BA_ "GenSigStartValue" SG_ 2589283394 AWC_Komponentenfehler_26 2;
BA_ "GenSigSendType" SG_ 2589283394 AWC_Komponentenfehler_26 0;
BA_ "GenSigSwitchedByIgnition" SG_ 2589283394 AWC_Komponentenfehler_27 0;
BA_ "GenSigStartValue" SG_ 2589283394 AWC_Komponentenfehler_27 2;
BA_ "GenSigSendType" SG_ 2589283394 AWC_Komponentenfehler_27 0;
BA_ "GenSigSwitchedByIgnition" SG_ 2589283394 AWC_Komponentenfehler_28 0;
BA_ "GenSigStartValue" SG_ 2589283394 AWC_Komponentenfehler_28 2;
BA_ "GenSigSendType" SG_ 2589283394 AWC_Komponentenfehler_28 0;
BA_ "GenSigSwitchedByIgnition" SG_ 2589283394 AWC_Komponentenfehler_29 0;
BA_ "GenSigStartValue" SG_ 2589283394 AWC_Komponentenfehler_29 2;
BA_ "GenSigSendType" SG_ 2589283394 AWC_Komponentenfehler_29 0;
BA_ "GenSigSwitchedByIgnition" SG_ 2589283394 AWC_Komponentenfehler_30 0;
BA_ "GenSigStartValue" SG_ 2589283394 AWC_Komponentenfehler_30 2;
BA_ "GenSigSendType" SG_ 2589283394 AWC_Komponentenfehler_30 0;
BA_ "GenSigSwitchedByIgnition" SG_ 2589283394 AWC_Komponentenfehler_31 0;
BA_ "GenSigStartValue" SG_ 2589283394 AWC_Komponentenfehler_31 2;
BA_ "GenSigSendType" SG_ 2589283394 AWC_Komponentenfehler_31 0;
BA_ "GenSigSwitchedByIgnition" SG_ 2589283394 AWC_Komponentenfehler_VLD 0;
BA_ "GenSigSendType" SG_ 2589283394 AWC_Komponentenfehler_VLD 0;
BA_ "GenSigSwitchedByIgnition" SG_ 2536720384 BAP_AWC_ASG_01_Header 0;
BA_ "GenSigSendType" SG_ 2536720384 BAP_AWC_ASG_01_Header 3;
BA_ "GenSigSwitchedByIgnition" SG_ 2536720385 BAP_AWC_ASG_02_Header 0;
BA_ "GenSigSendType" SG_ 2536720385 BAP_AWC_ASG_02_Header 3;
BA_ "GenSigSwitchedByIgnition" SG_ 2536720400 BAP_AWC_FSG_01_Header 0;
BA_ "GenSigSendType" SG_ 2536720400 BAP_AWC_FSG_01_Header 3;
BA_ "GenSigSwitchedByIgnition" SG_ 2536711424 BAP_BatteryControl_ASG_01_Header 0;
BA_ "GenSigSendType" SG_ 2536711424 BAP_BatteryControl_ASG_01_Header 3;
BA_ "GenSigSwitchedByIgnition" SG_ 2536711425 BAP_BatteryControl_ASG_02_Header 0;
BA_ "GenSigSendType" SG_ 2536711425 BAP_BatteryControl_ASG_02_Header 3;
BA_ "GenSigSwitchedByIgnition" SG_ 2536711426 BAP_BatteryControl_ASG_03_Header 0;
BA_ "GenSigSendType" SG_ 2536711426 BAP_BatteryControl_ASG_03_Header 3;
BA_ "GenSigSwitchedByIgnition" SG_ 2536711427 BAP_BatteryControl_ASG_04_Header 0;
BA_ "GenSigSendType" SG_ 2536711427 BAP_BatteryControl_ASG_04_Header 3;
BA_ "GenSigSwitchedByIgnition" SG_ 2536711428 BAP_BatteryControl_ASG_05_Header 0;
BA_ "GenSigSendType" SG_ 2536711428 BAP_BatteryControl_ASG_05_Header 3;
BA_ "GenSigSwitchedByIgnition" SG_ 2536711429 BAP_BatteryControl_ASG_06_Header 0;
BA_ "GenSigSendType" SG_ 2536711429 BAP_BatteryControl_ASG_06_Header 3;
BA_ "GenSigSwitchedByIgnition" SG_ 2536711440 BAP_BatteryControl_FSG_01_Header 0;
BA_ "GenSigSendType" SG_ 2536711440 BAP_BatteryControl_FSG_01_Header 3;
BA_ "GenSigSwitchedByIgnition" SG_ 2536767264 BAP_Debug_Cmd 0;
BA_ "GenSigSendType" SG_ 2536767264 BAP_Debug_Cmd 3;
BA_ "GenSigSwitchedByIgnition" SG_ 2536767280 BAP_Debug_Data 0;
BA_ "GenSigSendType" SG_ 2536767280 BAP_Debug_Data 3;
BA_ "GenSigSwitchedByIgnition" SG_ 2536706306 BAP_Uhrzeit_ASG_03_Header 0;
BA_ "GenSigSendType" SG_ 2536706306 BAP_Uhrzeit_ASG_03_Header 3;
BA_ "GenSigSwitchedByIgnition" SG_ 2536706310 BAP_Uhrzeit_ASG_07_Header 0;
BA_ "GenSigSendType" SG_ 2536706310 BAP_Uhrzeit_ASG_07_Header 3;
BA_ "GenSigSwitchedByIgnition" SG_ 2536706320 BAP_Uhrzeit_FSG_01_Header 0;
BA_ "GenSigSendType" SG_ 2536706320 BAP_Uhrzeit_FSG_01_Header 3;
BA_ "GenSigSwitchedByIgnition" SG_ 1615 CHA_Kombi_Texte 0;
BA_ "GenSigSendType" SG_ 1615 CHA_Kombi_Texte 3;
BA_ "GenSigSwitchedByIgnition" SG_ 1615 BCM1_HUD_Eyeboxposition 0;
BA_ "GenSigSendType" SG_ 1615 BCM1_HUD_Eyeboxposition 3;
BA_ "GenSigSwitchedByIgnition" SG_ 1615 BCM1_HUD_Eyeboxposition_Status 0;
BA_ "GenSigSendType" SG_ 1615 BCM1_HUD_Eyeboxposition_Status 3;
BA_ "GenSigSwitchedByIgnition" SG_ 1615 BCM1_HUD_Taster 0;
BA_ "GenSigSendType" SG_ 1615 BCM1_HUD_Taster 3;
BA_ "Fehlerwert" SG_ 1615 BCM1_Stellgroesse_Kl_58s 127;
BA_ "GenSigSwitchedByIgnition" SG_ 1615 BCM1_Stellgroesse_Kl_58s 0;
BA_ "GenSigStartValue" SG_ 1615 BCM1_Stellgroesse_Kl_58s 126;
BA_ "GenSigSendType" SG_ 1615 BCM1_Stellgroesse_Kl_58s 3;
BA_ "Fehlerwert" SG_ 1615 BCM1_LDS_Stellung 7;
BA_ "GenSigSwitchedByIgnition" SG_ 1615 BCM1_LDS_Stellung 0;
BA_ "GenSigSendType" SG_ 1615 BCM1_LDS_Stellung 3;
BA_ "GenSigSwitchedByIgnition" SG_ 1615 BCM1_Lichtwarn_Texte 0;
BA_ "GenSigSendType" SG_ 1615 BCM1_Lichtwarn_Texte 3;
BA_ "Fehlerwert" SG_ 1615 CHA_Drehschalter_Modus 15;
BA_ "GenSigSwitchedByIgnition" SG_ 1615 CHA_Drehschalter_Modus 0;
BA_ "GenSigSendType" SG_ 1615 CHA_Drehschalter_Modus 3;
BA_ "GenSigSwitchedByIgnition" SG_ 1615 KRH_Stufe_LED_li 0;
BA_ "GenSigSendType" SG_ 1615 KRH_Stufe_LED_li 3;
BA_ "GenSigSwitchedByIgnition" SG_ 1615 KRH_Stufe_LED_re 0;
BA_ "GenSigSendType" SG_ 1615 KRH_Stufe_LED_re 3;
BA_ "GenSigSwitchedByIgnition" SG_ 1615 BCM1_Spannungs_Anf 0;
BA_ "GenSigSendType" SG_ 1615 BCM1_Spannungs_Anf 3;
BA_ "GenSigSwitchedByIgnition" SG_ 1615 LV_Laserlicht_Texte 0;
BA_ "GenSigSendType" SG_ 1615 LV_Laserlicht_Texte 0;
BA_ "GenSigSwitchedByIgnition" SG_ 1615 BCM1_Hinweis_Lichtnachlauf 0;
BA_ "GenSigSendType" SG_ 1615 BCM1_Hinweis_Lichtnachlauf 3;
BA_ "GenSigSendType" SG_ 1615 LV_LED_Scheinwerfer_li_def 0;
BA_ "GenSigSendType" SG_ 1615 LV_LED_Scheinwerfer_re_def 0;
BA_ "GenSigSwitchedByIgnition" SG_ 1615 BCM1_Status_Ladeanzeige 0;
BA_ "GenSigSendType" SG_ 1615 BCM1_Status_Ladeanzeige 3;
BA_ "GenSigSwitchedByIgnition" SG_ 1626 BCM_Bremsbelag_Sensor 0;
BA_ "GenSigSendType" SG_ 1626 BCM_Bremsbelag_Sensor 3;
BA_ "GenSigSwitchedByIgnition" SG_ 1626 BCM_Bremsfluessigkeit_Sensor 0;
BA_ "GenSigSendType" SG_ 1626 BCM_Bremsfluessigkeit_Sensor 3;
BA_ "GenSigSendType" SG_ 1626 BCM1_Licht_Warn 3;
BA_ "GenSigSwitchedByIgnition" SG_ 1626 BCM_Waschwasser_Sensor 0;
BA_ "GenSigSendType" SG_ 1626 BCM_Waschwasser_Sensor 3;
BA_ "GenSigSwitchedByIgnition" SG_ 1626 BCM_Kuehlmittel_Sensor 0;
BA_ "GenSigSendType" SG_ 1626 BCM_Kuehlmittel_Sensor 3;
BA_ "GenSigSwitchedByIgnition" SG_ 1626 BCM1_Kl_15_HW_erkannt 0;
BA_ "GenSigSendType" SG_ 1626 BCM1_Kl_15_HW_erkannt 3;
BA_ "GenSigSwitchedByIgnition" SG_ 1626 BCM1_Kl_15_Sig_HW_erkannt 0;
BA_ "GenSigSendType" SG_ 1626 BCM1_Kl_15_Sig_HW_erkannt 3;
BA_ "GenSigSwitchedByIgnition" SG_ 1626 BCM_Kuehlmittel_Sensor_02 0;
BA_ "GenSigSendType" SG_ 1626 BCM_Kuehlmittel_Sensor_02 3;
BA_ "GenSigSwitchedByIgnition" SG_ 1626 BCM1_Hinweis_Lichtnachlauf 0;
BA_ "GenSigSendType" SG_ 1626 BCM1_Hinweis_Lichtnachlauf 3;
BA_ "GenSigSendType" SG_ 1626 BCM_Offroad_Taste 3;
BA_ "GenSigSwitchedByIgnition" SG_ 1626 BCM_Hybrid_StSt_Taste_Fehler 0;
BA_ "GenSigSendType" SG_ 1626 BCM_Hybrid_StSt_Taste_Fehler 0;
BA_ "GenSigSwitchedByIgnition" SG_ 1626 BCM_Hybrid_StartStopp_Taste 0;
BA_ "GenSigSendType" SG_ 1626 BCM_Hybrid_StartStopp_Taste 4;
BA_ "GenSigActiveRepetitions" SG_ 1626 BCM_Hybrid_StartStopp_Taste 10;
BA_ "GenSigSwitchedByIgnition" SG_ 1626 BCM1_Warnblink_Taster 0;
BA_ "GenSigSendType" SG_ 1626 BCM1_Warnblink_Taster 4;
BA_ "GenSigActiveRepetitions" SG_ 1626 BCM1_Warnblink_Taster 10;
BA_ "GenSigSwitchedByIgnition" SG_ 1626 BCM1_Valet_Parking_Taster 0;
BA_ "GenSigSendType" SG_ 1626 BCM1_Valet_Parking_Taster 4;
BA_ "GenSigActiveRepetitions" SG_ 1626 BCM1_Valet_Parking_Taster 10;
BA_ "Fehlerwert" SG_ 1626 BCM1_LDS_Stellung 7;
BA_ "GenSigSwitchedByIgnition" SG_ 1626 BCM1_LDS_Stellung 0;
BA_ "GenSigSendType" SG_ 1626 BCM1_LDS_Stellung 3;
BA_ "GenSigSendType" SG_ 1626 BCM1_Rueckfahrlicht_Schalter 3;
BA_ "GenSigSwitchedByIgnition" SG_ 1626 BCM1_MH_Schalter 0;
BA_ "GenSigSendType" SG_ 1626 BCM1_MH_Schalter 3;
BA_ "GenSigSwitchedByIgnition" SG_ 1626 BCM1_MH_WIV_Schalter 0;
BA_ "GenSigSendType" SG_ 1626 BCM1_MH_WIV_Schalter 3;
BA_ "GenSigSendType" SG_ 1626 BCM_Eco_Charisma_Taste 3;
BA_ "GenSigSwitchedByIgnition" SG_ 1626 BCM1_NV_Taster 0;
BA_ "GenSigSendType" SG_ 1626 BCM1_NV_Taster 4;
BA_ "GenSigActiveRepetitions" SG_ 1626 BCM1_NV_Taster 10;
BA_ "GenSigSwitchedByIgnition" SG_ 1626 BCM1_AFS_Lampe 0;
BA_ "GenSigSendType" SG_ 1626 BCM1_AFS_Lampe 3;
BA_ "GenSigSwitchedByIgnition" SG_ 1626 BCM1_Reisemodus_Texte 0;
BA_ "GenSigSendType" SG_ 1626 BCM1_Reisemodus_Texte 3;
BA_ "GenSigSwitchedByIgnition" SG_ 1626 BCM1_Lichtwarn_Texte 0;
BA_ "GenSigSendType" SG_ 1626 BCM1_Lichtwarn_Texte 3;
BA_ "GenSigSendType" SG_ 1626 Gong_TFL_Umschaltung 3;
BA_ "Fehlerwert" SG_ 1626 UGDO_Function_01 7;
BA_ "GenSigSendType" SG_ 1626 UGDO_Function_01 3;
BA_ "GenSigSwitchedByIgnition" SG_ 1626 APS_Tongeber_defekt 0;
BA_ "GenSigSendType" SG_ 1626 APS_Tongeber_defekt 3;
BA_ "GenSigSwitchedByIgnition" SG_ 1626 BCM1_EasyEntry_Status 0;
BA_ "GenSigSendType" SG_ 1626 BCM1_EasyEntry_Status 3;
BA_ "GenSigSwitchedByIgnition" SG_ 1626 BCM1_Lenksaeule_aktiv 0;
BA_ "GenSigSendType" SG_ 1626 BCM1_Lenksaeule_aktiv 3;
BA_ "GenSigSwitchedByIgnition" SG_ 1626 BCM1_St_SW_Diebstahl_links 0;
BA_ "GenSigSendType" SG_ 1626 BCM1_St_SW_Diebstahl_links 3;
BA_ "GenSigSwitchedByIgnition" SG_ 1626 BCM1_St_SW_Diebstahl_rechts 0;
BA_ "GenSigSendType" SG_ 1626 BCM1_St_SW_Diebstahl_rechts 3;
BA_ "GenSigSendType" SG_ 1626 ISP_Dimmung_ASP_02 3;
BA_ "GenSigSwitchedByIgnition" SG_ 1626 BCM1_Schluesselsuche_Anf 0;
BA_ "GenSigSendType" SG_ 1626 BCM1_Schluesselsuche_Anf 0;
BA_ "GenSigSwitchedByIgnition" SG_ 1626 BCM1_Fahrlicht_Hinweis 0;
BA_ "GenSigSendType" SG_ 1626 BCM1_Fahrlicht_Hinweis 3;
BA_ "GenSigSendType" SG_ 1626 BCM_HDF_betaetigt 3;
BA_ "GenSigSwitchedByIgnition" SG_ 401 BMS_01_CRC 0;
BA_ "GenSigFuncType" SG_ 401 BMS_01_CRC 2;
BA_ "GenSigSendType" SG_ 401 BMS_01_CRC 0;
BA_ "GenSigSwitchedByIgnition" SG_ 401 BMS_01_BZ 0;
BA_ "GenSigFuncType" SG_ 401 BMS_01_BZ 1;
BA_ "GenSigSendType" SG_ 401 BMS_01_BZ 0;
BA_ "Fehlerwert" SG_ 401 BMS_IstStrom_02 4095;
BA_ "GenSigSwitchedByIgnition" SG_ 401 BMS_IstStrom_02 0;
BA_ "GenSigStartValue" SG_ 401 BMS_IstStrom_02 4094;
BA_ "GenSigSendType" SG_ 401 BMS_IstStrom_02 0;
BA_ "Fehlerwert" SG_ 401 BMS_IstSpannung 4095;
BA_ "GenSigSwitchedByIgnition" SG_ 401 BMS_IstSpannung 0;
BA_ "GenSigStartValue" SG_ 401 BMS_IstSpannung 4094;
BA_ "GenSigSendType" SG_ 401 BMS_IstSpannung 0;
BA_ "Fehlerwert" SG_ 401 BMS_Spannung_ZwKr 2047;
BA_ "GenSigSwitchedByIgnition" SG_ 401 BMS_Spannung_ZwKr 0;
BA_ "GenSigStartValue" SG_ 401 BMS_Spannung_ZwKr 2046;
BA_ "GenSigSendType" SG_ 401 BMS_Spannung_ZwKr 0;
BA_ "Fehlerwert" SG_ 401 BMS_SOC_HiRes 2047;
BA_ "GenSigSwitchedByIgnition" SG_ 401 BMS_SOC_HiRes 0;
BA_ "GenSigStartValue" SG_ 401 BMS_SOC_HiRes 2046;
BA_ "GenSigSendType" SG_ 401 BMS_SOC_HiRes 0;
BA_ "GenSigSwitchedByIgnition" SG_ 401 BMS_IstStrom_02_OffsetVZ 0;
BA_ "GenSigSendType" SG_ 401 BMS_IstStrom_02_OffsetVZ 0;
BA_ "GenSigSwitchedByIgnition" SG_ 401 BMS_IstStrom_02_Offset 0;
BA_ "GenSigSendType" SG_ 401 BMS_IstStrom_02_Offset 0;
BA_ "GenSigSwitchedByIgnition" SG_ 417 BMS_MaxDyn_LadeStrom_02_Offset 0;
BA_ "GenSigSendType" SG_ 417 BMS_MaxDyn_LadeStrom_02_Offset 0;
BA_ "Fehlerwert" SG_ 417 BMS_MaxDyn_EntladeStrom_02 2047;
BA_ "GenSigSwitchedByIgnition" SG_ 417 BMS_MaxDyn_EntladeStrom_02 0;
BA_ "GenSigStartValue" SG_ 417 BMS_MaxDyn_EntladeStrom_02 2046;
BA_ "GenSigSendType" SG_ 417 BMS_MaxDyn_EntladeStrom_02 0;
BA_ "Fehlerwert" SG_ 417 BMS_MaxDyn_LadeStrom_02 2047;
BA_ "GenSigSwitchedByIgnition" SG_ 417 BMS_MaxDyn_LadeStrom_02 0;
BA_ "GenSigStartValue" SG_ 417 BMS_MaxDyn_LadeStrom_02 2046;
BA_ "GenSigSendType" SG_ 417 BMS_MaxDyn_LadeStrom_02 0;
BA_ "Fehlerwert" SG_ 417 BMS_Min_EntladeSpannung 1023;
BA_ "GenSigSwitchedByIgnition" SG_ 417 BMS_Min_EntladeSpannung 0;
BA_ "GenSigStartValue" SG_ 417 BMS_Min_EntladeSpannung 1022;
BA_ "GenSigSendType" SG_ 417 BMS_Min_EntladeSpannung 0;
BA_ "GenSigSwitchedByIgnition" SG_ 417 BMS_MinDyn_EntladeSpannung 0;
BA_ "GenSigStartValue" SG_ 417 BMS_MinDyn_EntladeSpannung 1023;
BA_ "GenSigSendType" SG_ 417 BMS_MinDyn_EntladeSpannung 0;
BA_ "GenSigSwitchedByIgnition" SG_ 417 BMS_MinDyn_LadeSpannung 0;
BA_ "GenSigStartValue" SG_ 417 BMS_MinDyn_LadeSpannung 1023;
BA_ "GenSigSendType" SG_ 417 BMS_MinDyn_LadeSpannung 0;
BA_ "GenSigSwitchedByIgnition" SG_ 925 BMS_Leerlaufspannung 0;
BA_ "GenSigStartValue" SG_ 925 BMS_Leerlaufspannung 1023;
BA_ "GenSigSendType" SG_ 925 BMS_Leerlaufspannung 0;
BA_ "Fehlerwert" SG_ 925 BMS_Max_LadeSpannung 1023;
BA_ "GenSigSwitchedByIgnition" SG_ 925 BMS_Max_LadeSpannung 0;
BA_ "GenSigStartValue" SG_ 925 BMS_Max_LadeSpannung 1022;
BA_ "GenSigSendType" SG_ 925 BMS_Max_LadeSpannung 0;
BA_ "Fehlerwert" SG_ 925 BMS_MaxPred_EntladeStrom_02 2047;
BA_ "GenSigSwitchedByIgnition" SG_ 925 BMS_MaxPred_EntladeStrom_02 0;
BA_ "GenSigStartValue" SG_ 925 BMS_MaxPred_EntladeStrom_02 2046;
BA_ "GenSigSendType" SG_ 925 BMS_MaxPred_EntladeStrom_02 0;
BA_ "Fehlerwert" SG_ 925 BMS_MaxPred_LadeStrom_02 2047;
BA_ "GenSigSwitchedByIgnition" SG_ 925 BMS_MaxPred_LadeStrom_02 0;
BA_ "GenSigStartValue" SG_ 925 BMS_MaxPred_LadeStrom_02 2046;
BA_ "GenSigSendType" SG_ 925 BMS_MaxPred_LadeStrom_02 0;
BA_ "GenSigSwitchedByIgnition" SG_ 925 BMS_MinPred_EntladeSpannung 0;
BA_ "GenSigStartValue" SG_ 925 BMS_MinPred_EntladeSpannung 1023;
BA_ "GenSigSendType" SG_ 925 BMS_MinPred_EntladeSpannung 0;
BA_ "GenSigSwitchedByIgnition" SG_ 925 BMS_MinPred_LadeSpannung 0;
BA_ "GenSigStartValue" SG_ 925 BMS_MinPred_LadeSpannung 1023;
BA_ "GenSigSendType" SG_ 925 BMS_MinPred_LadeSpannung 0;
BA_ "GenSigSwitchedByIgnition" SG_ 1442 BMS_04_CRC 0;
BA_ "GenSigFuncType" SG_ 1442 BMS_04_CRC 2;
BA_ "GenSigSendType" SG_ 1442 BMS_04_CRC 0;
BA_ "GenSigSwitchedByIgnition" SG_ 1442 BMS_04_BZ 0;
BA_ "GenSigFuncType" SG_ 1442 BMS_04_BZ 1;
BA_ "GenSigSendType" SG_ 1442 BMS_04_BZ 0;
BA_ "GenSigSwitchedByIgnition" SG_ 1442 BMS_Status_ServiceDisconnect 0;
BA_ "GenSigSendType" SG_ 1442 BMS_Status_ServiceDisconnect 0;
BA_ "GenSigSwitchedByIgnition" SG_ 1442 BMS_Status_Spgfreiheit 0;
BA_ "GenSigSendType" SG_ 1442 BMS_Status_Spgfreiheit 0;
BA_ "GenSigSwitchedByIgnition" SG_ 1442 BMS_OBD_Lampe_Anf 0;
BA_ "GenSigSendType" SG_ 1442 BMS_OBD_Lampe_Anf 0;
BA_ "GenSigSwitchedByIgnition" SG_ 1442 BMS_IstModus 0;
BA_ "GenSigStartValue" SG_ 1442 BMS_IstModus 7;
BA_ "GenSigSendType" SG_ 1442 BMS_IstModus 3;
BA_ "GenSigSwitchedByIgnition" SG_ 1442 BMS_Fehlerstatus 0;
BA_ "GenSigStartValue" SG_ 1442 BMS_Fehlerstatus 7;
BA_ "GenSigSendType" SG_ 1442 BMS_Fehlerstatus 3;
BA_ "GenSigSwitchedByIgnition" SG_ 1442 BMS_Kapazitaet_02 0;
BA_ "GenSigStartValue" SG_ 1442 BMS_Kapazitaet_02 2047;
BA_ "GenSigSendType" SG_ 1442 BMS_Kapazitaet_02 0;
BA_ "Fehlerwert" SG_ 1442 BMS_Soll_SOC_HiRes 2047;
BA_ "GenSigSwitchedByIgnition" SG_ 1442 BMS_Soll_SOC_HiRes 0;
BA_ "GenSigStartValue" SG_ 1442 BMS_Soll_SOC_HiRes 2046;
BA_ "GenSigSendType" SG_ 1442 BMS_Soll_SOC_HiRes 3;
BA_ "GenSigSwitchedByIgnition" SG_ 687 BMS_As_Entladezaehler 0;
BA_ "GenSigSendType" SG_ 687 BMS_As_Entladezaehler 0;
BA_ "GenSigSwitchedByIgnition" SG_ 687 BMS_As_Entladezaehler_Ueberlauf 0;
BA_ "GenSigSendType" SG_ 687 BMS_As_Entladezaehler_Ueberlauf 0;
BA_ "GenSigSwitchedByIgnition" SG_ 687 BMS_Rekuperation 0;
BA_ "GenSigSendType" SG_ 687 BMS_Rekuperation 0;
BA_ "GenSigSwitchedByIgnition" SG_ 687 BMS_Rekuperation_Ueberlauf 0;
BA_ "GenSigSendType" SG_ 687 BMS_Rekuperation_Ueberlauf 0;
BA_ "GenSigSwitchedByIgnition" SG_ 687 BMS_Verbrauch 0;
BA_ "GenSigSendType" SG_ 687 BMS_Verbrauch 0;
BA_ "GenSigSwitchedByIgnition" SG_ 687 BMS_Verbrauch_Ueberlauf 0;
BA_ "GenSigSendType" SG_ 687 BMS_Verbrauch_Ueberlauf 0;
BA_ "GenSigSwitchedByIgnition" SG_ 1438 BMS_Temperierung_Anf 0;
BA_ "GenSigStartValue" SG_ 1438 BMS_Temperierung_Anf 3;
BA_ "GenSigSendType" SG_ 1438 BMS_Temperierung_Anf 0;
BA_ "Fehlerwert" SG_ 1438 BMS_Status_Ventil 7;
BA_ "GenSigStartValue" SG_ 1438 BMS_Status_Ventil 6;
BA_ "GenSigSendType" SG_ 1438 BMS_Status_Ventil 0;
BA_ "GenSigSwitchedByIgnition" SG_ 1438 BMS_Temp_Epsilon 0;
BA_ "GenSigSendType" SG_ 1438 BMS_Temp_Epsilon 0;
BA_ "Fehlerwert" SG_ 1438 BMS_Soll_PWM_Pumpe 14;
BA_ "GenSigSwitchedByIgnition" SG_ 1438 BMS_Soll_PWM_Pumpe 0;
BA_ "GenSigStartValue" SG_ 1438 BMS_Soll_PWM_Pumpe 15;
BA_ "GenSigSendType" SG_ 1438 BMS_Soll_PWM_Pumpe 0;
BA_ "Fehlerwert" SG_ 1438 BMS_Temperatur 255;
BA_ "GenSigSwitchedByIgnition" SG_ 1438 BMS_Temperatur 0;
BA_ "GenSigStartValue" SG_ 1438 BMS_Temperatur 254;
BA_ "GenSigSendType" SG_ 1438 BMS_Temperatur 0;
BA_ "Fehlerwert" SG_ 1438 BMS_IstVorlaufTemperatur 255;
BA_ "GenSigSwitchedByIgnition" SG_ 1438 BMS_IstVorlaufTemperatur 0;
BA_ "GenSigStartValue" SG_ 1438 BMS_IstVorlaufTemperatur 254;
BA_ "GenSigSendType" SG_ 1438 BMS_IstVorlaufTemperatur 0;
BA_ "Fehlerwert" SG_ 1438 BMS_Fehler_NTKreis 1;
BA_ "GenSigSendType" SG_ 1438 BMS_Fehler_NTKreis 0;
BA_ "GenSigSwitchedByIgnition" SG_ 1438 BMS_Fehlerstatus_EWP_02 0;
BA_ "GenSigSendType" SG_ 1438 BMS_Fehlerstatus_EWP_02 0;
BA_ "Fehlerwert" SG_ 1438 BMS_SollVolumenstrom 63;
BA_ "GenSigSwitchedByIgnition" SG_ 1438 BMS_SollVolumenstrom 0;
BA_ "GenSigStartValue" SG_ 1438 BMS_SollVolumenstrom 62;
BA_ "GenSigSendType" SG_ 1438 BMS_SollVolumenstrom 0;
BA_ "GenSigSwitchedByIgnition" SG_ 1438 BMS_Batterie_Voko_Anf 0;
BA_ "GenSigSendType" SG_ 1438 BMS_Batterie_Voko_Anf 0;
BA_ "Fehlerwert" SG_ 1438 BMS_SollVorlauftemperatur 255;
BA_ "GenSigSwitchedByIgnition" SG_ 1438 BMS_SollVorlauftemperatur 0;
BA_ "GenSigStartValue" SG_ 1438 BMS_SollVorlauftemperatur 254;
BA_ "GenSigSendType" SG_ 1438 BMS_SollVorlauftemperatur 0;
BA_ "Fehlerwert" SG_ 1438 BMS_IstRuecklaufTemperatur_02 255;
BA_ "GenSigSwitchedByIgnition" SG_ 1438 BMS_IstRuecklaufTemperatur_02 0;
BA_ "GenSigStartValue" SG_ 1438 BMS_IstRuecklaufTemperatur_02 254;
BA_ "GenSigSendType" SG_ 1438 BMS_IstRuecklaufTemperatur_02 0;
BA_ "GenSigFuncType" SG_ 1482 BMS_07_CRC 2;
BA_ "GenSigSendType" SG_ 1482 BMS_07_CRC 0;
BA_ "GenSigFuncType" SG_ 1482 BMS_07_BZ 1;
BA_ "GenSigSendType" SG_ 1482 BMS_07_BZ 0;
BA_ "Fehlerwert" SG_ 1482 BMS_Energieinhalt 2047;
BA_ "GenSigSwitchedByIgnition" SG_ 1482 BMS_Energieinhalt 0;
BA_ "GenSigStartValue" SG_ 1482 BMS_Energieinhalt 2046;
BA_ "GenSigSendType" SG_ 1482 BMS_Energieinhalt 0;
BA_ "GenSigSwitchedByIgnition" SG_ 1482 BMS_Ladevorgang_aktiv 0;
BA_ "GenSigSendType" SG_ 1482 BMS_Ladevorgang_aktiv 0;
BA_ "Fehlerwert" SG_ 1482 BMS_Batteriediagnose 7;
BA_ "GenSigSwitchedByIgnition" SG_ 1482 BMS_Batteriediagnose 0;
BA_ "GenSigStartValue" SG_ 1482 BMS_Batteriediagnose 1;
BA_ "GenSigSendType" SG_ 1482 BMS_Batteriediagnose 3;
BA_ "GenSigSwitchedByIgnition" SG_ 1482 BMS_Freig_max_Performanz 0;
BA_ "GenSigSendType" SG_ 1482 BMS_Freig_max_Performanz 3;
BA_ "GenSigSwitchedByIgnition" SG_ 1482 BMS_Balancing_Aktiv 0;
BA_ "GenSigSendType" SG_ 1482 BMS_Balancing_Aktiv 0;
BA_ "Fehlerwert" SG_ 1482 BMS_MaxEnergieinhalt 2047;
BA_ "GenSigSwitchedByIgnition" SG_ 1482 BMS_MaxEnergieinhalt 0;
BA_ "GenSigStartValue" SG_ 1482 BMS_MaxEnergieinhalt 2046;
BA_ "GenSigSendType" SG_ 1482 BMS_MaxEnergieinhalt 0;
BA_ "GenSigSwitchedByIgnition" SG_ 1482 BMS_Ausgleichsladung_Anf 0;
BA_ "GenSigSendType" SG_ 1482 BMS_Ausgleichsladung_Anf 0;
BA_ "GenSigSendType" SG_ 1482 BMS_Gesamtst_Spgfreiheit 3;
BA_ "Fehlerwert" SG_ 1482 BMS_RIso_Ext 4095;
BA_ "GenSigSwitchedByIgnition" SG_ 1482 BMS_RIso_Ext 0;
BA_ "GenSigStartValue" SG_ 1482 BMS_RIso_Ext 4094;
BA_ "GenSigSendType" SG_ 1482 BMS_RIso_Ext 0;
BA_ "GenSigSwitchedByIgnition" SG_ 1482 BMS_KundenWarnung 0;
BA_ "GenSigSendType" SG_ 1482 BMS_KundenWarnung 3;
BA_ "GenSigSwitchedByIgnition" SG_ 1482 BMS_Fehler_KuehlkreislaufLeckage 0;
BA_ "GenSigSendType" SG_ 1482 BMS_Fehler_KuehlkreislaufLeckage 3;
BA_ "GenSigSwitchedByIgnition" SG_ 2527679979 BMS_HV_Auszeit_Status 0;
BA_ "GenSigSendType" SG_ 2527679979 BMS_HV_Auszeit_Status 0;
BA_ "Fehlerwert" SG_ 2527679979 BMS_HV_Auszeit 511;
BA_ "GenSigSwitchedByIgnition" SG_ 2527679979 BMS_HV_Auszeit 0;
BA_ "GenSigStartValue" SG_ 2527679979 BMS_HV_Auszeit 510;
BA_ "GenSigSendType" SG_ 2527679979 BMS_HV_Auszeit 0;
BA_ "GenSigSwitchedByIgnition" SG_ 2527679979 BMS_Kapazitaet 0;
BA_ "GenSigStartValue" SG_ 2527679979 BMS_Kapazitaet 2047;
BA_ "GenSigSendType" SG_ 2527679979 BMS_Kapazitaet 0;
BA_ "Fehlerwert" SG_ 2527679979 BMS_SOC_Kaltstart 2047;
BA_ "GenSigSwitchedByIgnition" SG_ 2527679979 BMS_SOC_Kaltstart 0;
BA_ "GenSigStartValue" SG_ 2527679979 BMS_SOC_Kaltstart 2046;
BA_ "GenSigSendType" SG_ 2527679979 BMS_SOC_Kaltstart 0;
BA_ "GenSigSwitchedByIgnition" SG_ 2527679979 BMS_max_Grenz_SOC 0;
BA_ "GenSigStartValue" SG_ 2527679979 BMS_max_Grenz_SOC 31;
BA_ "GenSigSendType" SG_ 2527679979 BMS_max_Grenz_SOC 0;
BA_ "GenSigSwitchedByIgnition" SG_ 2527679979 BMS_min_Grenz_SOC 0;
BA_ "GenSigStartValue" SG_ 2527679979 BMS_min_Grenz_SOC 31;
BA_ "GenSigSendType" SG_ 2527679979 BMS_min_Grenz_SOC 0;
BA_REL_ "GenSigTimeoutTime" BU_SG_REL_ AWC SG_ 64 Airbag_01_CRC 500;
BA_REL_ "GenSigTimeoutTime" BU_SG_REL_ BMC_MLBevo SG_ 64 Airbag_01_CRC 500;
BA_REL_ "GenSigTimeoutTime" BU_SG_REL_ BMS_NV SG_ 64 Airbag_01_CRC 500;
BA_REL_ "GenSigTimeoutTime" BU_SG_REL_ DCDC_800V_PAG SG_ 64 Airbag_01_CRC 500;
BA_REL_ "GenSigTimeoutTime" BU_SG_REL_ DCDC_HV SG_ 64 Airbag_01_CRC 500;
BA_REL_ "GenSigTimeoutTime" BU_SG_REL_ DCDC_HV_02 SG_ 64 Airbag_01_CRC 500;
BA_REL_ "GenSigTimeoutTime" BU_SG_REL_ DCDC_IHEV SG_ 64 Airbag_01_CRC 500;
BA_REL_ "GenSigTimeoutTime" BU_SG_REL_ Ladegeraet_2 SG_ 64 Airbag_01_CRC 500;
BA_REL_ "GenSigTimeoutTime" BU_SG_REL_ Ladegeraet_Konzern SG_ 64 Airbag_01_CRC 500;
BA_REL_ "GenSigTimeoutTime" BU_SG_REL_ AWC SG_ 64 Airbag_01_BZ 500;
BA_REL_ "GenSigTimeoutTime" BU_SG_REL_ BMC_MLBevo SG_ 64 Airbag_01_BZ 500;
BA_REL_ "GenSigTimeoutTime" BU_SG_REL_ BMS_NV SG_ 64 Airbag_01_BZ 500;
BA_REL_ "GenSigTimeoutTime" BU_SG_REL_ DCDC_800V_PAG SG_ 64 Airbag_01_BZ 500;
BA_REL_ "GenSigTimeoutTime" BU_SG_REL_ DCDC_HV SG_ 64 Airbag_01_BZ 500;
BA_REL_ "GenSigTimeoutTime" BU_SG_REL_ DCDC_HV_02 SG_ 64 Airbag_01_BZ 500;
BA_REL_ "GenSigTimeoutTime" BU_SG_REL_ DCDC_IHEV SG_ 64 Airbag_01_BZ 500;
BA_REL_ "GenSigTimeoutTime" BU_SG_REL_ Ladegeraet_2 SG_ 64 Airbag_01_BZ 500;
BA_REL_ "GenSigTimeoutTime" BU_SG_REL_ Ladegeraet_Konzern SG_ 64 Airbag_01_BZ 500;
BA_REL_ "GenSigTimeoutTime" BU_SG_REL_ FCU_MLBevo_FCEV SG_ 64 AB_Crash_Int 500;
BA_REL_ "GenSigTimeoutTime" BU_SG_REL_ TME SG_ 64 AB_Crash_Int 500;
BA_REL_ "GenSigTimeoutTime" BU_SG_REL_ TME SG_ 64 AB_Stellgliedtest 500;
BA_REL_ "GenSigTimeoutTime" BU_SG_REL_ AWC SG_ 64 AB_Deaktivierung_HV 500;
BA_REL_ "GenSigTimeoutTime" BU_SG_REL_ BMC_MLBevo SG_ 64 AB_Deaktivierung_HV 500;
BA_REL_ "GenSigTimeoutTime" BU_SG_REL_ BMS_NV SG_ 64 AB_Deaktivierung_HV 500;
BA_REL_ "GenSigTimeoutTime" BU_SG_REL_ DCDC_800V_PAG SG_ 64 AB_Deaktivierung_HV 500;
BA_REL_ "GenSigTimeoutTime" BU_SG_REL_ DCDC_HV SG_ 64 AB_Deaktivierung_HV 500;
BA_REL_ "GenSigTimeoutTime" BU_SG_REL_ DCDC_HV_02 SG_ 64 AB_Deaktivierung_HV 500;
BA_REL_ "GenSigTimeoutTime" BU_SG_REL_ DCDC_IHEV SG_ 64 AB_Deaktivierung_HV 500;
BA_REL_ "GenSigTimeoutTime" BU_SG_REL_ FCU_MLBevo_FCEV SG_ 64 AB_Deaktivierung_HV 500;
BA_REL_ "GenSigTimeoutTime" BU_SG_REL_ Ladegeraet_2 SG_ 64 AB_Deaktivierung_HV 500;
BA_REL_ "GenSigTimeoutTime" BU_SG_REL_ Ladegeraet_Konzern SG_ 64 AB_Deaktivierung_HV 500;
BA_REL_ "GenSigTimeoutTime" BU_SG_REL_ TME SG_ 64 AB_Deaktivierung_HV 500;
BA_REL_ "GenSigTimeoutTime" BU_SG_REL_ Ladegeraet_Konzern SG_ 2589283757 AT_VALID_TIME 5000;
BA_REL_ "GenSigTimeoutTime" BU_SG_REL_ Gateway SG_ 2589283607 AWC_01_CRC 2000;
BA_REL_ "GenSigTimeoutTime" BU_SG_REL_ Gateway_PAG SG_ 2589283607 AWC_01_CRC 2000;
BA_REL_ "GenSigTimeoutTime" BU_SG_REL_ Gateway SG_ 2589283607 AWC_01_BZ 2000;
BA_REL_ "GenSigTimeoutTime" BU_SG_REL_ Gateway_PAG SG_ 2589283607 AWC_01_BZ 2000;
BA_REL_ "GenSigTimeoutTime" BU_SG_REL_ Gateway SG_ 2589283607 AWC_Status_Spgfreiheit 2000;
BA_REL_ "GenSigTimeoutTime" BU_SG_REL_ Gateway_PAG SG_ 2589283607 AWC_Status_Spgfreiheit 2000;
BA_REL_ "GenSigTimeoutTime" BU_SG_REL_ Gateway SG_ 2589283607 AWC_IstSpannung 2000;
BA_REL_ "GenSigTimeoutTime" BU_SG_REL_ Gateway_PAG SG_ 2589283607 AWC_IstSpannung 2000;
BA_REL_ "GenSigTimeoutTime" BU_SG_REL_ Ladegeraet_Konzern SG_ 2589283607 AWC_IstSpannung 2000;
BA_REL_ "GenSigTimeoutTime" BU_SG_REL_ Gateway SG_ 2589283607 AWC_Fehlerstatus 2000;
BA_REL_ "GenSigTimeoutTime" BU_SG_REL_ Gateway_PAG SG_ 2589283607 AWC_Fehlerstatus 2000;
BA_REL_ "GenSigTimeoutTime" BU_SG_REL_ Gateway SG_ 2589283607 AWC_IstModus 2000;
BA_REL_ "GenSigTimeoutTime" BU_SG_REL_ Gateway_PAG SG_ 2589283607 AWC_IstModus 2000;
BA_REL_ "GenSigTimeoutTime" BU_SG_REL_ Ladegeraet_Konzern SG_ 2589283607 AWC_IstModus 2000;
BA_REL_ "GenSigTimeoutTime" BU_SG_REL_ TME SG_ 2589283607 AWC_IstModus 2000;
BA_REL_ "GenSigTimeoutTime" BU_SG_REL_ Ladegeraet_Konzern SG_ 2589283607 AWC_IstStrom 2000;
BA_REL_ "GenSigTimeoutTime" BU_SG_REL_ Ladegeraet_Konzern SG_ 2589283607 AWC_MaxLadLeistung 2000;
BA_REL_ "GenSigTimeoutTime" BU_SG_REL_ Ladegeraet_Konzern SG_ 2589283618 AWC_Fehler_zMover 2000;
BA_REL_ "GenSigTimeoutTime" BU_SG_REL_ Ladegeraet_Konzern SG_ 2589283618 AWC_Ladeoption_Infrastruktur 2000;
BA_REL_ "GenSigTimeoutTime" BU_SG_REL_ Ladegeraet_Konzern SG_ 2589283618 AWC_Spielschutz 2000;
BA_REL_ "GenSigTimeoutTime" BU_SG_REL_ Gateway SG_ 2589283618 AWC_Status 2000;
BA_REL_ "GenSigTimeoutTime" BU_SG_REL_ Ladegeraet_Konzern SG_ 2589283618 AWC_Status 2000;
BA_REL_ "GenSigTimeoutTime" BU_SG_REL_ Ladegeraet_Konzern SG_ 2589283618 AWC_Fehler_FOD 2000;
BA_REL_ "GenSigTimeoutTime" BU_SG_REL_ Ladegeraet_Konzern SG_ 2589283618 AWC_Fehler_Kommunikation 2000;
BA_REL_ "GenSigTimeoutTime" BU_SG_REL_ Ladegeraet_Konzern SG_ 2589283618 AWC_Fehler_LOP 2000;
BA_REL_ "GenSigTimeoutTime" BU_SG_REL_ Ladegeraet_Konzern SG_ 2589283618 AWC_Verzoegerung_FOD 2000;
BA_REL_ "GenSigTimeoutTime" BU_SG_REL_ Ladegeraet_Konzern SG_ 2589283618 AWC_Verzoegerung_LOP 2000;
BA_REL_ "GenSigTimeoutTime" BU_SG_REL_ Ladegeraet_Konzern SG_ 2589283618 AWC_Verzoegerung_Temp 2000;
BA_REL_ "GenSigTimeoutTime" BU_SG_REL_ Ladegeraet_Konzern SG_ 2589283618 AWC_Verzoegerung_zMover 2000;
BA_REL_ "GenSigTimeoutTime" BU_SG_REL_ TME SG_ 2589283633 AWC_Abregelung_Temperatur 5000;
BA_REL_ "GenSigTimeoutTime" BU_SG_REL_ Ladegeraet_Konzern SG_ 2589283633 AWC_PlanAntw_Zaehler 5000;
BA_REL_ "GenSigTimeoutTime" BU_SG_REL_ TME SG_ 2589283633 AWC_PlanAntw_Zaehler 5000;
BA_REL_ "GenSigTimeoutTime" BU_SG_REL_ Ladegeraet_Konzern SG_ 2589283633 AWC_PlanAntw_Verlustleistung 5000;
BA_REL_ "GenSigTimeoutTime" BU_SG_REL_ TME SG_ 2589283633 AWC_PlanAntw_Verlustleistung 5000;
BA_REL_ "GenSigTimeoutTime" BU_SG_REL_ TME SG_ 2589283633 AWC_Temperatur 5000;
BA_REL_ "GenSigTimeoutTime" BU_SG_REL_ BMC_MLBevo SG_ 2589283685 AWC_CALID_CVN_MUX 5000;
BA_REL_ "GenSigTimeoutTime" BU_SG_REL_ BMC_MLBevo SG_ 2589283685 AWC_CVN_VLD 5000;
BA_REL_ "GenSigTimeoutTime" BU_SG_REL_ BMC_MLBevo SG_ 2589283685 AWC_CALID_Index_01 5000;
BA_REL_ "GenSigTimeoutTime" BU_SG_REL_ BMC_MLBevo SG_ 2589283685 AWC_CALID_Index_05 5000;
BA_REL_ "GenSigTimeoutTime" BU_SG_REL_ BMC_MLBevo SG_ 2589283685 AWC_CALID_Index_09 5000;
BA_REL_ "GenSigTimeoutTime" BU_SG_REL_ BMC_MLBevo SG_ 2589283685 AWC_CALID_Index_13 5000;
BA_REL_ "GenSigTimeoutTime" BU_SG_REL_ BMC_MLBevo SG_ 2589283685 AWC_CALID_Index_02 5000;
BA_REL_ "GenSigTimeoutTime" BU_SG_REL_ BMC_MLBevo SG_ 2589283685 AWC_CALID_Index_06 5000;
BA_REL_ "GenSigTimeoutTime" BU_SG_REL_ BMC_MLBevo SG_ 2589283685 AWC_CALID_Index_10 5000;
BA_REL_ "GenSigTimeoutTime" BU_SG_REL_ BMC_MLBevo SG_ 2589283685 AWC_CALID_Index_14 5000;
BA_REL_ "GenSigTimeoutTime" BU_SG_REL_ BMC_MLBevo SG_ 2589283685 AWC_CALID_Index_03 5000;
BA_REL_ "GenSigTimeoutTime" BU_SG_REL_ BMC_MLBevo SG_ 2589283685 AWC_CALID_Index_07 5000;
BA_REL_ "GenSigTimeoutTime" BU_SG_REL_ BMC_MLBevo SG_ 2589283685 AWC_CALID_Index_11 5000;
BA_REL_ "GenSigTimeoutTime" BU_SG_REL_ BMC_MLBevo SG_ 2589283685 AWC_CALID_Index_15 5000;
BA_REL_ "GenSigTimeoutTime" BU_SG_REL_ BMC_MLBevo SG_ 2589283685 AWC_CALID_Index_04 5000;
BA_REL_ "GenSigTimeoutTime" BU_SG_REL_ BMC_MLBevo SG_ 2589283685 AWC_CALID_Index_08 5000;
BA_REL_ "GenSigTimeoutTime" BU_SG_REL_ BMC_MLBevo SG_ 2589283685 AWC_CALID_Index_12 5000;
BA_REL_ "GenSigTimeoutTime" BU_SG_REL_ BMC_MLBevo SG_ 2589283685 AWC_CALID_Index_16 5000;
BA_REL_ "GenSigTimeoutTime" BU_SG_REL_ BMC_MLBevo SG_ 2589283685 AWC_CVN_Byte_1 5000;
BA_REL_ "GenSigTimeoutTime" BU_SG_REL_ BMC_MLBevo SG_ 2589283685 AWC_CVN_Byte_2 5000;
BA_REL_ "GenSigTimeoutTime" BU_SG_REL_ BMC_MLBevo SG_ 2589283685 AWC_CVN_Byte_3 5000;
BA_REL_ "GenSigTimeoutTime" BU_SG_REL_ BMC_MLBevo SG_ 2589283685 AWC_CVN_Byte_4 5000;
BA_REL_ "GenSigTimeoutTime" BU_SG_REL_ BMC_MLBevo SG_ 2589283394 AWC_Komponentenfehler_01 5000;
BA_REL_ "GenSigTimeoutTime" BU_SG_REL_ BMC_MLBevo SG_ 2589283394 AWC_Komponentenfehler_02 5000;
BA_REL_ "GenSigTimeoutTime" BU_SG_REL_ BMC_MLBevo SG_ 2589283394 AWC_Komponentenfehler_03 5000;
BA_REL_ "GenSigTimeoutTime" BU_SG_REL_ BMC_MLBevo SG_ 2589283394 AWC_Komponentenfehler_04 5000;
BA_REL_ "GenSigTimeoutTime" BU_SG_REL_ BMC_MLBevo SG_ 2589283394 AWC_Komponentenfehler_05 5000;
BA_REL_ "GenSigTimeoutTime" BU_SG_REL_ BMC_MLBevo SG_ 2589283394 AWC_Komponentenfehler_06 5000;
BA_REL_ "GenSigTimeoutTime" BU_SG_REL_ BMC_MLBevo SG_ 2589283394 AWC_Komponentenfehler_07 5000;
BA_REL_ "GenSigTimeoutTime" BU_SG_REL_ BMC_MLBevo SG_ 2589283394 AWC_Komponentenfehler_08 5000;
BA_REL_ "GenSigTimeoutTime" BU_SG_REL_ BMC_MLBevo SG_ 2589283394 AWC_Komponentenfehler_09 5000;
BA_REL_ "GenSigTimeoutTime" BU_SG_REL_ BMC_MLBevo SG_ 2589283394 AWC_Komponentenfehler_10 5000;
BA_REL_ "GenSigTimeoutTime" BU_SG_REL_ BMC_MLBevo SG_ 2589283394 AWC_Komponentenfehler_11 5000;
BA_REL_ "GenSigTimeoutTime" BU_SG_REL_ BMC_MLBevo SG_ 2589283394 AWC_Komponentenfehler_12 5000;
BA_REL_ "GenSigTimeoutTime" BU_SG_REL_ BMC_MLBevo SG_ 2589283394 AWC_Komponentenfehler_13 5000;
BA_REL_ "GenSigTimeoutTime" BU_SG_REL_ BMC_MLBevo SG_ 2589283394 AWC_Komponentenfehler_14 5000;
BA_REL_ "GenSigTimeoutTime" BU_SG_REL_ BMC_MLBevo SG_ 2589283394 AWC_Komponentenfehler_15 5000;
BA_REL_ "GenSigTimeoutTime" BU_SG_REL_ BMC_MLBevo SG_ 2589283394 AWC_Komponentenfehler_16 5000;
BA_REL_ "GenSigTimeoutTime" BU_SG_REL_ BMC_MLBevo SG_ 2589283394 AWC_Komponentenfehler_17 5000;
BA_REL_ "GenSigTimeoutTime" BU_SG_REL_ BMC_MLBevo SG_ 2589283394 AWC_Komponentenfehler_18 5000;
BA_REL_ "GenSigTimeoutTime" BU_SG_REL_ BMC_MLBevo SG_ 2589283394 AWC_Komponentenfehler_19 5000;
BA_REL_ "GenSigTimeoutTime" BU_SG_REL_ BMC_MLBevo SG_ 2589283394 AWC_Komponentenfehler_20 5000;
BA_REL_ "GenSigTimeoutTime" BU_SG_REL_ BMC_MLBevo SG_ 2589283394 AWC_Komponentenfehler_21 5000;
BA_REL_ "GenSigTimeoutTime" BU_SG_REL_ BMC_MLBevo SG_ 2589283394 AWC_Komponentenfehler_22 5000;
BA_REL_ "GenSigTimeoutTime" BU_SG_REL_ BMC_MLBevo SG_ 2589283394 AWC_Komponentenfehler_23 5000;
BA_REL_ "GenSigTimeoutTime" BU_SG_REL_ BMC_MLBevo SG_ 2589283394 AWC_Komponentenfehler_24 5000;
BA_REL_ "GenSigTimeoutTime" BU_SG_REL_ BMC_MLBevo SG_ 2589283394 AWC_Komponentenfehler_25 5000;
BA_REL_ "GenSigTimeoutTime" BU_SG_REL_ BMC_MLBevo SG_ 2589283394 AWC_Komponentenfehler_26 5000;
BA_REL_ "GenSigTimeoutTime" BU_SG_REL_ BMC_MLBevo SG_ 2589283394 AWC_Komponentenfehler_27 5000;
BA_REL_ "GenSigTimeoutTime" BU_SG_REL_ BMC_MLBevo SG_ 2589283394 AWC_Komponentenfehler_28 5000;
BA_REL_ "GenSigTimeoutTime" BU_SG_REL_ BMC_MLBevo SG_ 2589283394 AWC_Komponentenfehler_29 5000;
BA_REL_ "GenSigTimeoutTime" BU_SG_REL_ BMC_MLBevo SG_ 2589283394 AWC_Komponentenfehler_30 5000;
BA_REL_ "GenSigTimeoutTime" BU_SG_REL_ BMC_MLBevo SG_ 2589283394 AWC_Komponentenfehler_31 5000;
BA_REL_ "GenSigTimeoutTime" BU_SG_REL_ BMC_MLBevo SG_ 2589283394 AWC_Komponentenfehler_VLD 5000;
BA_REL_ "GenSigTimeoutTime" BU_SG_REL_ Ladegeraet_Konzern SG_ 1615 BCM1_Status_Ladeanzeige 5000;
BA_REL_ "GenSigTimeoutTime" BU_SG_REL_ TME SG_ 1626 BCM_Kuehlmittel_Sensor 5000;
BA_REL_ "GenSigTimeoutTime" BU_SG_REL_ TME SG_ 1626 BCM_Kuehlmittel_Sensor_02 5000;
BA_REL_ "GenSigTimeoutTime" BU_SG_REL_ Gateway SG_ 401 BMS_01_CRC 500;
BA_REL_ "GenSigTimeoutTime" BU_SG_REL_ Gateway_PAG SG_ 401 BMS_01_CRC 500;
BA_REL_ "GenSigTimeoutTime" BU_SG_REL_ Gateway SG_ 401 BMS_01_BZ 500;
BA_REL_ "GenSigTimeoutTime" BU_SG_REL_ Gateway_PAG SG_ 401 BMS_01_BZ 500;
BA_REL_ "GenSigTimeoutTime" BU_SG_REL_ Gateway SG_ 401 BMS_IstStrom_02 500;
BA_REL_ "GenSigTimeoutTime" BU_SG_REL_ Gateway_PAG SG_ 401 BMS_IstStrom_02 500;
BA_REL_ "GenSigTimeoutTime" BU_SG_REL_ Ladegeraet_Konzern SG_ 401 BMS_IstStrom_02 500;
BA_REL_ "GenSigTimeoutTime" BU_SG_REL_ LE1 SG_ 401 BMS_IstStrom_02 500;
BA_REL_ "GenSigTimeoutTime" BU_SG_REL_ LE2 SG_ 401 BMS_IstStrom_02 500;
BA_REL_ "GenSigTimeoutTime" BU_SG_REL_ LE2_3_MLBevo_LB SG_ 401 BMS_IstStrom_02 500;
BA_REL_ "GenSigTimeoutTime" BU_SG_REL_ TME SG_ 401 BMS_IstStrom_02 500;
BA_REL_ "GenSigTimeoutTime" BU_SG_REL_ AWC SG_ 401 BMS_IstSpannung 500;
BA_REL_ "GenSigTimeoutTime" BU_SG_REL_ Gateway SG_ 401 BMS_IstSpannung 500;
BA_REL_ "GenSigTimeoutTime" BU_SG_REL_ Gateway_PAG SG_ 401 BMS_IstSpannung 500;
BA_REL_ "GenSigTimeoutTime" BU_SG_REL_ Ladegeraet_2 SG_ 401 BMS_IstSpannung 500;
BA_REL_ "GenSigTimeoutTime" BU_SG_REL_ Ladegeraet_Konzern SG_ 401 BMS_IstSpannung 500;
BA_REL_ "GenSigTimeoutTime" BU_SG_REL_ LE1 SG_ 401 BMS_IstSpannung 500;
BA_REL_ "GenSigTimeoutTime" BU_SG_REL_ LE2 SG_ 401 BMS_IstSpannung 500;
BA_REL_ "GenSigTimeoutTime" BU_SG_REL_ LE2_3_MLBevo_LB SG_ 401 BMS_IstSpannung 500;
BA_REL_ "GenSigTimeoutTime" BU_SG_REL_ TME SG_ 401 BMS_IstSpannung 500;
BA_REL_ "GenSigTimeoutTime" BU_SG_REL_ Gateway SG_ 401 BMS_Spannung_ZwKr 500;
BA_REL_ "GenSigTimeoutTime" BU_SG_REL_ Gateway_PAG SG_ 401 BMS_Spannung_ZwKr 500;
BA_REL_ "GenSigTimeoutTime" BU_SG_REL_ LE1 SG_ 401 BMS_Spannung_ZwKr 500;
BA_REL_ "GenSigTimeoutTime" BU_SG_REL_ LE2 SG_ 401 BMS_Spannung_ZwKr 500;
BA_REL_ "GenSigTimeoutTime" BU_SG_REL_ LE2_3_MLBevo_LB SG_ 401 BMS_Spannung_ZwKr 500;
BA_REL_ "GenSigTimeoutTime" BU_SG_REL_ TME SG_ 401 BMS_Spannung_ZwKr 500;
BA_REL_ "GenSigTimeoutTime" BU_SG_REL_ Gateway SG_ 401 BMS_SOC_HiRes 500;
BA_REL_ "GenSigTimeoutTime" BU_SG_REL_ Gateway_PAG SG_ 401 BMS_SOC_HiRes 500;
BA_REL_ "GenSigTimeoutTime" BU_SG_REL_ Ladegeraet_Konzern SG_ 401 BMS_SOC_HiRes 500;
BA_REL_ "GenSigTimeoutTime" BU_SG_REL_ TME SG_ 401 BMS_SOC_HiRes 500;
BA_REL_ "GenSigTimeoutTime" BU_SG_REL_ Gateway SG_ 401 BMS_IstStrom_02_OffsetVZ 500;
BA_REL_ "GenSigTimeoutTime" BU_SG_REL_ Gateway_PAG SG_ 401 BMS_IstStrom_02_OffsetVZ 500;
BA_REL_ "GenSigTimeoutTime" BU_SG_REL_ Ladegeraet_Konzern SG_ 401 BMS_IstStrom_02_OffsetVZ 500;
BA_REL_ "GenSigTimeoutTime" BU_SG_REL_ Gateway SG_ 401 BMS_IstStrom_02_Offset 500;
BA_REL_ "GenSigTimeoutTime" BU_SG_REL_ Gateway_PAG SG_ 401 BMS_IstStrom_02_Offset 500;
BA_REL_ "GenSigTimeoutTime" BU_SG_REL_ Ladegeraet_Konzern SG_ 401 BMS_IstStrom_02_Offset 500;
BA_REL_ "GenSigTimeoutTime" BU_SG_REL_ Ladegeraet_Konzern SG_ 417 BMS_MaxDyn_LadeStrom_02_Offset 1000;
BA_REL_ "GenSigTimeoutTime" BU_SG_REL_ FCU_MLBevo_FCEV SG_ 417 BMS_MaxDyn_EntladeStrom_02 1000;
BA_REL_ "GenSigTimeoutTime" BU_SG_REL_ Gateway SG_ 417 BMS_MaxDyn_EntladeStrom_02 1000;
BA_REL_ "GenSigTimeoutTime" BU_SG_REL_ Gateway_PAG SG_ 417 BMS_MaxDyn_EntladeStrom_02 1000;
BA_REL_ "GenSigTimeoutTime" BU_SG_REL_ LE2_3_MLBevo_LB SG_ 417 BMS_MaxDyn_EntladeStrom_02 1000;
BA_REL_ "GenSigTimeoutTime" BU_SG_REL_ FCU_MLBevo_FCEV SG_ 417 BMS_MaxDyn_LadeStrom_02 1000;
BA_REL_ "GenSigTimeoutTime" BU_SG_REL_ Gateway SG_ 417 BMS_MaxDyn_LadeStrom_02 1000;
BA_REL_ "GenSigTimeoutTime" BU_SG_REL_ Gateway_PAG SG_ 417 BMS_MaxDyn_LadeStrom_02 1000;
BA_REL_ "GenSigTimeoutTime" BU_SG_REL_ Ladegeraet_Konzern SG_ 417 BMS_MaxDyn_LadeStrom_02 1000;
BA_REL_ "GenSigTimeoutTime" BU_SG_REL_ LE2_3_MLBevo_LB SG_ 417 BMS_MaxDyn_LadeStrom_02 1000;
BA_REL_ "GenSigTimeoutTime" BU_SG_REL_ FCU_MLBevo_FCEV SG_ 417 BMS_Min_EntladeSpannung 1000;
BA_REL_ "GenSigTimeoutTime" BU_SG_REL_ Gateway SG_ 417 BMS_Min_EntladeSpannung 1000;
BA_REL_ "GenSigTimeoutTime" BU_SG_REL_ Gateway_PAG SG_ 417 BMS_Min_EntladeSpannung 1000;
BA_REL_ "GenSigTimeoutTime" BU_SG_REL_ Ladegeraet_Konzern SG_ 417 BMS_Min_EntladeSpannung 1000;
BA_REL_ "GenSigTimeoutTime" BU_SG_REL_ LE2_3_MLBevo_LB SG_ 417 BMS_Min_EntladeSpannung 1000;
BA_REL_ "GenSigTimeoutTime" BU_SG_REL_ FCU_MLBevo_FCEV SG_ 417 BMS_MinDyn_EntladeSpannung 1000;
BA_REL_ "GenSigTimeoutTime" BU_SG_REL_ LE2_3_MLBevo_LB SG_ 417 BMS_MinDyn_EntladeSpannung 1000;
BA_REL_ "GenSigTimeoutTime" BU_SG_REL_ FCU_MLBevo_FCEV SG_ 417 BMS_MinDyn_LadeSpannung 1000;
BA_REL_ "GenSigTimeoutTime" BU_SG_REL_ LE2_3_MLBevo_LB SG_ 417 BMS_MinDyn_LadeSpannung 1000;
BA_REL_ "GenSigTimeoutTime" BU_SG_REL_ Gateway SG_ 925 BMS_Leerlaufspannung 1000;
BA_REL_ "GenSigTimeoutTime" BU_SG_REL_ Gateway_PAG SG_ 925 BMS_Leerlaufspannung 1000;
BA_REL_ "GenSigTimeoutTime" BU_SG_REL_ AWC SG_ 925 BMS_Max_LadeSpannung 1000;
BA_REL_ "GenSigTimeoutTime" BU_SG_REL_ FCU_MLBevo_FCEV SG_ 925 BMS_Max_LadeSpannung 1000;
BA_REL_ "GenSigTimeoutTime" BU_SG_REL_ Gateway SG_ 925 BMS_Max_LadeSpannung 1000;
BA_REL_ "GenSigTimeoutTime" BU_SG_REL_ Gateway_PAG SG_ 925 BMS_Max_LadeSpannung 1000;
BA_REL_ "GenSigTimeoutTime" BU_SG_REL_ Ladegeraet_2 SG_ 925 BMS_Max_LadeSpannung 1000;
BA_REL_ "GenSigTimeoutTime" BU_SG_REL_ Ladegeraet_Konzern SG_ 925 BMS_Max_LadeSpannung 1000;
BA_REL_ "GenSigTimeoutTime" BU_SG_REL_ LE2_3_MLBevo_LB SG_ 925 BMS_Max_LadeSpannung 1000;
BA_REL_ "GenSigTimeoutTime" BU_SG_REL_ LE2_3_MLBevo_LB SG_ 925 BMS_MaxPred_EntladeStrom_02 1000;
BA_REL_ "GenSigTimeoutTime" BU_SG_REL_ Ladegeraet_Konzern SG_ 925 BMS_MaxPred_LadeStrom_02 1000;
BA_REL_ "GenSigTimeoutTime" BU_SG_REL_ LE2_3_MLBevo_LB SG_ 925 BMS_MaxPred_LadeStrom_02 1000;
BA_REL_ "GenSigTimeoutTime" BU_SG_REL_ Ladegeraet_Konzern SG_ 925 BMS_MinPred_EntladeSpannung 1000;
BA_REL_ "GenSigTimeoutTime" BU_SG_REL_ LE2_3_MLBevo_LB SG_ 925 BMS_MinPred_EntladeSpannung 1000;
BA_REL_ "GenSigTimeoutTime" BU_SG_REL_ LE2_3_MLBevo_LB SG_ 925 BMS_MinPred_LadeSpannung 1000;
BA_REL_ "GenSigTimeoutTime" BU_SG_REL_ Gateway SG_ 1442 BMS_04_CRC 5000;
BA_REL_ "GenSigTimeoutTime" BU_SG_REL_ Gateway_PAG SG_ 1442 BMS_04_CRC 5000;
BA_REL_ "GenSigTimeoutTime" BU_SG_REL_ Gateway SG_ 1442 BMS_04_BZ 5000;
BA_REL_ "GenSigTimeoutTime" BU_SG_REL_ Gateway_PAG SG_ 1442 BMS_04_BZ 5000;
BA_REL_ "GenSigTimeoutTime" BU_SG_REL_ DCDC_800V_PAG SG_ 1442 BMS_Status_ServiceDisconnect 5000;
BA_REL_ "GenSigTimeoutTime" BU_SG_REL_ DCDC_HV SG_ 1442 BMS_Status_ServiceDisconnect 5000;
BA_REL_ "GenSigTimeoutTime" BU_SG_REL_ Gateway SG_ 1442 BMS_Status_Spgfreiheit 5000;
BA_REL_ "GenSigTimeoutTime" BU_SG_REL_ Gateway_PAG SG_ 1442 BMS_Status_Spgfreiheit 5000;
BA_REL_ "GenSigTimeoutTime" BU_SG_REL_ AWC SG_ 1442 BMS_IstModus 5000;
BA_REL_ "GenSigTimeoutTime" BU_SG_REL_ Gateway SG_ 1442 BMS_IstModus 5000;
BA_REL_ "GenSigTimeoutTime" BU_SG_REL_ Gateway_PAG SG_ 1442 BMS_IstModus 5000;
BA_REL_ "GenSigTimeoutTime" BU_SG_REL_ Ladegeraet_Konzern SG_ 1442 BMS_IstModus 5000;
BA_REL_ "GenSigTimeoutTime" BU_SG_REL_ LE1 SG_ 1442 BMS_IstModus 5000;
BA_REL_ "GenSigTimeoutTime" BU_SG_REL_ LE2 SG_ 1442 BMS_IstModus 5000;
BA_REL_ "GenSigTimeoutTime" BU_SG_REL_ LE2_3_MLBevo_LB SG_ 1442 BMS_IstModus 5000;
BA_REL_ "GenSigTimeoutTime" BU_SG_REL_ TME SG_ 1442 BMS_IstModus 5000;
BA_REL_ "GenSigTimeoutTime" BU_SG_REL_ AWC SG_ 1442 BMS_Fehlerstatus 5000;
BA_REL_ "GenSigTimeoutTime" BU_SG_REL_ DCDC_800V_PAG SG_ 1442 BMS_Fehlerstatus 5000;
BA_REL_ "GenSigTimeoutTime" BU_SG_REL_ DCDC_HV SG_ 1442 BMS_Fehlerstatus 5000;
BA_REL_ "GenSigTimeoutTime" BU_SG_REL_ Gateway SG_ 1442 BMS_Fehlerstatus 5000;
BA_REL_ "GenSigTimeoutTime" BU_SG_REL_ Gateway_PAG SG_ 1442 BMS_Fehlerstatus 5000;
BA_REL_ "GenSigTimeoutTime" BU_SG_REL_ Ladegeraet_Konzern SG_ 1442 BMS_Fehlerstatus 5000;
BA_REL_ "GenSigTimeoutTime" BU_SG_REL_ Ladegeraet_Konzern SG_ 1442 BMS_Kapazitaet_02 5000;
BA_REL_ "GenSigTimeoutTime" BU_SG_REL_ Gateway SG_ 687 BMS_As_Entladezaehler 500;
BA_REL_ "GenSigTimeoutTime" BU_SG_REL_ Gateway_PAG SG_ 687 BMS_As_Entladezaehler 500;
BA_REL_ "GenSigTimeoutTime" BU_SG_REL_ Gateway SG_ 687 BMS_As_Entladezaehler_Ueberlauf 500;
BA_REL_ "GenSigTimeoutTime" BU_SG_REL_ Gateway_PAG SG_ 687 BMS_As_Entladezaehler_Ueberlauf 500;
BA_REL_ "GenSigTimeoutTime" BU_SG_REL_ Gateway SG_ 687 BMS_Rekuperation 500;
BA_REL_ "GenSigTimeoutTime" BU_SG_REL_ Gateway_PAG SG_ 687 BMS_Rekuperation 500;
BA_REL_ "GenSigTimeoutTime" BU_SG_REL_ Gateway SG_ 687 BMS_Rekuperation_Ueberlauf 500;
BA_REL_ "GenSigTimeoutTime" BU_SG_REL_ Gateway_PAG SG_ 687 BMS_Rekuperation_Ueberlauf 500;
BA_REL_ "GenSigTimeoutTime" BU_SG_REL_ Gateway SG_ 687 BMS_Verbrauch 500;
BA_REL_ "GenSigTimeoutTime" BU_SG_REL_ Gateway_PAG SG_ 687 BMS_Verbrauch 500;
BA_REL_ "GenSigTimeoutTime" BU_SG_REL_ Gateway SG_ 687 BMS_Verbrauch_Ueberlauf 500;
BA_REL_ "GenSigTimeoutTime" BU_SG_REL_ Gateway_PAG SG_ 687 BMS_Verbrauch_Ueberlauf 500;
BA_REL_ "GenSigTimeoutTime" BU_SG_REL_ Gateway SG_ 1438 BMS_Temperierung_Anf 5000;
BA_REL_ "GenSigTimeoutTime" BU_SG_REL_ Gateway_PAG SG_ 1438 BMS_Temperierung_Anf 5000;
BA_REL_ "GenSigTimeoutTime" BU_SG_REL_ TME SG_ 1438 BMS_Temperierung_Anf 5000;
BA_REL_ "GenSigTimeoutTime" BU_SG_REL_ TME SG_ 1438 BMS_Temp_Epsilon 5000;
BA_REL_ "GenSigTimeoutTime" BU_SG_REL_ TME SG_ 1438 BMS_Soll_PWM_Pumpe 5000;
BA_REL_ "GenSigTimeoutTime" BU_SG_REL_ Gateway SG_ 1438 BMS_Temperatur 5000;
BA_REL_ "GenSigTimeoutTime" BU_SG_REL_ Gateway_PAG SG_ 1438 BMS_Temperatur 5000;
BA_REL_ "GenSigTimeoutTime" BU_SG_REL_ Ladegeraet_Konzern SG_ 1438 BMS_Temperatur 5000;
BA_REL_ "GenSigTimeoutTime" BU_SG_REL_ TME SG_ 1438 BMS_Temperatur 5000;
BA_REL_ "GenSigTimeoutTime" BU_SG_REL_ TME SG_ 1438 BMS_IstVorlaufTemperatur 5000;
BA_REL_ "GenSigTimeoutTime" BU_SG_REL_ TME SG_ 1438 BMS_Fehlerstatus_EWP_02 5000;
BA_REL_ "GenSigTimeoutTime" BU_SG_REL_ TME SG_ 1438 BMS_SollVolumenstrom 5000;
BA_REL_ "GenSigTimeoutTime" BU_SG_REL_ Ladegeraet_Konzern SG_ 1438 BMS_Batterie_Voko_Anf 5000;
BA_REL_ "GenSigTimeoutTime" BU_SG_REL_ TME SG_ 1438 BMS_Batterie_Voko_Anf 5000;
BA_REL_ "GenSigTimeoutTime" BU_SG_REL_ TME SG_ 1438 BMS_SollVorlauftemperatur 5000;
BA_REL_ "GenSigTimeoutTime" BU_SG_REL_ TME SG_ 1438 BMS_IstRuecklaufTemperatur_02 5000;
BA_REL_ "GenSigTimeoutTime" BU_SG_REL_ Gateway SG_ 1482 BMS_Energieinhalt 5000;
BA_REL_ "GenSigTimeoutTime" BU_SG_REL_ Gateway_PAG SG_ 1482 BMS_Energieinhalt 5000;
BA_REL_ "GenSigTimeoutTime" BU_SG_REL_ Ladegeraet_Konzern SG_ 1482 BMS_Energieinhalt 5000;
BA_REL_ "GenSigTimeoutTime" BU_SG_REL_ TME SG_ 1482 BMS_Energieinhalt 5000;
BA_REL_ "GenSigTimeoutTime" BU_SG_REL_ Gateway SG_ 1482 BMS_Ladevorgang_aktiv 5000;
BA_REL_ "GenSigTimeoutTime" BU_SG_REL_ Gateway_PAG SG_ 1482 BMS_Ladevorgang_aktiv 5000;
BA_REL_ "GenSigTimeoutTime" BU_SG_REL_ Gateway SG_ 1482 BMS_Balancing_Aktiv 5000;
BA_REL_ "GenSigTimeoutTime" BU_SG_REL_ Gateway_PAG SG_ 1482 BMS_Balancing_Aktiv 5000;
BA_REL_ "GenSigTimeoutTime" BU_SG_REL_ Gateway SG_ 1482 BMS_MaxEnergieinhalt 5000;
BA_REL_ "GenSigTimeoutTime" BU_SG_REL_ Gateway_PAG SG_ 1482 BMS_MaxEnergieinhalt 5000;
BA_REL_ "GenSigTimeoutTime" BU_SG_REL_ Ladegeraet_Konzern SG_ 1482 BMS_MaxEnergieinhalt 5000;
BA_REL_ "GenSigTimeoutTime" BU_SG_REL_ TME SG_ 1482 BMS_MaxEnergieinhalt 5000;
BA_REL_ "GenSigTimeoutTime" BU_SG_REL_ Gateway SG_ 1482 BMS_RIso_Ext 5000;
BA_REL_ "GenSigTimeoutTime" BU_SG_REL_ Gateway_PAG SG_ 1482 BMS_RIso_Ext 5000;
BA_REL_ "GenSigTimeoutTime" BU_SG_REL_ TME SG_ 1482 BMS_Fehler_KuehlkreislaufLeckage 5000;
BA_REL_ "GenSigTimeoutTime" BU_SG_REL_ DCDC_800V_PAG SG_ 2527679979 BMS_HV_Auszeit_Status 5000;
BA_REL_ "GenSigTimeoutTime" BU_SG_REL_ DCDC_HV SG_ 2527679979 BMS_HV_Auszeit_Status 5000;
BA_REL_ "GenSigTimeoutTime" BU_SG_REL_ Ladegeraet_2 SG_ 2527679979 BMS_HV_Auszeit_Status 5000;
BA_REL_ "GenSigTimeoutTime" BU_SG_REL_ Ladegeraet_Konzern SG_ 2527679979 BMS_HV_Auszeit_Status 5000;
BA_REL_ "GenSigTimeoutTime" BU_SG_REL_ LE2_3_MLBevo_LB SG_ 2527679979 BMS_HV_Auszeit_Status 5000;
BA_REL_ "GenSigTimeoutTime" BU_SG_REL_ TME SG_ 2527679979 BMS_HV_Auszeit_Status 5000;
BA_REL_ "GenSigTimeoutTime" BU_SG_REL_ DCDC_800V_PAG SG_ 2527679979 BMS_HV_Auszeit 5000;
BA_REL_ "GenSigTimeoutTime" BU_SG_REL_ DCDC_HV SG_ 2527679979 BMS_HV_Auszeit 5000;
BA_REL_ "GenSigTimeoutTime" BU_SG_REL_ Ladegeraet_2 SG_ 2527679979 BMS_HV_Auszeit 5000;
BA_REL_ "GenSigTimeoutTime" BU_SG_REL_ Ladegeraet_Konzern SG_ 2527679979 BMS_HV_Auszeit 5000;
BA_REL_ "GenSigTimeoutTime" BU_SG_REL_ LE2_3_MLBevo_LB SG_ 2527679979 BMS_HV_Auszeit 5000;
BA_REL_ "GenSigTimeoutTime" BU_SG_REL_ TME SG_ 2527679979 BMS_HV_Auszeit 5000;
BA_REL_ "GenSigTimeoutTime" BU_SG_REL_ Ladegeraet_Konzern SG_ 2527679979 BMS_Kapazitaet 5000;
BA_REL_ "GenSigTimeoutTime" BU_SG_REL_ Gateway SG_ 2527679979 BMS_SOC_Kaltstart 5000;
BA_REL_ "GenSigTimeoutTime" BU_SG_REL_ Gateway_PAG SG_ 2527679979 BMS_SOC_Kaltstart 5000;
BA_REL_ "GenSigTimeoutTime" BU_SG_REL_ Ladegeraet_Konzern SG_ 2527679979 BMS_max_Grenz_SOC 5000;
BA_REL_ "GenSigTimeoutTime" BU_SG_REL_ Gateway SG_ 2527679979 BMS_min_Grenz_SOC 5000;
BA_REL_ "GenSigTimeoutTime" BU_SG_REL_ Gateway_PAG SG_ 2527679979 BMS_min_Grenz_SOC 5000;
BA_REL_ "GenSigTimeoutTime" BU_SG_REL_ Ladegeraet_Konzern SG_ 2527679979 BMS_min_Grenz_SOC 5000;
VAL_ 3221225472 DGN_Verlernzaehler 255 "ungültiger Zählerstand oder kein gültiger Fahrzyklus" ;
VAL_ 3221225472 KBI_Kilometerstand 1048574 "Init" 1048575 "Fehler" ;
VAL_ 3221225472 UH_Monat 0 "Init" 14 "Relatives_Datum" 15 "Fehler" ;
VAL_ 3221225472 UH_Tag 0 "Init" ;
VAL_ 3221225472 Kombi_02_alt 0 "aktuell" 1 "veraltet" ;
VAL_ 3221225472 Uhrzeit_01_alt 0 "aktuell" 1 "veraltet" ;
VAL_ 3221225472 EMG_CVN_VLD 0 "ungueltig" 1 "gueltig" ;
VAL_ 3221225472 EMG_CALID_Index_01 48 "Init" ;
VAL_ 3221225472 EMG_CALID_Index_05 48 "Init" ;
VAL_ 3221225472 EMG_CALID_Index_09 48 "Init" ;
VAL_ 3221225472 EMG_CALID_Index_13 48 "Init" ;
VAL_ 3221225472 EMG_CALID_Index_02 48 "Init" ;
VAL_ 3221225472 EMG_CALID_Index_06 48 "Init" ;
VAL_ 3221225472 EMG_CALID_Index_10 48 "Init" ;
VAL_ 3221225472 EMG_CALID_Index_14 48 "Init" ;
VAL_ 3221225472 EMG_CALID_Index_03 48 "Init" ;
VAL_ 3221225472 EMG_CALID_Index_07 48 "Init" ;
VAL_ 3221225472 EMG_CALID_Index_11 48 "Init" ;
VAL_ 3221225472 EMG_CALID_Index_15 48 "Init" ;
VAL_ 3221225472 EMG_CALID_Index_04 48 "Init" ;
VAL_ 3221225472 EMG_CALID_Index_08 48 "Init" ;
VAL_ 3221225472 EMG_CALID_Index_12 48 "Init" ;
VAL_ 3221225472 EMG_CALID_Index_16 48 "Init" ;
VAL_ 3221225472 EMG_CVN_Byte_1 0 "Init" ;
VAL_ 3221225472 EMG_CVN_Byte_2 0 "Init" ;
VAL_ 3221225472 EMG_CVN_Byte_3 0 "Init" ;
VAL_ 3221225472 EMG_CVN_Byte_4 0 "Init" ;
VAL_ 3221225472 EMG_Komponentenfehler_01 0 "TestComplete_PASS" 1 "TestComplete_FAIL" 2 "TestNotComplete_PASS" ;
VAL_ 3221225472 EMG_Komponentenfehler_02 0 "TestComplete_PASS" 1 "TestComplete_FAIL" 2 "TestNotComplete_PASS" ;
VAL_ 3221225472 EMG_Komponentenfehler_03 0 "TestComplete_PASS" 1 "TestComplete_FAIL" 2 "TestNotComplete_PASS" ;
VAL_ 3221225472 EMG_Komponentenfehler_04 0 "TestComplete_PASS" 1 "TestComplete_FAIL" 2 "TestNotComplete_PASS" ;
VAL_ 3221225472 EMG_Komponentenfehler_05 0 "TestComplete_PASS" 1 "TestComplete_FAIL" 2 "TestNotComplete_PASS" ;
VAL_ 3221225472 EMG_Komponentenfehler_06 0 "TestComplete_PASS" 1 "TestComplete_FAIL" 2 "TestNotComplete_PASS" ;
VAL_ 3221225472 EMG_Komponentenfehler_07 0 "TestComplete_PASS" 1 "TestComplete_FAIL" 2 "TestNotComplete_PASS" ;
VAL_ 3221225472 EMG_Komponentenfehler_08 0 "TestComplete_PASS" 1 "TestComplete_FAIL" 2 "TestNotComplete_PASS" ;
VAL_ 3221225472 EMG_Komponentenfehler_09 0 "TestComplete_PASS" 1 "TestComplete_FAIL" 2 "TestNotComplete_PASS" ;
VAL_ 3221225472 EMG_Komponentenfehler_VLD 0 "ungueltig" 1 "gueltig" ;
VAL_ 3221225472 BR_Eingriffsmoment 1022 "Init" 1023 "Fehler" ;
VAL_ 3221225472 ESP_Diagnose 0 "ESP_nicht_in_Diagnose" 1 "ESP_in_Diagnose" ;
VAL_ 3221225472 ESC_v_Signal_Qualifier_High_Low 0 "Gueteschwelle_kleiner_1kmh" 1 "Gueteschwelle_kleiner_3kmh" 2 "Gueteschwelle_kleiner_5kmh" 3 "Gueteschwelle_kleiner_10kmh" 4 "Gueteschwelle_kleiner_20kmh" 5 "Gueteschwelle_groessergleich_20kmh" 6 "Init" 7 "Fehler" ;
VAL_ 3221225472 ESP_Vorsteuerung 0 "keine_Vorsteuerung_aktiv" 1 "Vorsteuerung_aktiv" ;
VAL_ 3221225472 OBD_Schlechtweg 0 "kein_Schlechtweg_erkannt" 1 "Schlechtweg_erkannt" ;
VAL_ 3221225472 OBD_QBit_Schlechtweg 0 "gueltiger_Wert" 1 "Ersatz_Init_oder_Fehlerwert" ;
VAL_ 3221225472 ESP_v_Signal 65533 "Unterspannung" 65534 "Init" 65535 "Fehler" ;
VAL_ 3221225472 ASR_Tastung_passiv 0 "ASR_aktiviert" 1 "ASR_passiv_getastet_oder_Schwellen_geaendert" ;
VAL_ 3221225472 ESP_Tastung_passiv 0 "ESP_aktiviert" 1 "ESP_passiv_getastet_oder_Schwellen_geaendert" ;
VAL_ 3221225472 ESP_Systemstatus 0 "iO" 1 "Fehler" ;
VAL_ 3221225472 ASR_Schalteingriff 0 "keine_Anforderung" 1 "ASR_Schaltkennfeld" 2 "Rueckschaltung" 3 "Schaltverbot" ;
VAL_ 3221225472 ESP_QBit_v_Signal 0 "gueltiger_Wert" 1 "Ersatz_Init_oder_Fehlerwert" ;
VAL_ 3221225472 ABS_Bremsung 0 "keine_ABS_Regelung" 1 "ABS_Regelung_aktiv" ;
VAL_ 3221225472 ASR_Anf 0 "keine_Anforderung" 1 "ASR_Anforderung" ;
VAL_ 3221225472 MSR_Anf 0 "keine Anfoderung" 1 "MSR-Anforderung" ;
VAL_ 3221225472 EBV_Eingriff 0 "kein_EBV_Eingriff" 1 "EBV_Eingriff" ;
VAL_ 3221225472 EDS_Eingriff 0 "kein_EDS_Eingriff" 1 "EDS_Eingriff" ;
VAL_ 3221225472 ESP_Eingriff 0 "kein_ESP_Eingriff" 1 "ESP_Eingriff_aktiv" ;
VAL_ 3221225472 ESP_ASP 0 "inaktiv" 1 "aktiv" ;
VAL_ 3221225472 ESC_Neutralschaltung 0 "keine_Anforderung" 1 "Neutralschaltung_angefordert" ;
VAL_ 3221225472 SI_Sammel_SG_Fehler 61 "Reserviert" 62 "Overflow" 63 "ungueltig" ;
VAL_ 3221225472 SI_Diagnose_Aktiv 0 "inaktiv" 1 "aktiv" ;
VAL_ 3221225472 SI_QRS_Mode 0 "QRS_Messmodus_nicht_aktiv" 1 "QRS_Messmodus_aktiv" ;
VAL_ 3221225472 SI_T_Mode 0 "Transportmodus_nicht_aktiv" 1 "Transportmodus_aktiv" ;
VAL_ 3221225472 SI_NWDF 0 "Ueberwachung_nicht_freigegeben" 1 "Ueberwachung_freigegeben" ;
VAL_ 3221225472 SI_NWDF_gueltig 0 "NWDF_wird_nicht_unterstuetzt" 1 "NWDF_wird_unterstuetzt" ;
VAL_ 3221225472 SI_Sammelfehler 0 "kein_Sammelfehler" 1 "Sammelfehler" ;
VAL_ 3221225472 GW_KD_Fehler 0 "kein_KD_Fehler" 1 "KD_Fehler" ;
VAL_ 3221225472 SI_T_Schutz 0 "Transportschutz_nicht_aktiv" 1 "Transportschutz_aktiv" ;
VAL_ 3221225472 SI_BUS_01 0 "keine_Busruhe" 1 "Busruhe" ;
VAL_ 3221225472 SI_BUS_02 0 "keine_Busruhe" 1 "Busruhe" ;
VAL_ 3221225472 SI_BUS_03 0 "keine_Busruhe" 1 "Busruhe" ;
VAL_ 3221225472 SI_BUS_04 0 "keine_Busruhe" 1 "Busruhe" ;
VAL_ 3221225472 SI_BUS_05 0 "keine_Busruhe" 1 "Busruhe" ;
VAL_ 3221225472 SI_BUS_06 0 "keine_Busruhe" 1 "Busruhe" ;
VAL_ 3221225472 SI_BUS_07 0 "keine_Busruhe" 1 "Busruhe" ;
VAL_ 3221225472 SI_BUS_08 0 "keine_Busruhe" 1 "Busruhe" ;
VAL_ 3221225472 SI_BUS_09 0 "keine_Busruhe" 1 "Busruhe" ;
VAL_ 3221225472 SI_BUS_10 0 "keine_Busruhe" 1 "Busruhe" ;
VAL_ 3221225472 SI_BUS_11 0 "keine_Busruhe" 1 "Busruhe" ;
VAL_ 3221225472 SI_BUS_12 0 "keine_Busruhe" 1 "Busruhe" ;
VAL_ 3221225472 SI_BUS_13 0 "keine_Busruhe" 1 "Busruhe" ;
VAL_ 3221225472 SI_BUS_14 0 "keine_Busruhe" 1 "Busruhe" ;
VAL_ 3221225472 SI_BUS_15 0 "keine_Busruhe" 1 "Busruhe" ;
VAL_ 3221225472 SI_Bus_Identifikation 16 "CAN_Diagnose" 17 "CAN_Antrieb" 18 "CAN_Komfort" 19 "CAN_Infotainment" 20 "CAN_Fahrwerk" 21 "CAN_Extended" 22 "CAN_Hybrid" 23 "CAN_Lade" 24 "CAN_Kombi" 25 "CAN_Komfort_2" 26 "CAN_AFS" 33 "CAN_FahrerAssistenzSysteme" 34 "CAN_Migration" 35 "CAN_Connect" 36 "CAN_AnzeigeBedienung" 37 "CAN_ElectricalVehicle" 40 "CAN_Telematik" 41 "CAN_MFL" 48 "FlexRay_A" 49 "FlexRay_B" 97 "VLAN_FAS" 98 "VLAN_Infotainment" 99 "VLAN_Connect" 100 "VLAN_Komfort" 101 "VLAN_Antrieb" 102 "VLAN_Diagnose" 103 "VLAN_Internet" 104 "VLAN_Gateway" 105 "VLAN_Remote_FC" 106 "VLAN_Connect_2" ;
VAL_ 3221225472 SI_CAB 0 "inaktiv" 1 "CAB_01__Tueren" 2 "CAB_02__Anhaenger" 4 "CAB_03__Nightvision" 8 "CAB_04__Sitzverstellung" 16 "CAB_05__Klappen" 32 "CAB_06__Infotainment" 64 "CAB_07__Sub_Infotainment" 128 "CAB_08__Anzeige" 256 "CAB_09__Laden" 512 "CAB_10__Klima" 1024 "CAB_11__FlexRay" 262144 "CAB_19_VLAN_Remote_FC" 524288 "CAB_20_VLAN_Komfort" 1048576 "CAB_21_VLAN_Internet" 2097152 "CAB_22_VLAN_Connect" 4194304 "CAB_23_VLAN_Infotainment" 8388608 "CAB_24_VLAN_FAS" ;
VAL_ 64 AB_RGS_Anst 4 "aktiv_Niveau_1" 5 "aktiv_Niveau_2" 6 "aktiv_Niveau_3" 7 "aktiv_Niveau_4" 8 "deaktiviert" ;
VAL_ 64 AB_Front_Crash 0 "kein_Front_Crash" 1 "Front_Crash" ;
VAL_ 64 AB_Heck_Crash 0 "kein_Heck_Crash" 1 "Heck_Crash" ;
VAL_ 64 AB_SF_Crash 0 "kein_Seiten_Crash_Fahrer" 1 "Seiten_Crash_Fahrer" ;
VAL_ 64 AB_SB_Crash 0 "kein_Seiten_Crash_Beifahrer" 1 "Seiten_Crash_Beifahrer" ;
VAL_ 64 AB_Rollover_Crash 0 "kein_Rollover" 1 "Rollover" ;
VAL_ 64 AB_Crash_Int 0 "kein_Crash" 1 "Crash_Intensitaet_1" 2 "Crash_Intensitaet_2_(nur_Stellgliedtest_MLB_B8)" 3 "Crash_Intensitaet_2_(nur_D4_C7_Colorado_NF_PAG__Crash_im_MLB_B8)" 4 "Crash_Intensitaet_3_(alt_VW/AUDI__Stellgliedtest_MLB_B8)" 5 "Crash_Intensitaet_3_(alt_PAG)" 7 "Crash_Intensitaet_3" ;
VAL_ 64 AB_Lampe 0 "Aus" 1 "Ein" ;
VAL_ 64 AB_Deaktiviert 0 "aktiv" 1 "deaktiviert" ;
VAL_ 64 AB_VB_deaktiviert 0 "Beifahrerairbag_aktiv" 1 "Beifahrerairbag_deaktiviert" ;
VAL_ 64 AB_Systemfehler 0 "kein_Fehler" 1 "Airbag_Systemfehler" ;
VAL_ 64 AB_Diagnose 0 "nicht_in_Diagnose" 1 "in_Diagnose" ;
VAL_ 64 AB_Stellgliedtest 0 "nicht_im_Stellgliedtest" 1 "Airbag_im_Stellgliedtest" ;
VAL_ 64 AB_Erh_Auf_VB 0 "keine_Anzeige" 1 "Beifahrerairbag_deaktiviert" 2 "Beifahrerairbag_aktiviert" 3 "nicht_definiert" ;
VAL_ 64 AB_Gurtwarn_VF 0 "keine_Warnung" 1 "Gurtwarnung_ausloesen" ;
VAL_ 64 AB_Gurtwarn_VB 0 "keine_Warnung" 1 "Gurtwarnung_ausloesen" ;
VAL_ 64 AB_Anzeige_Fussg 0 "keine_FSG_Aktion_ausgeloest" 1 "Motorhaube_offen" 2 "Systemfehler" ;
VAL_ 64 AB_Texte_AKS 0 "keine_AKS_Ausloesung" 1 "AKS_ausgeloest" 2 "AKS_Systemfehler" ;
VAL_ 64 AB_MKB_gueltig 0 "Multikollisionsbremsung_nicht_freigeschaltet" 1 "Multikollisionsbremsung_freigeschaltet" ;
VAL_ 64 AB_MKB_Anforderung 0 "Multikollisionsbremsung_nicht_angefordert" 1 "Multikollisionsbremsung_angefordert" ;
VAL_ 64 AB_Versorgungsspannung 0 "plausibel" 1 "unplausibel" ;
VAL_ 64 AB_Deaktivierung_HV 0 "keine_Deaktivierung" 1 "Deaktivierung_1" 2 "Deaktivierung_2" 3 "Deaktivierung_3" 4 "Deaktivierung_4" 5 "Deaktivierung_5" 6 "Deaktivierung_6" 7 "Fehler" ;
VAL_ 64 AB_EDR_Trigger 0 "No_Event" 1 "Start_Event" 2 "NonDeployment_Event" 3 "Deployment_Event" ;
VAL_ 64 AB_Belegung_VF 0 "nicht_verfuegbar" 1 "Fehler" 2 "nicht_belegt" 3 "belegt" ;
VAL_ 64 SC_LowSpeedCrashErkannt 0 "kein_Crash_erkannt" 1 "Crash_Frontbereich_erkannt" 2 "Crash_Heckbereich_erkannt" 3 "Crash_Front_und_Heckbereich_erkannt" ;
VAL_ 64 SC_Masterzeit 127 "Init" ;
VAL_ 2589283757 AT_VALID_TIME 0 "Init" ;
VAL_ 2589283607 AWC_Status_Spgfreiheit 0 "Init" 1 "HV_Komponente_spannungsfrei" 2 "HV_Komp_nicht_spannungsfrei" 3 "Fehler_nicht_spannungsfrei" ;
VAL_ 2589283607 AWC_IstSpannung 1022 "Init" 1023 "Fehler" ;
VAL_ 2589283607 AWC_Fehlerstatus 0 "Komponente_IO" 1 "Eingeschr_KompFkt_AWC_Lad_NIO" 2 "Eingeschr_KompFkt_reserve" 3 "Eingeschr_KompFkt_Interlock" 4 "Eingeschr_KompFkt_reserve" 5 "Eingeschr_KompFkt_reserve" 6 "Keine_Komponentenfunktion" 7 "Init" ;
VAL_ 2589283607 AWC_IstModus 0 "Standby_AWCLaden_inaktiv" 1 "AWCLaden_aktiv" 2 "AWCLaden_Verzoegerung" 3 "AWCLaden_Deaktiviert" 6 "Init" 7 "Ladefehler" ;
VAL_ 2589283607 AWC_IstStrom 510 "Init" 511 "Fehler" ;
VAL_ 2589283607 AWC_MaxLadLeistung 510 "Init" 511 "Fehler" ;
VAL_ 2589283618 AWC_Fehler_zMover 0 "kein_Fehler" 1 "Fehler" 2 "Fehler_zMover_ausgefahren" ;
VAL_ 2589283618 AWC_Panel_PositionX 2046 "Init" 2047 "Fehler" ;
VAL_ 2589283618 AWC_Panel_PositionY 2046 "Init" 2047 "Fehler" ;
VAL_ 2589283618 AWC_Panel_Verdrehwinkel 254 "Init" 255 "Fehler" ;
VAL_ 2589283618 AWC_Positionierhilfe 0 "Init" 1 "AWC_Parkhilfe_inaktiv" 2 "AWC_Parkhilfe_aktiv" ;
VAL_ 2589283618 AWC_Ladeoption_Infrastruktur 0 "Keine_Auswahl" 1 "Sofort_Laden" 2 "Timer_Laden" 3 "Ladeende_Kundenwunsch" 7 "Init" ;
VAL_ 2589283618 AWC_Spielschutz 0 "inaktiv" 1 "aktiv" ;
VAL_ 2589283618 AWC_Status 0 "StandbyState" 1 "SearchingState" 2 "FoundState" 3 "EnablingState" 4 "zMoverState" 5 "NormalOperatingState" 6 "ProductionState" 7 "DisabledState" 8 "ServiceState" 14 "Init" 15 "Fehler" ;
VAL_ 2589283618 AWC_Fehler_FOD 0 "keinFehler" 1 "Fehler" ;
VAL_ 2589283618 AWC_Fehler_Kommunikation 0 "kein_Fehler" 1 "Fehler" ;
VAL_ 2589283618 AWC_Fehler_LOP 0 "kein_Fehler" 1 "Fehler" ;
VAL_ 2589283618 AWC_Verzoegerung_FOD 0 "inaktiv" 1 "aktiv" ;
VAL_ 2589283618 AWC_Verzoegerung_LOP 0 "inaktiv" 1 "aktiv" ;
VAL_ 2589283618 AWC_Verzoegerung_Temp 0 "inaktiv" 1 "aktiv" ;
VAL_ 2589283618 AWC_Verzoegerung_zMover 0 "inaktiv" 1 "aktiv" ;
VAL_ 2589283633 AWC_Abregelung_Temperatur 0 "keine_Begrenzung" 1 "Abregelung_Temp" ;
VAL_ 2589283633 AWC_PlanAntw_Zaehler 14 "Init" 15 "Fehler" ;
VAL_ 2589283633 AWC_PlanAntw_Verlustleistung 4094 "Init" 4095 "Fehler" ;
VAL_ 2589283633 AWC_Temperatur 254 "Init" 255 "Fehler" ;
VAL_ 2589283685 AWC_CVN_VLD 0 "ungueltig" 1 "gueltig" ;
VAL_ 2589283685 AWC_CALID_Index_01 48 "Init" ;
VAL_ 2589283685 AWC_CALID_Index_05 48 "Init" ;
VAL_ 2589283685 AWC_CALID_Index_09 48 "Init" ;
VAL_ 2589283685 AWC_CALID_Index_13 48 "Init" ;
VAL_ 2589283685 AWC_CALID_Index_02 48 "Init" ;
VAL_ 2589283685 AWC_CALID_Index_06 48 "Init" ;
VAL_ 2589283685 AWC_CALID_Index_10 48 "Init" ;
VAL_ 2589283685 AWC_CALID_Index_14 48 "Init" ;
VAL_ 2589283685 AWC_CALID_Index_03 48 "Init" ;
VAL_ 2589283685 AWC_CALID_Index_07 48 "Init" ;
VAL_ 2589283685 AWC_CALID_Index_11 48 "Init" ;
VAL_ 2589283685 AWC_CALID_Index_15 48 "Init" ;
VAL_ 2589283685 AWC_CALID_Index_04 48 "Init" ;
VAL_ 2589283685 AWC_CALID_Index_08 48 "Init" ;
VAL_ 2589283685 AWC_CALID_Index_12 48 "Init" ;
VAL_ 2589283685 AWC_CALID_Index_16 48 "Init" ;
VAL_ 2589283685 AWC_CVN_Byte_1 0 "Init" ;
VAL_ 2589283685 AWC_CVN_Byte_2 0 "Init" ;
VAL_ 2589283685 AWC_CVN_Byte_3 0 "Init" ;
VAL_ 2589283685 AWC_CVN_Byte_4 0 "Init" ;
VAL_ 2589283394 AWC_Komponentenfehler_01 0 "TestComplete_PASS" 1 "TestComplete_FAIL" 2 "TestNotComplete_PASS" ;
VAL_ 2589283394 AWC_Komponentenfehler_02 0 "TestComplete_PASS" 1 "TestComplete_FAIL" 2 "TestNotComplete_PASS" ;
VAL_ 2589283394 AWC_Komponentenfehler_03 0 "TestComplete_PASS" 1 "TestComplete_FAIL" 2 "TestNotComplete_PASS" ;
VAL_ 2589283394 AWC_Komponentenfehler_04 0 "TestComplete_PASS" 1 "TestComplete_FAIL" 2 "TestNotComplete_PASS" ;
VAL_ 2589283394 AWC_Komponentenfehler_05 0 "TestComplete_PASS" 1 "TestComplete_FAIL" 2 "TestNotComplete_PASS" ;
VAL_ 2589283394 AWC_Komponentenfehler_06 0 "TestComplete_PASS" 1 "TestComplete_FAIL" 2 "TestNotComplete_PASS" ;
VAL_ 2589283394 AWC_Komponentenfehler_07 0 "TestComplete_PASS" 1 "TestComplete_FAIL" 2 "TestNotComplete_PASS" ;
VAL_ 2589283394 AWC_Komponentenfehler_08 0 "TestComplete_PASS" 1 "TestComplete_FAIL" 2 "TestNotComplete_PASS" ;
VAL_ 2589283394 AWC_Komponentenfehler_09 0 "TestComplete_PASS" 1 "TestComplete_FAIL" 2 "TestNotComplete_PASS" ;
VAL_ 2589283394 AWC_Komponentenfehler_10 0 "TestComplete_PASS" 1 "TestComplete_FAIL" 2 "TestNotComplete_PASS" ;
VAL_ 2589283394 AWC_Komponentenfehler_11 0 "TestComplete_PASS" 1 "TestComplete_FAIL" 2 "TestNotComplete_PASS" ;
VAL_ 2589283394 AWC_Komponentenfehler_12 0 "TestComplete_PASS" 1 "TestComplete_FAIL" 2 "TestNotComplete_PASS" ;
VAL_ 2589283394 AWC_Komponentenfehler_13 0 "TestComplete_PASS" 1 "TestComplete_FAIL" 2 "TestNotComplete_PASS" ;
VAL_ 2589283394 AWC_Komponentenfehler_14 0 "TestComplete_PASS" 1 "TestComplete_FAIL" 2 "TestNotComplete_PASS" ;
VAL_ 2589283394 AWC_Komponentenfehler_15 0 "TestComplete_PASS" 1 "TestComplete_FAIL" 2 "TestNotComplete_PASS" ;
VAL_ 2589283394 AWC_Komponentenfehler_16 0 "TestComplete_PASS" 1 "TestComplete_FAIL" 2 "TestNotComplete_PASS" ;
VAL_ 2589283394 AWC_Komponentenfehler_17 0 "TestComplete_PASS" 1 "TestComplete_FAIL" 2 "TestNotComplete_PASS" ;
VAL_ 2589283394 AWC_Komponentenfehler_18 0 "TestComplete_PASS" 1 "TestComplete_FAIL" 2 "TestNotComplete_PASS" ;
VAL_ 2589283394 AWC_Komponentenfehler_19 0 "TestComplete_PASS" 1 "TestComplete_FAIL" 2 "TestNotComplete_PASS" ;
VAL_ 2589283394 AWC_Komponentenfehler_20 0 "TestComplete_PASS" 1 "TestComplete_FAIL" 2 "TestNotComplete_PASS" ;
VAL_ 2589283394 AWC_Komponentenfehler_21 0 "TestComplete_PASS" 1 "TestComplete_FAIL" 2 "TestNotComplete_PASS" ;
VAL_ 2589283394 AWC_Komponentenfehler_22 0 "TestComplete_PASS" 1 "TestComplete_FAIL" 2 "TestNotComplete_PASS" ;
VAL_ 2589283394 AWC_Komponentenfehler_23 0 "TestComplete_PASS" 1 "TestComplete_FAIL" 2 "TestNotComplete_PASS" ;
VAL_ 2589283394 AWC_Komponentenfehler_24 0 "TestComplete_PASS" 1 "TestComplete_FAIL" 2 "TestNotComplete_PASS" ;
VAL_ 2589283394 AWC_Komponentenfehler_25 0 "TestComplete_PASS" 1 "TestComplete_FAIL" 2 "TestNotComplete_PASS" ;
VAL_ 2589283394 AWC_Komponentenfehler_26 0 "TestComplete_PASS" 1 "TestComplete_FAIL" 2 "TestNotComplete_PASS" ;
VAL_ 2589283394 AWC_Komponentenfehler_27 0 "TestComplete_PASS" 1 "TestComplete_FAIL" 2 "TestNotComplete_PASS" ;
VAL_ 2589283394 AWC_Komponentenfehler_28 0 "TestComplete_PASS" 1 "TestComplete_FAIL" 2 "TestNotComplete_PASS" ;
VAL_ 2589283394 AWC_Komponentenfehler_29 0 "TestComplete_PASS" 1 "TestComplete_FAIL" 2 "TestNotComplete_PASS" ;
VAL_ 2589283394 AWC_Komponentenfehler_30 0 "TestComplete_PASS" 1 "TestComplete_FAIL" 2 "TestNotComplete_PASS" ;
VAL_ 2589283394 AWC_Komponentenfehler_31 0 "TestComplete_PASS" 1 "TestComplete_FAIL" 2 "TestNotComplete_PASS" ;
VAL_ 2589283394 AWC_Komponentenfehler_VLD 0 "ungueltig" 1 "gueltig" ;
VAL_ 1615 CHA_Kombi_Texte 0 "keine_Anzeige" 1 "Text_1" 2 "Text_2" 3 "Text_3" 4 "Text_4" 5 "Text_5" 6 "Text_6" 7 "Text_7" 8 "Text_8" 9 "Text_9" 10 "Text_10" 11 "Text_11" 12 "Text_12" 13 "Text_13" 14 "Text_14" 15 "Text_15" ;
VAL_ 1615 BCM1_HUD_Eyeboxposition_Status 0 "Position_gueltig_keine_Aenderung" 1 "Drehung_im_Uhrzeigersinn" 2 "Drehung_entgegen_dem_Uhrzeigersinn" 3 "Position_ungueltig" ;
VAL_ 1615 BCM1_HUD_Taster 0 "Taster_nicht_betaetigt" 1 "Taster_betaetigt" ;
VAL_ 1615 BCM1_Stellgroesse_Kl_58s 125 "Nicht_verbaut" 126 "Init" 127 "Fehler" ;
VAL_ 1615 BCM1_LDS_Stellung 0 "Init" 1 "Stellung_0" 2 "Auto" 3 "Standlicht" 4 "Abblendlicht" 7 "Fehler" ;
VAL_ 1615 BCM1_Lichtwarn_Texte 0 "keine_Warnung" 1 "Standlichtwarnung" 2 "Parklichtwarnung" 3 "Nebelschlusslichtwarnung" ;
VAL_ 1615 CHA_Drehschalter_Modus 0 "Init_oder_kein_modus_gewaehlt" 1 "Modus_1" 2 "Modus_2" 3 "Modus_3" 4 "Modus_4" 5 "Modus_5" 6 "Modus_6" 7 "Modus_7" 8 "Modus_8" 9 "Modus_9" 10 "Modus_10" 11 "Modus_11" 12 "Modus_12" 13 "Modus_13" 14 "Modus_14" 15 "Fehler" ;
VAL_ 1615 KRH_Stufe_LED_li 0 "Aus" 1 "Stufe_1" 2 "Stufe_2" 3 "Stufe_3" ;
VAL_ 1615 KRH_Stufe_LED_re 0 "Aus" 1 "Stufe_1" 2 "Stufe_2" 3 "Stufe_3" ;
VAL_ 1615 BCM1_Spannungs_Anf 0 "keine_Anforderung" 1 "Anforderung_Stufe_1" 2 "Anforderung_Stufe_2" 3 "Anforderung_Stufe_3" ;
VAL_ 1615 LV_Laserlicht_Texte 0 "keine_Anzeige" 1 "temporaerer_Fehler" 2 "Systemfehler" ;
VAL_ 1615 BCM1_Hinweis_Lichtnachlauf 0 "inaktiv" 1 "aktiv" ;
VAL_ 1615 LV_LED_Scheinwerfer_li_def 0 "OK" 1 "defekt" ;
VAL_ 1615 LV_LED_Scheinwerfer_re_def 0 "OK" 1 "defekt" ;
VAL_ 1615 BCM1_Status_Ladeanzeige 0 "Anzeige_aktuell_nicht_moeglich" 1 "Anzeige_moeglich" 2 "Anzeige_aktiv" ;
VAL_ 1626 BCM_Bremsbelag_Sensor 0 "OK" 1 "Bremsbelag_unter_min" ;
VAL_ 1626 BCM_Bremsfluessigkeit_Sensor 0 "OK" 1 "Bremsfluessigkeit_unter_min" ;
VAL_ 1626 BCM1_Licht_Warn 0 "OK" 1 "Lichtwarnung_aktiv" ;
VAL_ 1626 BCM_Waschwasser_Sensor 0 "OK" 1 "Waschwasser_unter_min" ;
VAL_ 1626 BCM_Kuehlmittel_Sensor 0 "OK" 1 "Kuehlmittel_unter_min" ;
VAL_ 1626 BCM1_Kl_15_HW_erkannt 1 "Klemme 15 erkannt" ;
VAL_ 1626 BCM1_Kl_15_Sig_HW_erkannt 0 "KL15_HW_Signal_von_BCM1_nicht_erkannt" 1 "KL15_HW_Signal_von_BCM1_erkannt" ;
VAL_ 1626 BCM_Kuehlmittel_Sensor_02 0 "OK" 1 "Kuehlmittel_unter_min" ;
VAL_ 1626 BCM1_Hinweis_Lichtnachlauf 0 "inaktiv" 1 "aktiv" ;
VAL_ 1626 BCM_Offroad_Taste 0 "Taster_nicht_betaetigt" 1 "Taster_betaetigt" ;
VAL_ 1626 BCM_Hybrid_StSt_Taste_Fehler 0 "kein_Fehler_StSt_Taster" 1 "Fehler_StSt_Taster" ;
VAL_ 1626 BCM_Hybrid_StartStopp_Taste 0 "nicht_betaetigt" 1 "betaetigt" ;
VAL_ 1626 BCM1_Warnblink_Taster 0 "nicht_betaetigt" 1 "betaetigt" ;
VAL_ 1626 BCM1_Valet_Parking_Taster 0 "nicht_betaetigt" 1 "betaetigt" ;
VAL_ 1626 BCM1_LDS_Stellung 0 "Init" 1 "Stellung_0" 2 "Auto" 3 "Standlicht" 4 "Abblendlicht" 7 "Fehler" ;
VAL_ 1626 BCM1_Rueckfahrlicht_Schalter 0 "nicht_betaetigt" 1 "betaetigt" ;
VAL_ 1626 BCM1_MH_Schalter 0 "MH_geschlossen" 1 "MH_offen" ;
VAL_ 1626 BCM1_MH_WIV_Schalter 0 "MH_geschlossen" 1 "MH_offen" ;
VAL_ 1626 BCM_Eco_Charisma_Taste 0 "nicht_betaetigt" 1 "betaetigt" ;
VAL_ 1626 BCM1_NV_Taster 0 "Taster_nicht_betaetigt" 1 "Taster_betaetigt" ;
VAL_ 1626 BCM1_AFS_Lampe 0 "Aus" 1 "Ein" ;
VAL_ 1626 BCM1_Reisemodus_Texte 0 "keine_Anzeige" 1 "Umschaltung_auf_Linksverkehr_aktiv" 2 "Umschaltung_auf_Rechtsverkehr_aktiv" ;
VAL_ 1626 BCM1_Lichtwarn_Texte 0 "keine_Warnung" 1 "Standlichtwarnung" 2 "Parklichtwarnung" 3 "Nebelschlusslichtwarnung" ;
VAL_ 1626 Gong_TFL_Umschaltung 0 "kein_Gong" 1 "Gong_einmalig" ;
VAL_ 1626 UGDO_Function_01 0 "LED Function" 1 "Transceiver locked" 2 "reserviert" 3 "reserviert" 4 "Successful learned" 5 "reserviert" 6 "Timeout learning" 7 "Fehler" ;
VAL_ 1626 APS_Tongeber_defekt 0 "iO" 1 "defekt" ;
VAL_ 1626 BCM1_EasyEntry_Status 0 "Aus" 1 "Ein" ;
VAL_ 1626 BCM1_Lenksaeule_aktiv 0 "Lenksaeulenverstellung nicht aktiv" 1 "Lenksaeulenverstellung aktiv" ;
VAL_ 1626 BCM1_St_SW_Diebstahl_links 0 "Kein DIebstahl erkannt" 1 "Diebstahl erkannt" ;
VAL_ 1626 BCM1_St_SW_Diebstahl_rechts 0 "Kein DIebstahl erkannt" 1 "Diebstahl erkannt" ;
VAL_ 1626 BCM1_Schluesselsuche_Anf 0 "Anforderung_nicht_aktiv" 1 "Anforderung_aktiv" ;
VAL_ 1626 BCM1_Fahrlicht_Hinweis 0 "kein_Fahrlicht_Hinweis" 1 "Fahrlicht_Hinweis" ;
VAL_ 1626 BCM_HDF_betaetigt 0 "nicht_betaetigt" 1 "betaetigt" ;
VAL_ 401 BMS_IstStrom_02 4094 "Init" 4095 "Fehler" ;
VAL_ 401 BMS_IstSpannung 4094 "Init" 4095 "Fehler" ;
VAL_ 401 BMS_Spannung_ZwKr 2046 "Init" 2047 "Fehler" ;
VAL_ 401 BMS_SOC_HiRes 2046 "Init" 2047 "Fehler" ;
VAL_ 401 BMS_IstStrom_02_OffsetVZ 0 "Minus" 1 "Plus" ;
VAL_ 417 BMS_MaxDyn_EntladeStrom_02 2046 "Init" 2047 "Fehler" ;
VAL_ 417 BMS_MaxDyn_LadeStrom_02 2046 "Init" 2047 "Fehler" ;
VAL_ 417 BMS_Min_EntladeSpannung 1022 "Init" 1023 "Fehler" ;
VAL_ 417 BMS_MinDyn_EntladeSpannung 1023 "Init" ;
VAL_ 417 BMS_MinDyn_LadeSpannung 1023 "Init" ;
VAL_ 925 BMS_Leerlaufspannung 1023 "Init" ;
VAL_ 925 BMS_Max_LadeSpannung 1022 "Init" 1023 "Fehler" ;
VAL_ 925 BMS_MaxPred_EntladeStrom_02 2046 "Init" 2047 "Fehler" ;
VAL_ 925 BMS_MaxPred_LadeStrom_02 2046 "Init" 2047 "Fehler" ;
VAL_ 925 BMS_MinPred_EntladeSpannung 1023 "Init" ;
VAL_ 925 BMS_MinPred_LadeSpannung 1023 "Init" ;
VAL_ 1442 BMS_Status_ServiceDisconnect 0 "gesteckt" 1 "gezogen" ;
VAL_ 1442 BMS_Status_Spgfreiheit 0 "Init" 1 "HV_Komponente_spannungsfrei" 2 "HV_Komp_nicht_spannungsfrei" 3 "Fehler_nicht_spannungsfrei" ;
VAL_ 1442 BMS_OBD_Lampe_Anf 0 "kein_MIL_Request" 1 "MIL_Request" ;
VAL_ 1442 BMS_IstModus 0 "HV_inaktiv" 1 "Fahren_HV_aktiv" 2 "stBalancing" 3 "externes_Laden" 4 "AC_Laden" 5 "Error_Batt" 6 "DC_Laden" 7 "Init" ;
VAL_ 1442 BMS_Fehlerstatus 0 "Komponente_IO" 1 "Eingeschr_KompFkt_Isofehler_I" 2 "Eingeschr_KompFkt_Isofehler_II" 3 "Eingeschr_KompFkt_Interlock" 4 "Eingeschr_KompFkt_SD" 5 "Eingeschr_KompFkt_Leistungsred" 6 "Keine_Komponentenfunktion" 7 "Init" ;
VAL_ 1442 BMS_Kapazitaet_02 2047 "Init" ;
VAL_ 1442 BMS_Soll_SOC_HiRes 2046 "Init" 2047 "Fehler" ;
VAL_ 687 BMS_As_Entladezaehler_Ueberlauf 0 "kein_Ueberlauf" 1 "Ueberlauf" ;
VAL_ 687 BMS_Rekuperation_Ueberlauf 0 "kein_Ueberlauf" 1 "Ueberlauf" ;
VAL_ 687 BMS_Verbrauch_Ueberlauf 0 "kein_Ueberlauf" 1 "Ueberlauf" ;
VAL_ 1438 BMS_Temperierung_Anf 0 "hoher_Kuehlbedarf" 1 "mittlerer_Kuehlbedarf" 2 "niedriger_Kuehlbedarf" 3 "kein_Temperierungsbedarf_Init" 4 "niedriger_Heizbedarf" 5 "mittlerer_Heizbedarf" 6 "hoher_Heizbedarf" 7 "Umwaelzungsbedarf" ;
VAL_ 1438 BMS_Status_Ventil 0 "Ventil_nicht_angesteuert" 1 "Ventil_angesteuert" 2 "reserviert" 3 "reserviert" 4 "reserviert" 5 "Ventil_nicht_verbaut" 6 "Init" 7 "Fehler" ;
VAL_ 1438 BMS_Soll_PWM_Pumpe 14 "Fehler" 15 "Init" ;
VAL_ 1438 BMS_Temperatur 254 "Init" 255 "Fehler" ;
VAL_ 1438 BMS_IstVorlaufTemperatur 254 "Init" 255 "Fehler" ;
VAL_ 1438 BMS_Fehler_NTKreis 0 "kein_Fehler" 1 "Fehler" ;
VAL_ 1438 BMS_Fehlerstatus_EWP_02 0 "Diagnose_nicht_durchgefuehrt" 1 "Pumpe_iO" 2 "Diagnose_laeuft" 3 "Pumpe_iO_Diagnose_laeuft" 4 "Blockade_Trockenlauf" 6 "Blockade_Trockenlauf_Diag_laeuft" ;
VAL_ 1438 BMS_SollVolumenstrom 62 "Init" 63 "Fehler" ;
VAL_ 1438 BMS_Batterie_Voko_Anf 0 "keine_Voko_angefordert" 1 "Voko_angefordert" ;
VAL_ 1438 BMS_SollVorlauftemperatur 254 "Init" 255 "Fehler" ;
VAL_ 1438 BMS_IstRuecklaufTemperatur_02 254 "Init" 255 "Fehler" ;
VAL_ 1482 BMS_Energieinhalt 2046 "Init" 2047 "Fehler" ;
VAL_ 1482 BMS_Ladevorgang_aktiv 0 "inaktiv" 1 "aktiv" ;
VAL_ 1482 BMS_Batteriediagnose 1 "Anzeige_Batterie" 4 "Anzeige_Batterie_OK" 5 "Anzeige_Batterie_Laden" 6 "Anzeige_Batterie_Pruefen" 7 "Fehler" ;
VAL_ 1482 BMS_Freig_max_Performanz 0 "Init" 1 "verfuegbar" 2 "nicht_verfuegbar" 3 "eingeschraenkt_verfuegbar" ;
VAL_ 1482 BMS_Balancing_Aktiv 0 "Init" 1 "aktiv" 2 "nicht_aktiv" ;
VAL_ 1482 BMS_MaxEnergieinhalt 2046 "Init" 2047 "Fehler" ;
VAL_ 1482 BMS_Ausgleichsladung_Anf 1 "Balancing_Request" ;
VAL_ 1482 BMS_Gesamtst_Spgfreiheit 0 "Funktion_nicht_aktiviert" 1 "HV_System_spannungsfrei" 2 "HV_System_nicht_spannungsfrei" 3 "Fehler_nicht_spannungsfrei" ;
VAL_ 1482 BMS_RIso_Ext 4094 "Init" 4095 "Fehler" ;
VAL_ 1482 BMS_KundenWarnung 0 "keine_Warnung" 1 "Warnung_Temperatur_Level1" 2 "Warnung_Temperatur_Level2" ;
VAL_ 1482 BMS_Fehler_KuehlkreislaufLeckage 0 "kein_Fehler" 1 "Fehler_KuehlkreislaufLeckage" ;
VAL_ 2527679979 BMS_HV_Auszeit_Status 0 "Abstellzeit_nicht_berechnet" 1 "Abstellzeit_berechnet" 2 "Abstellzeit_Minimalwert" 3 "Abstellzeit_ungültig" ;
VAL_ 2527679979 BMS_HV_Auszeit 510 "Init" 511 "Fehler" ;
VAL_ 2527679979 BMS_Kapazitaet 2047 "Init" ;
VAL_ 2527679979 BMS_SOC_Kaltstart 2046 "Init" 2047 "Fehler" ;
VAL_ 2527679979 BMS_max_Grenz_SOC 31 "Init" ;
VAL_ 2527679979 BMS_min_Grenz_SOC 31 "Init" ;
